VERSION ""

NS_ :

BS_:

BU_:

BO_ 989 CP_loggingSlow: 8 Vector__XXX
 SG_ CP_doorPushLockoutActive m4 : 63|1@1+ (1,0) [0|0] "" Vector__XXX
 SG_ CP_faultLineSetByCP m2 : 62|1@1+ (1,0) [0|0] "" Vector__XXX
 SG_ CP_pilotWakeCounter m6 : 61|3@1+ (1,0) [0|0] "" Vector__XXX
 SG_ CP_proximityWakeCounter m5 : 61|3@1+ (1,0) [0|0] "" Vector__XXX
 SG_ CP_wakeOnPushCounter m4 : 60|3@1+ (1,0) [0|0] "" Vector__XXX
 SG_ CP_backCover2State m1 : 59|3@1+ (1,0) [0|0] "" Vector__XXX
 SG_ CP_inletHeaterDuty m3 : 57|7@1+ (1,0) [0|0] "" Vector__XXX
 SG_ CP_backCoverState m1 : 56|3@1+ (1,0) [0|0] "" Vector__XXX
 SG_ CP_doorCloseLimiterMaxRequestType m5 : 56|5@1+ (1,0) [0|0] "" Vector__XXX
 SG_ CP_uhfDoorRequestCounts m7 : 56|5@1+ (1,0) [0|0] "" Vector__XXX
 SG_ CP_inletHeaterState m3 : 55|2@1+ (1,0) [0|0] "" Vector__XXX
 SG_ CP_acNumRetries m6 : 53|8@1+ (1,0) [0|0] "" Vector__XXX
 SG_ CP_doorCloseLimiterMaxCount m5 : 52|4@1+ (1,0) [0|0] "" Vector__XXX
 SG_ CP_faultLineV m2 : 52|10@1+ (0.004550576735092864,0) [0|0] "" Vector__XXX
 SG_ CP_inlet2HarnessIdValue m3 : 52|3@1+ (1,0) [0|0] "" Vector__XXX
 SG_ CP_inlet2HarnessIdState m3 : 50|2@1+ (1,0) [0|0] "" Vector__XXX
 SG_ CP_inlet2HarnessV m0 : 50|14@1+ (0.001,0) [0|0] "" Vector__XXX
 SG_ CP_doorOpenLimiterMaxRequestType m5 : 48|4@1+ (1,0) [0|0] "" Vector__XXX
 SG_ CP_sensorExtV m1 : 48|8@1+ (0.01968504,0) [0|0] "" Vector__XXX
 SG_ CP_inlet1HarnessIdValue m3 : 47|3@1+ (1,0) [0|0] "" Vector__XXX
 SG_ CP_inlet1HarnessIdState m3 : 45|2@1+ (1,0) [0|0] "" Vector__XXX
 SG_ CP_doorOpenLimiterMaxCount m5 : 44|4@1+ (1,0) [0|0] "" Vector__XXX
 SG_ CP_nvm_pilotDiodeFaultCount m5 : 41|3@1+ (1,0) [0|0] "" Vector__XXX
 SG_ CP_nvm_badPilotDiodeDetected m5 : 40|1@1+ (1,0) [0|0] "" Vector__XXX
 SG_ CP_pilotHighValue_intervalMin10s m2 : 40|12@1- (0.01,0) [0|0] "" Vector__XXX
 SG_ CP_plcV m1 : 40|8@1+ (0.01294118,0) [0|0] "" Vector__XXX
 SG_ CP_nvm_doorPresentValid m5 : 39|1@1+ (1,0) [0|0] "" Vector__XXX
 SG_ CP_acNextRetryTimeoutS m6 : 38|15@1+ (1,0) [0|0] "" Vector__XXX
 SG_ CP_nvm_doorPresent m5 : 38|1@1+ (1,0) [0|0] "" Vector__XXX
 SG_ CP_nvm_doorOpen m5 : 37|1@1+ (1,0) [0|0] "" Vector__XXX
 SG_ CP_doorId_intervalMax10s m4 : 36|8@1+ (0.0196078431372549,0) [0|0] "" Vector__XXX
 SG_ CP_inlet1HarnessV m0 : 36|14@1+ (0.001,0) [0|0] "" Vector__XXX
 SG_ CP_latchI m3 : 33|12@1+ (0.0025,0) [0|0] "" Vector__XXX
 SG_ CP_ivledV m1 : 32|8@1+ (0.01968504,0) [0|0] "" Vector__XXX
 SG_ CP_doorId_intervalMin10s m4 : 28|8@1+ (0.0196078431372549,0) [0|0] "" Vector__XXX
 SG_ CP_inductiveSensorBaseline m7 : 28|28@1+ (0.08083879947662354,0) [0|0] "" Vector__XXX
 SG_ CP_ivledState m1 : 28|2@1+ (1,0) [0|0] "" Vector__XXX
 SG_ CP_pilotHighValue_intervalMax10s m2 : 28|12@1- (0.01,0) [0|0] "" Vector__XXX
 SG_ CP_UHF_selfTestRssi m3 : 25|8@1+ (1,0) [0|0] "" Vector__XXX
 SG_ CP_acRetryTimeoutS m6 : 23|15@1+ (1,0) [0|0] "" Vector__XXX
 SG_ CP_nvm_doorCloseCycles m5 : 21|16@1+ (1,0) [0|0] "" Vector__XXX
 SG_ CP_proximityV_intervalMin10s m0 : 20|16@1+ (0.0001,0) [0|0] "" Vector__XXX
 SG_ CP_refVoltage m4 : 20|8@1+ (0.0070588235,0) [0|0] "" Vector__XXX
 SG_ CP_doorButtonPressDurationMs m7 : 18|10@1+ (1,0) [0|0] "" Vector__XXX
 SG_ CP_UHF_rxNumBytes m3 : 17|8@1+ (1,0) [0|0] "" Vector__XXX
 SG_ CP_UHF_rxOverflow m3 : 16|1@1+ (1,0) [0|0] "" Vector__XXX
 SG_ CP_backCover2Counts m1 : 16|12@1+ (0.025,0) [0|0] "" Vector__XXX
 SG_ CP_pilotLowValue_intervalMin10s m2 : 16|12@1- (0.01,0) [0|0] "" Vector__XXX
 SG_ CP_tlsMemoryUsage_intervalMin10s m6 : 16|7@1+ (0.7874015748031497,0) [0|0] "" Vector__XXX
 SG_ CP_boardTemperature m4 : 12|8@1+ (1.29411764706,-50) [0|0] "" Vector__XXX
 SG_ CP_cpuUtilization_intervalMin10s m7 : 11|7@1+ (0.7874015748031497,0) [0|0] "" Vector__XXX
 SG_ CP_UHF_rssi m3 : 8|8@1+ (1,0) [0|0] "" Vector__XXX
 SG_ CP_tlsMemoryUsage_intervalMax10s m6 : 8|7@1+ (0.7874015748031497,0) [0|0] "" Vector__XXX
 SG_ CP_nvm_doorOpenCycles m5 : 5|16@1+ (1,0) [0|0] "" Vector__XXX
 SG_ CP_5vSwV m4 : 4|8@1+ (0.027450980392156862,0) [0|0] "" Vector__XXX
 SG_ CP_UHF_chipState m3 : 4|3@1+ (1,0) [0|0] "" Vector__XXX
 SG_ CP_backCoverCounts m1 : 4|12@1+ (0.025,0) [0|0] "" Vector__XXX
 SG_ CP_cpuUtilization_intervalMax10s m7 : 4|7@1+ (0.7874015748031497,0) [0|0] "" Vector__XXX
 SG_ CP_nvm_dataValid m5 : 4|1@1+ (1,0) [0|0] "" Vector__XXX
 SG_ CP_pilotLowValue_intervalMax10s m2 : 4|12@1- (0.01,0) [0|0] "" Vector__XXX
 SG_ CP_proximityV_intervalMax10s m0 : 4|16@1+ (0.0001,0) [0|0] "" Vector__XXX
 SG_ CP_loggingSlowSelect M : 0|4@1+ (1,0) [0|0] "" Vector__XXX

BO_ 991 UI_status2: 8 Vector__XXX
 SG_ UI_connectivityStandbyActive : 63|1@1+ (1,0) [0|0] "" Vector__XXX
 SG_ UI_sapClients : 62|1@1+ (1,0) [0|0] "" Vector__XXX
 SG_ UI_sapActive : 61|1@1+ (1,0) [0|0] "" Vector__XXX
 SG_ UI_wakeOnIPActive : 60|1@1+ (1,0) [0|0] "" Vector__XXX
 SG_ UI_sentryModeCameraDetection : 59|1@1+ (1,0) [0|0] "" Vector__XXX
 SG_ UI_fullScreenMode : 58|1@1+ (1,0) [0|0] "" Vector__XXX
 SG_ UI_summonDeviceIndex : 56|2@1+ (1,0) [0|0] "" Vector__XXX
 SG_ UI_selfParkState : 48|8@1+ (1,0) [0|0] "" Vector__XXX
 SG_ UI_sohHealthStatus : 46|2@1+ (1,0) [0|0] "" Vector__XXX
 SG_ UI_wifiBtModuleType : 43|3@1+ (1,0) [0|0] "" Vector__XXX
 SG_ UI_autoshiftDRState : 40|3@1+ (1,0) [0|0] "" Vector__XXX
 SG_ UI_phoneLeftInCabin : 39|1@1+ (1,0) [0|0] "" Vector__XXX
 SG_ UI_mobileAppConnected : 38|1@1+ (1,0) [0|0] "" Vector__XXX
 SG_ UI_autopilotSentryRequest : 37|1@1+ (1,0) [0|0] "" Vector__XXX
 SG_ UI_sentryModeState : 34|3@1+ (1,0) [0|0] "" Vector__XXX
 SG_ UI_linkState : 32|2@1+ (1,0) [0|0] "" Vector__XXX
 SG_ UI_activeTouchPoints : 24|8@1+ (1,0) [0|0] "" Vector__XXX
 SG_ UI_userActivity : 23|1@1+ (1,0) [0|0] "" Vector__XXX
 SG_ UI_displayInDarkMode : 22|1@1+ (1,0) [0|0] "" Vector__XXX
 SG_ UI_locatedAtFavorite : 21|1@1+ (1,0) [0|0] "" Vector__XXX
 SG_ UI_locatedAtWork : 20|1@1+ (1,0) [0|0] "" Vector__XXX
 SG_ UI_locatedAtHome : 19|1@1+ (1,0) [0|0] "" Vector__XXX
 SG_ UI_validDeviceForEUSummon : 18|1@1+ (1,0) [0|0] "" Vector__XXX
 SG_ UI_touchDetected : 17|1@1+ (1,0) [0|0] "" Vector__XXX
 SG_ UI_userRequestSnapshot : 16|1@1+ (1,0) [0|0] "" Vector__XXX
 SG_ UI_mobileAppStepCount : 0|16@1+ (1,0) [0|0] "" Vector__XXX

BO_ 994 VCLEFT_lightStatus: 8 Vector__XXX
 SG_ VCLEFT_tailLightOutageStatus : 51|1@1+ (1,0) [0|0] "" Vector__XXX
 SG_ VCLEFT_reverseTrailerLightStatus : 49|2@1+ (1,0) [0|0] "" Vector__XXX
 SG_ VCLEFT_rideHeightSensorFault : 48|1@1+ (1,0) [0|0] "" Vector__XXX
 SG_ VCLEFT_trailerDetected : 46|2@1+ (1,0) [0|0] "" Vector__XXX
 SG_ VCLEFT_rearRideHeight : 36|8@1- (1,0) [0|0] "" Vector__XXX
 SG_ VCLEFT_frontRideHeight : 28|8@1- (1,0) [0|0] "" Vector__XXX
 SG_ VCLEFT_fogTrailerLightStatus : 26|2@1+ (1,0) [0|0] "" Vector__XXX
 SG_ VCLEFT_tailTrailerLightStatus : 24|2@1+ (1,0) [0|0] "" Vector__XXX
 SG_ VCLEFT_brakeTrailerLightStatus : 22|2@1+ (1,0) [0|0] "" Vector__XXX
 SG_ VCLEFT_rightTrnTrailerLightStatus : 20|2@1+ (1,0) [0|0] "" Vector__XXX
 SG_ VCLEFT_leftTurnTrailerLightStatus : 18|2@1+ (1,0) [0|0] "" Vector__XXX
 SG_ VCLEFT_RRMapLightSwitchPressed : 17|1@1+ (1,0) [0|0] "" Vector__XXX
 SG_ VCLEFT_RLMapLightSwitchPressed : 16|1@1+ (1,0) [0|0] "" Vector__XXX
 SG_ VCLEFT_FRMapLightSwitchPressed : 15|1@1+ (1,0) [0|0] "" Vector__XXX
 SG_ VCLEFT_FLMapLightSwitchPressed : 14|1@1+ (1,0) [0|0] "" Vector__XXX
 SG_ VCLEFT_RRMapLightStatus : 12|2@1+ (1,0) [0|0] "" Vector__XXX
 SG_ VCLEFT_RLMapLightStatus : 10|2@1+ (1,0) [0|0] "" Vector__XXX
 SG_ VCLEFT_FRMapLightStatus : 8|2@1+ (1,0) [0|0] "" Vector__XXX
 SG_ VCLEFT_FLMapLightStatus : 6|2@1+ (1,0) [0|0] "" Vector__XXX
 SG_ VCLEFT_turnSignalStatus : 4|2@1+ (1,0) [0|0] "" Vector__XXX
 SG_ VCLEFT_tailLightStatus : 2|2@1+ (1,0) [0|0] "" Vector__XXX
 SG_ VCLEFT_brakeLightStatus : 0|2@1+ (1,0) [0|0] "" Vector__XXX

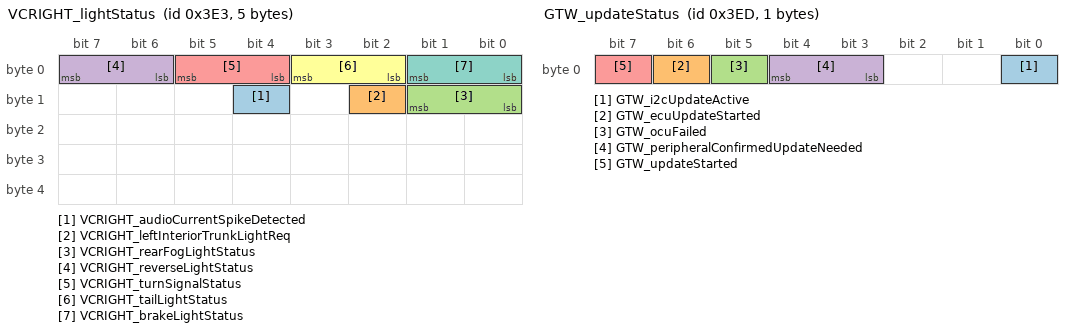
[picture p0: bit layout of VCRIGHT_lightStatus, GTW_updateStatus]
BO_ 995 VCRIGHT_lightStatus: 5 Vector__XXX
 SG_ VCRIGHT_audioCurrentSpikeDetected : 12|1@1+ (1,0) [0|0] "" Vector__XXX
 SG_ VCRIGHT_leftInteriorTrunkLightReq : 10|1@1+ (1,0) [0|0] "" Vector__XXX
 SG_ VCRIGHT_rearFogLightStatus : 8|2@1+ (1,0) [0|0] "" Vector__XXX
 SG_ VCRIGHT_reverseLightStatus : 6|2@1+ (1,0) [0|0] "" Vector__XXX
 SG_ VCRIGHT_turnSignalStatus : 4|2@1+ (1,0) [0|0] "" Vector__XXX
 SG_ VCRIGHT_tailLightStatus : 2|2@1+ (1,0) [0|0] "" Vector__XXX
 SG_ VCRIGHT_brakeLightStatus : 0|2@1+ (1,0) [0|0] "" Vector__XXX

BO_ 1001 DAS_bodyControls: 8 Vector__XXX
 SG_ DAS_bodyControlsChecksum : 56|8@1+ (1,0) [0|0] "" Vector__XXX
 SG_ DAS_bodyControlsCounter : 52|4@1+ (1,0) [0|0] "" Vector__XXX
 SG_ DAS_restrictDoorReleaseRight : 51|1@1+ (1,0) [0|0] "" Vector__XXX
 SG_ DAS_restrictDoorReleaseLeft : 50|1@1+ (1,0) [0|0] "" Vector__XXX
 SG_ DAS_adaptiveHighBeamIsFaulted : 49|1@1+ (1,0) [0|0] "" Vector__XXX
 SG_ DAS_rPillarCamHeaterDutyCycle : 45|4@1+ (0.06666666666666667,0) [0|0] "" Vector__XXX
 SG_ DAS_enableIcrDataCollection : 44|1@1+ (1,0) [0|0] "" Vector__XXX
 SG_ DAS_drivePowerStateRequest : 43|1@1+ (1,0) [0|0] "" Vector__XXX
 SG_ DAS_driverDomeLightRequest : 39|1@1+ (1,0) [0|0] "" Vector__XXX
 SG_ DAS_forwardRadarPowerRequest : 38|1@1+ (1,0) [0|0] "" Vector__XXX
 SG_ DAS_turnIndicatorRequestReason : 33|5@1+ (1,0) [0|0] "" Vector__XXX
 SG_ DAS_autoWiperState : 30|3@1+ (1,0) [0|0] "" Vector__XXX
 SG_ DAS_overrideWiperSetting : 29|1@1+ (1,0) [0|0] "" Vector__XXX
 SG_ DAS_ulcConfirmationRequestActive : 28|1@1+ (1,0) [0|0] "" Vector__XXX
 SG_ DAS_wiperWashRequest : 27|1@1+ (1,0) [0|0] "" Vector__XXX
 SG_ DAS_mirrorFoldRequest : 25|2@1+ (1,0) [0|0] "" Vector__XXX
 SG_ DAS_ahlbOverride : 24|1@1+ (1,0) [0|0] "" Vector__XXX
 SG_ DAS_radarHeaterRequest : 23|1@1+ (1,0) [0|0] "" Vector__XXX
 SG_ DAS_dynamicBrakeLightRequest : 22|1@1+ (1,0) [0|0] "" Vector__XXX
 SG_ DAS_forwardCamHeaterDutyCycle : 18|4@1+ (0.06666666666666667,0) [0|0] "" Vector__XXX
 SG_ DAS_highLowBeamOffReason : 15|3@1+ (1,0) [0|0] "" Vector__XXX
 SG_ DAS_heaterRequest : 13|2@1+ (1,0) [0|0] "" Vector__XXX
 SG_ DAS_highLowBeamDecision : 11|2@1+ (1,0) [0|0] "" Vector__XXX
 SG_ DAS_turnIndicatorRequest : 8|3@1+ (1,0) [0|0] "" Vector__XXX
 SG_ DAS_wiperSpeed : 4|4@1+ (1,0) [0|0] "" Vector__XXX
 SG_ DAS_hazardLightRequest : 2|2@1+ (1,0) [0|0] "" Vector__XXX
 SG_ DAS_headlightRequest : 0|2@1+ (1,0) [0|0] "" Vector__XXX

BO_ 1005 GTW_updateStatus: 1 Vector__XXX
 SG_ GTW_i2cUpdateActive : 0|1@0+ (1,0) [0|0] "" Vector__XXX
 SG_ GTW_ecuUpdateStarted : 6|1@1+ (1,0) [0|0] "" Vector__XXX
 SG_ GTW_ocuFailed : 5|1@1+ (1,0) [0|0] "" Vector__XXX
 SG_ GTW_peripheralConfirmedUpdateNeeded : 4|2@0+ (1,0) [0|0] "" Vector__XXX
 SG_ GTW_updateStarted : 7|1@0+ (1,0) [0|0] "" Vector__XXX

BO_ 1010 BMS_kwhCountersMultiplexed: 8 Vector__XXX
 SG_ BMS_kwhChargeTotalModule1 m4 : 36|28@1+ (0.001,0) [0|0] "" Vector__XXX
 SG_ BMS_kwhChargeTotalModule2 m6 : 36|28@1+ (0.001,0) [0|0] "" Vector__XXX
 SG_ BMS_kwhChargeTotalModule3 m8 : 36|28@1+ (0.001,0) [0|0] "" Vector__XXX
 SG_ BMS_kwhChargeTotalModule4 m10 : 36|28@1+ (0.001,0) [0|0] "" Vector__XXX
 SG_ BMS_kwhDcChargeTotalModule1 m5 : 36|28@1+ (0.001,0) [0|0] "" Vector__XXX
 SG_ BMS_kwhDcChargeTotalModule2 m7 : 36|28@1+ (0.001,0) [0|0] "" Vector__XXX
 SG_ BMS_kwhDcChargeTotalModule3 m9 : 36|28@1+ (0.001,0) [0|0] "" Vector__XXX
 SG_ BMS_kwhDcChargeTotalModule4 m11 : 36|28@1+ (0.001,0) [0|0] "" Vector__XXX
 SG_ BMS_acChargerKwhTotal m0 : 8|32@1+ (0.001,0) [0|0] "" Vector__XXX
 SG_ BMS_dcChargerKwhTotal m1 : 8|32@1+ (0.001,0) [0|0] "" Vector__XXX
 SG_ BMS_kwhAcChargeTotalModule1 m5 : 8|28@1+ (0.001,0) [0|0] "" Vector__XXX
 SG_ BMS_kwhAcChargeTotalModule2 m7 : 8|28@1+ (0.001,0) [0|0] "" Vector__XXX
 SG_ BMS_kwhAcChargeTotalModule3 m9 : 8|28@1+ (0.001,0) [0|0] "" Vector__XXX
 SG_ BMS_kwhAcChargeTotalModule4 m11 : 8|28@1+ (0.001,0) [0|0] "" Vector__XXX
 SG_ BMS_kwhDischargeTotalModule1 m4 : 8|28@1+ (0.001,0) [0|0] "" Vector__XXX
 SG_ BMS_kwhDischargeTotalModule2 m6 : 8|28@1+ (0.001,0) [0|0] "" Vector__XXX
 SG_ BMS_kwhDischargeTotalModule3 m8 : 8|28@1+ (0.001,0) [0|0] "" Vector__XXX
 SG_ BMS_kwhDischargeTotalModule4 m10 : 8|28@1+ (0.001,0) [0|0] "" Vector__XXX
 SG_ BMS_kwhDriveDischargeTotal m3 : 8|32@1+ (0.001,0) [0|0] "" Vector__XXX
 SG_ BMS_kwhRegenChargeTotal m2 : 8|32@1+ (0.001,0) [0|0] "" Vector__XXX
 SG_ BMS_kwhCounter_Id M : 0|4@1+ (1,0) [0|0] "" Vector__XXX

BO_ 1013 VCFRONT_lighting: 8 Vector__XXX
 SG_ VCFRONT_indicatorRightInternal : 52|2@1+ (1,0) [0|0] "" Vector__XXX
 SG_ VCFRONT_indicatorLeftInternal : 50|2@1+ (1,0) [0|0] "" Vector__XXX
 SG_ VC_fastFlashHazardsActive : 49|1@1+ (1,0) [0|0] "" Vector__XXX
 SG_ VCFRONT_lightingCustomState : 44|5@1+ (1,0) [0|0] "" Vector__XXX
 SG_ VCFRONT_highBeamLatchingState : 42|2@1+ (1,0) [0|0] "" Vector__XXX
 SG_ VCFRONT_turnIndicatorStalk : 40|2@1+ (1,0) [0|0] "" Vector__XXX
 SG_ VCFRONT_headlightsReadyOrTimedOut : 39|1@1+ (1,0) [0|0] "" Vector__XXX
 SG_ VCFRONT_frontFogFunctionState : 38|1@1+ (1,0) [0|0] "" Vector__XXX
 SG_ VCFRONT_latchedHighBeamsFunctionState : 37|1@1+ (1,0) [0|0] "" Vector__XXX
 SG_ VCFRONT_intHighBeamsFunctionState : 36|1@1+ (1,0) [0|0] "" Vector__XXX
 SG_ VCFRONT_lightingCoreState : 32|4@1+ (1,0) [0|0] "" Vector__XXX
 SG_ VCFRONT_dynamicBrakeLightState : 30|2@1+ (1,0) [0|0] "" Vector__XXX
 SG_ VCFRONT_highBeamControlState : 28|2@1+ (1,0) [0|0] "" Vector__XXX
 SG_ VCFRONT_hazardSwitchBacklight : 27|1@1+ (1,0) [0|0] "" Vector__XXX
 SG_ VCFRONT_courtesyLightingRequest : 24|1@1+ (1,0) [0|0] "" Vector__XXX
 SG_ VCFRONT_switchLightingBrightness : 16|8@1+ (0.5,0) [0|0] "" Vector__XXX
 SG_ VCFRONT_ambientLightingBrightnes : 8|8@1+ (0.5,0) [0|0] "" Vector__XXX
 SG_ VCFRONT_hazardLightRequest : 4|4@1+ (1,0) [0|0] "" Vector__XXX
 SG_ VCFRONT_indicatorRightRequest : 2|2@1+ (1,0) [0|0] "" Vector__XXX
 SG_ VCFRONT_indicatorLeftRequest : 0|2@1+ (1,0) [0|0] "" Vector__XXX

BO_ 1014 VCFRONT_lightStatus: 8 Vector__XXX
 SG_ VC_hcmrMigrationWindowOpen m0 : 63|1@1+ (1,0) [0|0] "" Vector__XXX
 SG_ VC_hcmrMigrationStallDetectionEnabled m0 : 62|1@1+ (1,0) [0|0] "" Vector__XXX
 SG_ VC_hcmrMigrationMigrationNotStarted m0 : 61|1@1+ (1,0) [0|0] "" Vector__XXX
 SG_ VC_hcmrMigrationOnLVSupport m0 : 60|1@1+ (1,0) [0|0] "" Vector__XXX
 SG_ VC_hcmrMigrationVehicleUpdateActive m0 : 59|1@1+ (1,0) [0|0] "" Vector__XXX
 SG_ VC_hcmrMigrationOTAStateNotActive m0 : 58|1@1+ (1,0) [0|0] "" Vector__XXX
 SG_ VC_hcmrMigrationOTAStateWasActive m0 : 57|1@1+ (1,0) [0|0] "" Vector__XXX
 SG_ VC_hcmrMigrationValidWeather m0 : 56|1@1+ (1,0) [0|0] "" Vector__XXX
 SG_ VCFRONT_headlampRoadClass m1 : 55|2@1+ (1,0) [0|0] "" Vector__XXX
 SG_ VC_hcmlMigrationWindowOpen m0 : 55|1@1+ (1,0) [0|0] "" Vector__XXX
 SG_ VC_hcmlMigrationStallDetectionEnabled m0 : 54|1@1+ (1,0) [0|0] "" Vector__XXX
 SG_ VC_hcmlMigrationMigrationNotStarted m0 : 53|1@1+ (1,0) [0|0] "" Vector__XXX
 SG_ VC_hcmlMigrationOnLVSupport m0 : 52|1@1+ (1,0) [0|0] "" Vector__XXX
 SG_ VC_hcmlMigrationVehicleUpdateActive m0 : 51|1@1+ (1,0) [0|0] "" Vector__XXX
 SG_ VC_hcmlMigrationOTAStateNotActive m0 : 50|1@1+ (1,0) [0|0] "" Vector__XXX
 SG_ VC_hcmlMigrationOTAStateWasActive m0 : 49|1@1+ (1,0) [0|0] "" Vector__XXX
 SG_ VC_hcmlMigrationValidWeather m0 : 48|1@1+ (1,0) [0|0] "" Vector__XXX
 SG_ VCFRONT_headlampBendAngle m1 : 47|8@1- (0.1,0) [0|0] "" Vector__XXX
 SG_ VCFRONT_advancedDrivingBeamStatus m1 : 45|2@1+ (1,0) [0|0] "" Vector__XXX
 SG_ VCFRONT_isBendLightingAvailable m1 : 44|1@1+ (1,0) [0|0] "" Vector__XXX
 SG_ VCFRONT_isAdaptiveHighBeamFaulted m1 : 43|1@1+ (1,0) [0|0] "" Vector__XXX
 SG_ VCFRONT_isAdaptiveHighBeamAvailable m1 : 42|1@1+ (1,0) [0|0] "" Vector__XXX
 SG_ VCFRONT_lightStatusMuxIndex M : 39|3@1+ (1,0) [0|0] "" Vector__XXX
 SG_ VC_leftHeadlampHealth : 36|3@1+ (1,0) [0|0] "" Vector__XXX
 SG_ VC_rightHeadlampHealth : 33|3@1+ (1,0) [0|0] "" Vector__XXX
 SG_ VCFRONT_lowBeamsOnForDRL : 32|1@1+ (1,0) [0|0] "" Vector__XXX
 SG_ VCFRONT_lowBeamRightReadyForAiming : 31|1@1+ (1,0) [0|0] "" Vector__XXX
 SG_ VCFRONT_lowBeamLeftReadyForAiming : 30|1@1+ (1,0) [0|0] "" Vector__XXX
 SG_ VCFRONT_parkRightStatus : 28|2@1+ (1,0) [0|0] "" Vector__XXX
 SG_ VCFRONT_parkLeftStatus : 26|2@1+ (1,0) [0|0] "" Vector__XXX
 SG_ VCFRONT_turnSignalRightStatus : 24|2@1+ (1,0) [0|0] "" Vector__XXX
 SG_ VCFRONT_turnSignalLeftStatus : 22|2@1+ (1,0) [0|0] "" Vector__XXX
 SG_ VCFRONT_sideRepeaterRightStatus : 20|2@1+ (1,0) [0|0] "" Vector__XXX
 SG_ VCFRONT_sideRepeaterLeftStatus : 18|2@1+ (1,0) [0|0] "" Vector__XXX
 SG_ VCFRONT_sideMarkersStatus : 16|2@1+ (1,0) [0|0] "" Vector__XXX
 SG_ VCFRONT_fogRightStatus : 14|2@1+ (1,0) [0|0] "" Vector__XXX
 SG_ VCFRONT_fogLeftStatus : 12|2@1+ (1,0) [0|0] "" Vector__XXX
 SG_ VCFRONT_DRLRightStatus : 10|2@1+ (1,0) [0|0] "" Vector__XXX
 SG_ VCFRONT_DRLLeftStatus : 8|2@1+ (1,0) [0|0] "" Vector__XXX
 SG_ VCFRONT_highBeamRightStatus : 6|2@1+ (1,0) [0|0] "" Vector__XXX
 SG_ VCFRONT_highBeamLeftStatus : 4|2@1+ (1,0) [0|0] "" Vector__XXX
 SG_ VCFRONT_lowBeamRightStatus : 2|2@1+ (1,0) [0|0] "" Vector__XXX
 SG_ VCFRONT_lowBeamLeftStatus : 0|2@1+ (1,0) [0|0] "" Vector__XXX

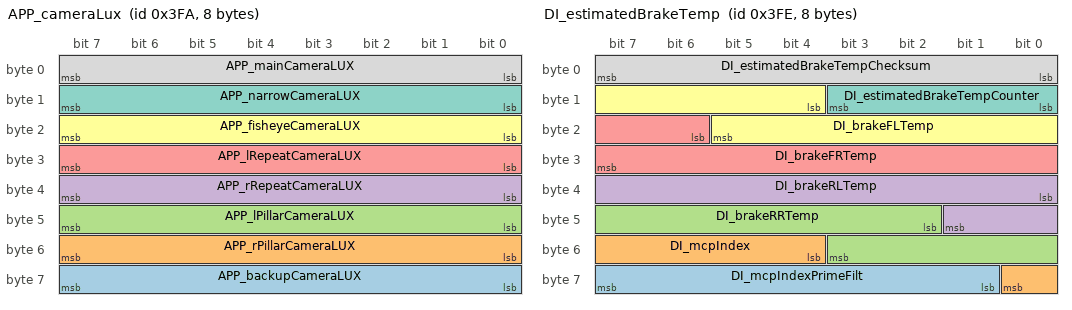
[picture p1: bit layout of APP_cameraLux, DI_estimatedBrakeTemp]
BO_ 1018 APP_cameraLux: 8 CH
 SG_ APP_backupCameraLUX : 56|8@1+ (50,0) [0|0] "lux"  X
 SG_ APP_rPillarCameraLUX : 48|8@1+ (50,0) [0|0] "lux"  X
 SG_ APP_lPillarCameraLUX : 40|8@1+ (50,0) [0|0] "lux"  X
 SG_ APP_rRepeatCameraLUX : 32|8@1+ (50,0) [0|0] "lux"  X
 SG_ APP_lRepeatCameraLUX : 24|8@1+ (50,0) [0|0] "lux"  X
 SG_ APP_fisheyeCameraLUX : 16|8@1+ (50,0) [0|0] "lux"  X
 SG_ APP_narrowCameraLUX : 8|8@1+ (50,0) [0|0] "lux"  X
 SG_ APP_mainCameraLUX : 0|8@1+ (50,0) [0|0] "lux"  X

BO_ 1022 DI_estimatedBrakeTemp: 8 Vector__XXX
 SG_ DI_mcpIndexPrimeFilt : 57|7@1- (0.015,0.9) [0|0] "" Vector__XXX
 SG_ DI_mcpIndex : 52|5@1- (0.05,0.75) [0|0] "" Vector__XXX
 SG_ DI_brakeRRTemp : 42|10@1+ (1,-40) [0|0] "" Vector__XXX
 SG_ DI_brakeRLTemp : 32|10@1+ (1,-40) [0|0] "" Vector__XXX
 SG_ DI_brakeFRTemp : 22|10@1+ (1,-40) [0|0] "" Vector__XXX
 SG_ DI_brakeFLTemp : 12|10@1+ (1,-40) [0|0] "" Vector__XXX
 SG_ DI_estimatedBrakeTempCounter : 8|4@1+ (1,0) [0|0] "" Vector__XXX
 SG_ DI_estimatedBrakeTempChecksum : 0|8@1+ (1,0) [0|0] "" Vector__XXX

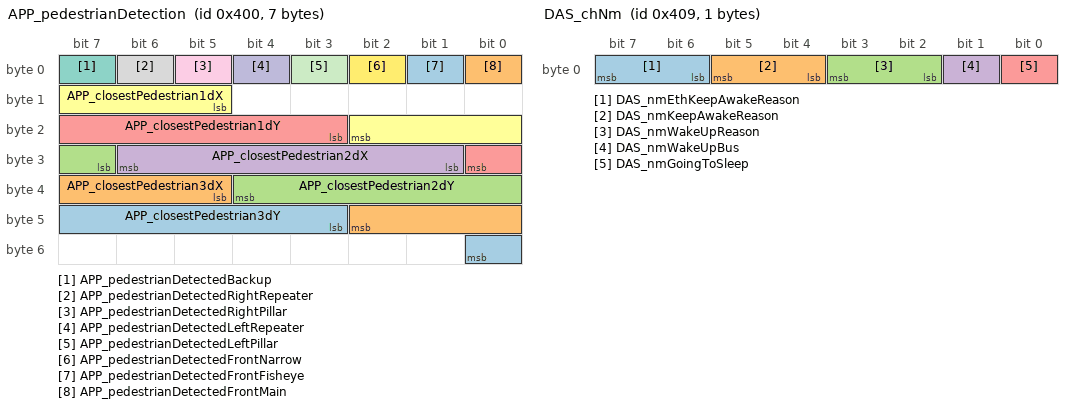
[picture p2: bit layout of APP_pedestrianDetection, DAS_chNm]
BO_ 1024 APP_pedestrianDetection: 7 Vector__XXX
 SG_ APP_closestPedestrian3dY : 43|6@1- (0.4,0) [0|0] "" Vector__XXX
 SG_ APP_closestPedestrian3dX : 37|6@1- (0.4,0) [0|0] "" Vector__XXX
 SG_ APP_closestPedestrian2dY : 31|6@1- (0.4,0) [0|0] "" Vector__XXX
 SG_ APP_closestPedestrian2dX : 25|6@1- (0.4,0) [0|0] "" Vector__XXX
 SG_ APP_closestPedestrian1dY : 19|6@1- (0.4,0) [0|0] "" Vector__XXX
 SG_ APP_closestPedestrian1dX : 13|6@1- (0.4,0) [0|0] "" Vector__XXX
 SG_ APP_pedestrianDetectedBackup : 7|1@1+ (1,0) [0|0] "" Vector__XXX
 SG_ APP_pedestrianDetectedRightRepeater : 6|1@1+ (1,0) [0|0] "" Vector__XXX
 SG_ APP_pedestrianDetectedRightPillar : 5|1@1+ (1,0) [0|0] "" Vector__XXX
 SG_ APP_pedestrianDetectedLeftRepeater : 4|1@1+ (1,0) [0|0] "" Vector__XXX
 SG_ APP_pedestrianDetectedLeftPillar : 3|1@1+ (1,0) [0|0] "" Vector__XXX
 SG_ APP_pedestrianDetectedFrontNarrow : 2|1@1+ (1,0) [0|0] "" Vector__XXX
 SG_ APP_pedestrianDetectedFrontFisheye : 1|1@1+ (1,0) [0|0] "" Vector__XXX
 SG_ APP_pedestrianDetectedFrontMain : 0|1@1+ (1,0) [0|0] "" Vector__XXX

BO_ 1029 GTW_vin: 8 Vector__XXX
 SG_ GTW_vinHigh m16 : 47|24@0+ (1,0) [0|0] "" Vector__XXX
 SG_ GTW_vinLow m18 : 15|56@0+ (1,0) [0|0] "" Vector__XXX
 SG_ GTW_vinMid m17 : 15|56@0+ (1,0) [0|0] "" Vector__XXX
 SG_ GTW_vinIndex M : 7|8@0+ (1,0) [0|0] "" Vector__XXX

BO_ 1031 DAS_bodyControls2: 8 Vector__XXX
 SG_ DAS_windowLockoutMode : 56|3@1+ (1,0) [0|0] "" Vector__XXX
 SG_ DAS_lightingAnimationRequest : 45|3@1+ (1,0) [0|0] "" Vector__XXX
 SG_ DAS_rearTrunkLockRequest : 43|2@1+ (1,0) [0|0] "" Vector__XXX
 SG_ DAS_doorLockRequestRR : 41|2@1+ (1,0) [0|0] "" Vector__XXX
 SG_ DAS_doorLockRequestRL : 39|2@1+ (1,0) [0|0] "" Vector__XXX
 SG_ DAS_doorLockRequestFR : 37|2@1+ (1,0) [0|0] "" Vector__XXX
 SG_ DAS_doorLockRequestFL : 35|2@1+ (1,0) [0|0] "" Vector__XXX
 SG_ DAS_frunkRequest : 33|2@1+ (1,0) [0|0] "" Vector__XXX
 SG_ DAS_windowRequestActiveRR : 32|1@1+ (1,0) [0|0] "" Vector__XXX
 SG_ DAS_windowRequestActiveRL : 31|1@1+ (1,0) [0|0] "" Vector__XXX
 SG_ DAS_windowRequestActiveFR : 30|1@1+ (1,0) [0|0] "" Vector__XXX
 SG_ DAS_windowRequestActiveFL : 29|1@1+ (1,0) [0|0] "" Vector__XXX
 SG_ DAS_windowRequest : 26|3@1+ (1,0) [0|0] "" Vector__XXX
 SG_ DAS_trunkRequest : 24|2@1+ (1,0) [0|0] "" Vector__XXX
 SG_ DAS_hornRequest : 22|2@1+ (1,0) [0|0] "" Vector__XXX
 SG_ DAS_parkingLightDimRequest : 21|1@1+ (1,0) [0|0] "" Vector__XXX
 SG_ DAS_airTankDischargeCmd : 20|1@1+ (1,0) [0|0] "" Vector__XXX
 SG_ DAS_airCleanPillarBackupCmd : 19|1@1+ (1,0) [0|0] "" Vector__XXX
 SG_ DAS_airCleanRepeaterCmd : 18|1@1+ (1,0) [0|0] "" Vector__XXX
 SG_ DAS_fluidCleanPillarBackupCmd : 17|1@1+ (1,0) [0|0] "" Vector__XXX
 SG_ DAS_fluidCleanRightRepeaterCmd : 16|1@1+ (1,0) [0|0] "" Vector__XXX
 SG_ DAS_fluidCleanLeftRepeaterCmd : 15|1@1+ (1,0) [0|0] "" Vector__XXX
 SG_ DAS_fluidCleanFasciaCmd : 14|1@1+ (1,0) [0|0] "" Vector__XXX
 SG_ DAS_narrowWipeRequest : 13|1@1+ (1,0) [0|0] "" Vector__XXX
 SG_ DAS_narrowWiperWashRequest : 12|1@1+ (1,0) [0|0] "" Vector__XXX
 SG_ DAS_bodyControls2Counter : 8|4@1+ (1,0) [0|0] "" Vector__XXX
 SG_ DAS_bodyControls2Checksum : 0|8@1+ (1,0) [0|0] "" Vector__XXX

BO_ 1033 DAS_chNm: 1 Vector__XXX
 SG_ DAS_nmEthKeepAwakeReason : 6|2@1+ (1,0) [0|0] "" Vector__XXX
 SG_ DAS_nmKeepAwakeReason : 4|2@1+ (1,0) [0|0] "" Vector__XXX
 SG_ DAS_nmWakeUpReason : 2|2@1+ (1,0) [0|0] "" Vector__XXX
 SG_ DAS_nmWakeUpBus : 1|1@1+ (1,0) [0|0] "" Vector__XXX
 SG_ DAS_nmGoingToSleep : 0|1@1+ (1,0) [0|0] "" Vector__XXX

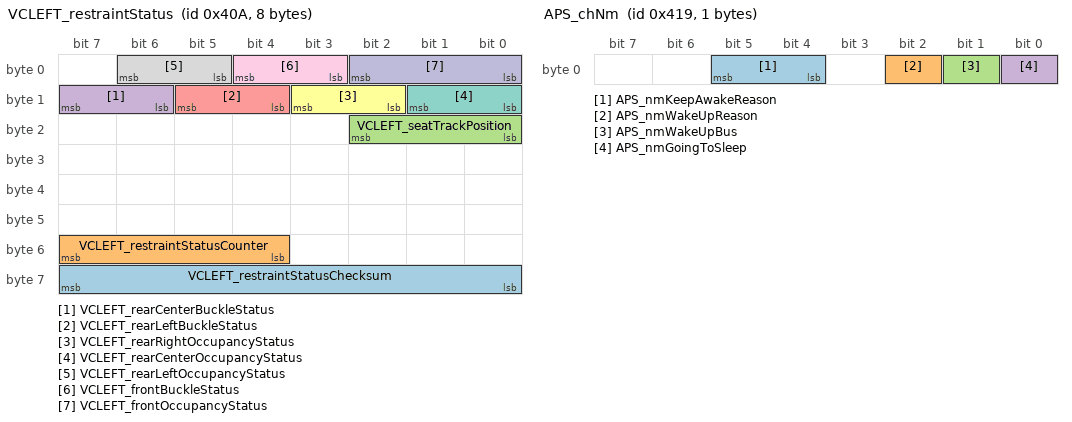
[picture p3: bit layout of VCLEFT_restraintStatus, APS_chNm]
BO_ 1034 VCLEFT_restraintStatus: 8 Vector__XXX
 SG_ VCLEFT_restraintStatusChecksum : 56|8@1+ (1,0) [0|0] "" Vector__XXX
 SG_ VCLEFT_restraintStatusCounter : 52|4@1+ (1,0) [0|0] "" Vector__XXX
 SG_ VCLEFT_seatTrackPosition : 16|3@1+ (1,0) [0|0] "" Vector__XXX
 SG_ VCLEFT_rearCenterBuckleStatus : 14|2@1+ (1,0) [0|0] "" Vector__XXX
 SG_ VCLEFT_rearLeftBuckleStatus : 12|2@1+ (1,0) [0|0] "" Vector__XXX
 SG_ VCLEFT_rearRightOccupancyStatus : 10|2@1+ (1,0) [0|0] "" Vector__XXX
 SG_ VCLEFT_rearCenterOccupancyStatus : 8|2@1+ (1,0) [0|0] "" Vector__XXX
 SG_ VCLEFT_rearLeftOccupancyStatus : 5|2@1+ (1,0) [0|0] "" Vector__XXX
 SG_ VCLEFT_frontBuckleStatus : 3|2@1+ (1,0) [0|0] "" Vector__XXX
 SG_ VCLEFT_frontOccupancyStatus : 0|3@1+ (1,0) [0|0] "" Vector__XXX

BO_ 1044 GTW_chargingID: 8 Vector__XXX
 SG_ GTW_chargingIDHigh m16 : 47|24@0+ (1,0) [0|0] "" Vector__XXX
 SG_ GTW_chargingIDLow m18 : 15|56@0+ (1,0) [0|0] "" Vector__XXX
 SG_ GTW_chargingIDMid m17 : 15|56@0+ (1,0) [0|0] "" Vector__XXX
 SG_ GTW_chargingIDIndex M : 7|8@0+ (1,0) [0|0] "" Vector__XXX

BO_ 1049 APS_chNm: 1 Vector__XXX
 SG_ APS_nmKeepAwakeReason : 4|2@1+ (1,0) [0|0] "" Vector__XXX
 SG_ APS_nmWakeUpReason : 2|1@1+ (1,0) [0|0] "" Vector__XXX
 SG_ APS_nmWakeUpBus : 1|1@1+ (1,0) [0|0] "" Vector__XXX
 SG_ APS_nmGoingToSleep : 0|1@1+ (1,0) [0|0] "" Vector__XXX

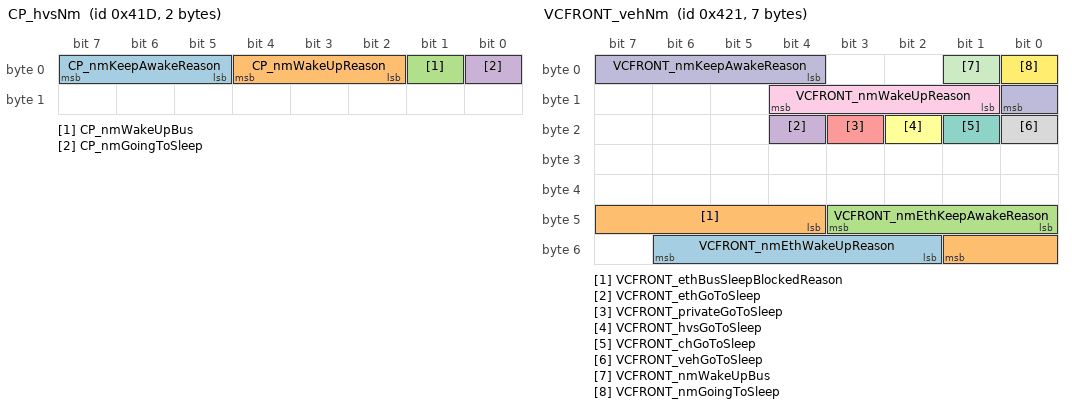
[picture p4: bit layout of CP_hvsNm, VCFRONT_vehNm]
BO_ 1053 CP_hvsNm: 2 Vector__XXX
 SG_ CP_nmKeepAwakeReason : 5|3@1+ (1,0) [0|0] "" Vector__XXX
 SG_ CP_nmWakeUpReason : 2|3@1+ (1,0) [0|0] "" Vector__XXX
 SG_ CP_nmWakeUpBus : 1|1@1+ (1,0) [0|0] "" Vector__XXX
 SG_ CP_nmGoingToSleep : 0|1@1+ (1,0) [0|0] "" Vector__XXX

BO_ 1056 APS_state: 8 Vector__XXX
 SG_ APS_stateCounter : 55|4@1+ (1,0) [0|0] "" Vector__XXX
 SG_ APS_B_faultInduced : 54|1@1+ (1,0) [0|0] "" Vector__XXX
 SG_ APS_A_faultInduced : 53|1@1+ (1,0) [0|0] "" Vector__XXX
 SG_ APS_eplannerState : 50|3@1+ (1,0) [0|0] "" Vector__XXX
 SG_ APS_B_autosteerMonitorState : 47|3@1+ (1,0) [0|0] "" Vector__XXX
 SG_ APS_A_autosteerMonitorState : 44|3@1+ (1,0) [0|0] "" Vector__XXX
 SG_ APS_B_faultState : 39|5@1+ (1,0) [0|0] "" Vector__XXX
 SG_ APS_B_resetState : 36|3@1+ (1,0) [0|0] "" Vector__XXX
 SG_ APS_B_sleepState : 32|4@1+ (1,0) [0|0] "" Vector__XXX
 SG_ APS_B_powerState : 27|5@1+ (1,0) [0|0] "" Vector__XXX
 SG_ APS_B_arbState : 24|3@1+ (1,0) [0|0] "" Vector__XXX
 SG_ APS_secondaryTurbo : 22|2@1+ (1,0) [0|0] "" Vector__XXX
 SG_ APS_A_faultState : 17|5@1+ (1,0) [0|0] "" Vector__XXX
 SG_ APS_A_resetState : 14|3@1+ (1,0) [0|0] "" Vector__XXX
 SG_ APS_A_sleepState : 10|4@1+ (1,0) [0|0] "" Vector__XXX
 SG_ APS_A_powerState : 5|5@1+ (1,0) [0|0] "" Vector__XXX
 SG_ APS_A_arbState : 2|3@1+ (1,0) [0|0] "" Vector__XXX
 SG_ APS_primaryTurbo : 0|2@1+ (1,0) [0|0] "" Vector__XXX

BO_ 1057 VCFRONT_vehNm: 7 Vector__XXX
 SG_ VCFRONT_nmEthWakeUpReason : 50|5@1+ (1,0) [0|0] "" Vector__XXX
 SG_ VCFRONT_ethBusSleepBlockedReason : 44|6@1+ (1,0) [0|0] "" Vector__XXX
 SG_ VCFRONT_nmEthKeepAwakeReason : 40|4@1+ (1,0) [0|0] "" Vector__XXX
 SG_ VCFRONT_ethGoToSleep : 20|1@1+ (1,0) [0|0] "" Vector__XXX
 SG_ VCFRONT_privateGoToSleep : 19|1@1+ (1,0) [0|0] "" Vector__XXX
 SG_ VCFRONT_hvsGoToSleep : 18|1@1+ (1,0) [0|0] "" Vector__XXX
 SG_ VCFRONT_chGoToSleep : 17|1@1+ (1,0) [0|0] "" Vector__XXX
 SG_ VCFRONT_vehGoToSleep : 16|1@1+ (1,0) [0|0] "" Vector__XXX
 SG_ VCFRONT_nmWakeUpReason : 9|4@1+ (1,0) [0|0] "" Vector__XXX
 SG_ VCFRONT_nmKeepAwakeReason : 4|5@1+ (1,0) [0|0] "" Vector__XXX
 SG_ VCFRONT_nmWakeUpBus : 1|1@1+ (1,0) [0|0] "" Vector__XXX
 SG_ VCFRONT_nmGoingToSleep : 0|1@1+ (1,0) [0|0] "" Vector__XXX

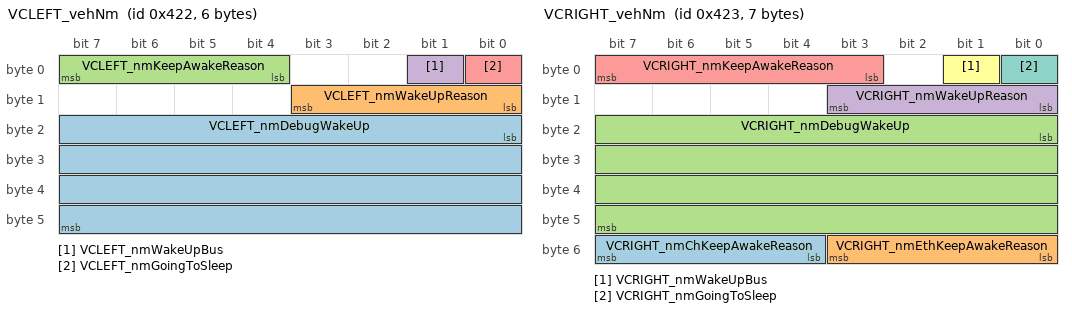
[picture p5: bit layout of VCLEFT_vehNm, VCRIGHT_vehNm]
BO_ 1058 VCLEFT_vehNm: 6 Vector__XXX
 SG_ VCLEFT_nmDebugWakeUp : 16|32@1+ (1,0) [0|0] "" Vector__XXX
 SG_ VCLEFT_nmWakeUpReason : 8|4@1+ (1,0) [0|0] "" Vector__XXX
 SG_ VCLEFT_nmKeepAwakeReason : 4|4@1+ (1,0) [0|0] "" Vector__XXX
 SG_ VCLEFT_nmWakeUpBus : 1|1@1+ (1,0) [0|0] "" Vector__XXX
 SG_ VCLEFT_nmGoingToSleep : 0|1@1+ (1,0) [0|0] "" Vector__XXX

BO_ 1059 VCRIGHT_vehNm: 7 Vector__XXX
 SG_ VCRIGHT_nmChKeepAwakeReason : 52|4@1+ (1,0) [0|0] "" Vector__XXX
 SG_ VCRIGHT_nmEthKeepAwakeReason : 48|4@1+ (1,0) [0|0] "" Vector__XXX
 SG_ VCRIGHT_nmDebugWakeUp : 16|32@1+ (1,0) [0|0] "" Vector__XXX
 SG_ VCRIGHT_nmWakeUpReason : 8|4@1+ (1,0) [0|0] "" Vector__XXX
 SG_ VCRIGHT_nmKeepAwakeReason : 3|5@1+ (1,0) [0|0] "" Vector__XXX
 SG_ VCRIGHT_nmWakeUpBus : 1|1@1+ (1,0) [0|0] "" Vector__XXX
 SG_ VCRIGHT_nmGoingToSleep : 0|1@1+ (1,0) [0|0] "" Vector__XXX

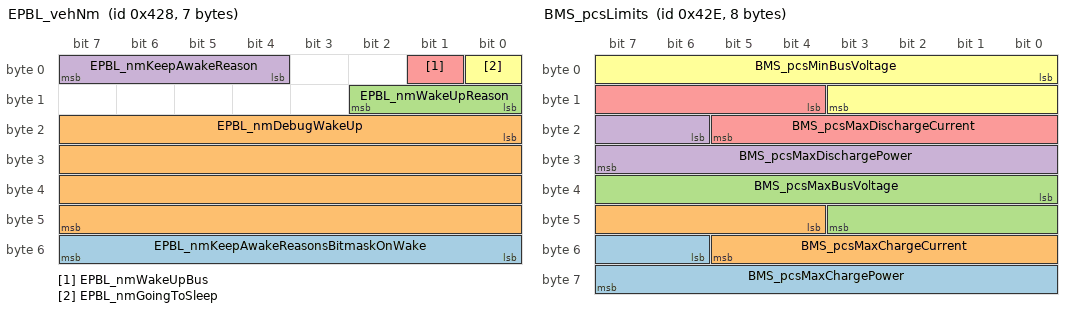
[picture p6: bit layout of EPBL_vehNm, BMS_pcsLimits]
BO_ 1064 EPBL_vehNm: 7 Vector__XXX
 SG_ EPBL_nmKeepAwakeReasonsBitmaskOnWake : 48|8@1+ (1,0) [0|0] "" Vector__XXX
 SG_ EPBL_nmDebugWakeUp : 16|32@1+ (1,0) [0|0] "" Vector__XXX
 SG_ EPBL_nmWakeUpReason : 8|3@1+ (1,0) [0|0] "" Vector__XXX
 SG_ EPBL_nmKeepAwakeReason : 4|4@1+ (1,0) [0|0] "" Vector__XXX
 SG_ EPBL_nmWakeUpBus : 1|1@1+ (1,0) [0|0] "" Vector__XXX
 SG_ EPBL_nmGoingToSleep : 0|1@1+ (1,0) [0|0] "" Vector__XXX

BO_ 1066 VCSEC_TPMSConnectionData: 8 Vector__XXX
 SG_ VCSEC_TPMSSensorPresence3 : 62|2@1+ (1,0) [0|0] "" Vector__XXX
 SG_ VCSEC_TPMSSensorPresence2 : 60|2@1+ (1,0) [0|0] "" Vector__XXX
 SG_ VCSEC_TPMSSensorPresence1 : 58|2@1+ (1,0) [0|0] "" Vector__XXX
 SG_ VCSEC_TPMSSensorPresence0 : 56|2@1+ (1,0) [0|0] "" Vector__XXX
 SG_ VCSEC_TPMSConnectionTypeDesired3 : 54|2@1+ (1,0) [0|0] "" Vector__XXX
 SG_ VCSEC_TPMSConnectionTypeCurrent3 : 52|2@1+ (1,0) [0|0] "" Vector__XXX
 SG_ VCSEC_TPMSRSSI3 : 45|7@1+ (1,-127) [0|0] "" Vector__XXX
 SG_ VCSEC_TPMSSensorState3 : 42|3@1+ (1,0) [0|0] "" Vector__XXX
 SG_ VCSEC_TPMSConnectionTypeDesired2 : 40|2@1+ (1,0) [0|0] "" Vector__XXX
 SG_ VCSEC_TPMSConnectionTypeCurrent2 : 38|2@1+ (1,0) [0|0] "" Vector__XXX
 SG_ VCSEC_TPMSRSSI2 : 31|7@1+ (1,-127) [0|0] "" Vector__XXX
 SG_ VCSEC_TPMSSensorState2 : 28|3@1+ (1,0) [0|0] "" Vector__XXX
 SG_ VCSEC_TPMSConnectionTypeDesired1 : 26|2@1+ (1,0) [0|0] "" Vector__XXX
 SG_ VCSEC_TPMSConnectionTypeCurrent1 : 24|2@1+ (1,0) [0|0] "" Vector__XXX
 SG_ VCSEC_TPMSRSSI1 : 17|7@1+ (1,-127) [0|0] "" Vector__XXX
 SG_ VCSEC_TPMSSensorState1 : 14|3@1+ (1,0) [0|0] "" Vector__XXX
 SG_ VCSEC_TPMSConnectionTypeDesired0 : 12|2@1+ (1,0) [0|0] "" Vector__XXX
 SG_ VCSEC_TPMSConnectionTypeCurrent0 : 10|2@1+ (1,0) [0|0] "" Vector__XXX
 SG_ VCSEC_TPMSRSSI0 : 3|7@1+ (1,-127) [0|0] "" Vector__XXX
 SG_ VCSEC_TPMSSensorState0 : 0|3@1+ (1,0) [0|0] "" Vector__XXX

BO_ 1070 BMS_pcsLimits: 8 Vector__XXX
 SG_ BMS_pcsMaxChargePower : 54|10@1+ (0.025,0) [0|0] "" Vector__XXX
 SG_ BMS_pcsMaxChargeCurrent : 44|10@1+ (0.1,0) [0|0] "" Vector__XXX
 SG_ BMS_pcsMaxBusVoltage : 32|12@1+ (0.25,0) [0|0] "" Vector__XXX
 SG_ BMS_pcsMaxDischargePower : 22|10@1+ (0.025,0) [0|0] "" Vector__XXX
 SG_ BMS_pcsMaxDischargeCurrent : 12|10@1+ (0.1,0) [0|0] "" Vector__XXX
 SG_ BMS_pcsMinBusVoltage : 0|12@1+ (0.25,0) [0|0] "" Vector__XXX

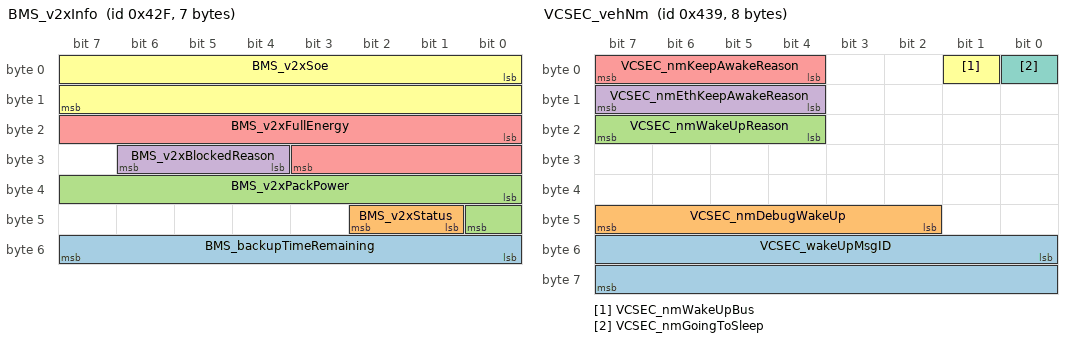
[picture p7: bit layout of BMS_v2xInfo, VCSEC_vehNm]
BO_ 1071 BMS_v2xInfo: 7 Vector__XXX
 SG_ BMS_backupTimeRemaining : 48|8@1+ (1,0) [0|0] "" Vector__XXX
 SG_ BMS_v2xStatus : 41|2@1+ (1,0) [0|0] "" Vector__XXX
 SG_ BMS_v2xPackPower : 32|9@1+ (0.1,-25) [0|0] "" Vector__XXX
 SG_ BMS_v2xBlockedReason : 28|3@1+ (1,0) [0|0] "" Vector__XXX
 SG_ BMS_v2xFullEnergy : 16|12@1+ (0.05,0) [0|0] "" Vector__XXX
 SG_ BMS_v2xSoe : 0|16@1+ (0.002,0) [0|0] "" Vector__XXX

BO_ 1081 VCSEC_vehNm: 8 Vector__XXX
 SG_ VCSEC_wakeUpMsgID : 48|16@1+ (1,0) [0|0] "" Vector__XXX
 SG_ VCSEC_nmDebugWakeUp : 42|6@1+ (1,0) [0|0] "" Vector__XXX
 SG_ VCSEC_nmWakeUpReason : 20|4@1+ (1,0) [0|0] "" Vector__XXX
 SG_ VCSEC_nmEthKeepAwakeReason : 12|4@1+ (1,0) [0|0] "" Vector__XXX
 SG_ VCSEC_nmKeepAwakeReason : 4|4@1+ (1,0) [0|0] "" Vector__XXX
 SG_ VCSEC_nmWakeUpBus : 1|1@1+ (1,0) [0|0] "" Vector__XXX
 SG_ VCSEC_nmGoingToSleep : 0|1@1+ (1,0) [0|0] "" Vector__XXX

BO_ 1082 VCSEC_TPMSLocate: 6 Vector__XXX
 SG_ VCSEC_TPMSLongBiasCount0 m0 : 32|9@1+ (1,0) [0|0] "" Vector__XXX
 SG_ VCSEC_TPMSLongBiasCount1 m2 : 32|9@1+ (1,0) [0|0] "" Vector__XXX
 SG_ VCSEC_TPMSLongBiasCount2 m4 : 32|9@1+ (1,0) [0|0] "" Vector__XXX
 SG_ VCSEC_TPMSLongBiasCount3 m6 : 32|9@1+ (1,0) [0|0] "" Vector__XXX
 SG_ VCSEC_TPMSRRConfidence0 m1 : 32|7@1+ (1,0) [0|0] "" Vector__XXX
 SG_ VCSEC_TPMSRRConfidence1 m3 : 32|7@1+ (1,0) [0|0] "" Vector__XXX
 SG_ VCSEC_TPMSRRConfidence2 m5 : 32|7@1+ (1,0) [0|0] "" Vector__XXX
 SG_ VCSEC_TPMSRRConfidence3 m7 : 32|7@1+ (1,0) [0|0] "" Vector__XXX
 SG_ VCSEC_TPMSRLConfidence0 m1 : 24|7@1+ (1,0) [0|0] "" Vector__XXX
 SG_ VCSEC_TPMSRLConfidence1 m3 : 24|7@1+ (1,0) [0|0] "" Vector__XXX
 SG_ VCSEC_TPMSRLConfidence2 m5 : 24|7@1+ (1,0) [0|0] "" Vector__XXX
 SG_ VCSEC_TPMSRLConfidence3 m7 : 24|7@1+ (1,0) [0|0] "" Vector__XXX
 SG_ VCSEC_TPMSLatBiasCount0 m0 : 23|9@1+ (1,0) [0|0] "" Vector__XXX
 SG_ VCSEC_TPMSLatBiasCount1 m2 : 23|9@1+ (1,0) [0|0] "" Vector__XXX
 SG_ VCSEC_TPMSLatBiasCount2 m4 : 23|9@1+ (1,0) [0|0] "" Vector__XXX
 SG_ VCSEC_TPMSLatBiasCount3 m6 : 23|9@1+ (1,0) [0|0] "" Vector__XXX
 SG_ VCSEC_TPMSFRConfidence0 m1 : 16|7@1+ (1,0) [0|0] "" Vector__XXX
 SG_ VCSEC_TPMSFRConfidence1 m3 : 16|7@1+ (1,0) [0|0] "" Vector__XXX
 SG_ VCSEC_TPMSFRConfidence2 m5 : 16|7@1+ (1,0) [0|0] "" Vector__XXX
 SG_ VCSEC_TPMSFRConfidence3 m7 : 16|7@1+ (1,0) [0|0] "" Vector__XXX
 SG_ VCSEC_TPMSLatBias0 m0 : 16|7@1- (1,0) [0|0] "" Vector__XXX
 SG_ VCSEC_TPMSLatBias1 m2 : 16|7@1- (1,0) [0|0] "" Vector__XXX
 SG_ VCSEC_TPMSLatBias2 m4 : 16|7@1- (1,0) [0|0] "" Vector__XXX
 SG_ VCSEC_TPMSLatBias3 m6 : 16|7@1- (1,0) [0|0] "" Vector__XXX
 SG_ VCSEC_TPMSLocateAlgoHash m8 : 16|32@1+ (1,0) [0|0] "" Vector__XXX
 SG_ VCSEC_TPMSFLConfidence0 m1 : 8|7@1+ (1,0) [0|0] "" Vector__XXX
 SG_ VCSEC_TPMSFLConfidence1 m3 : 8|7@1+ (1,0) [0|0] "" Vector__XXX
 SG_ VCSEC_TPMSFLConfidence2 m5 : 8|7@1+ (1,0) [0|0] "" Vector__XXX
 SG_ VCSEC_TPMSFLConfidence3 m7 : 8|7@1+ (1,0) [0|0] "" Vector__XXX
 SG_ VCSEC_TPMSLocateAlgoVersion m8 : 8|8@1+ (1,0) [0|0] "" Vector__XXX
 SG_ VCSEC_TPMSLongBias0 m0 : 8|7@1- (1,0) [0|0] "" Vector__XXX
 SG_ VCSEC_TPMSLongBias1 m2 : 8|7@1- (1,0) [0|0] "" Vector__XXX
 SG_ VCSEC_TPMSLongBias2 m4 : 8|7@1- (1,0) [0|0] "" Vector__XXX
 SG_ VCSEC_TPMSLongBias3 m6 : 8|7@1- (1,0) [0|0] "" Vector__XXX
 SG_ VCSEC_TPMSLocateIndex M : 0|4@1+ (1,0) [0|0] "" Vector__XXX

BO_ 1083 VCSEC_peripheralOTAStatus: 8 Vector__XXX
 SG_ VCSEC_TPMSUpdateRetryLimitReached0 m0 : 59|1@1+ (1,0) [0|0] "" Vector__XXX
 SG_ VCSEC_TPMSUpdateRetryLimitReached1 m1 : 59|1@1+ (1,0) [0|0] "" Vector__XXX
 SG_ VCSEC_TPMSUpdateRetryLimitReached2 m2 : 59|1@1+ (1,0) [0|0] "" Vector__XXX
 SG_ VCSEC_TPMSUpdateRetryLimitReached3 m3 : 59|1@1+ (1,0) [0|0] "" Vector__XXX
 SG_ VCSEC_TPMSUpdateHasStarted0 m0 : 58|1@1+ (1,0) [0|0] "" Vector__XXX
 SG_ VCSEC_TPMSUpdateHasStarted1 m1 : 58|1@1+ (1,0) [0|0] "" Vector__XXX
 SG_ VCSEC_TPMSUpdateHasStarted2 m2 : 58|1@1+ (1,0) [0|0] "" Vector__XXX
 SG_ VCSEC_TPMSUpdateHasStarted3 m3 : 58|1@1+ (1,0) [0|0] "" Vector__XXX
 SG_ VCSEC_TPMSUpdateHasUpdated0 m0 : 57|1@1+ (1,0) [0|0] "" Vector__XXX
 SG_ VCSEC_TPMSUpdateHasUpdated1 m1 : 57|1@1+ (1,0) [0|0] "" Vector__XXX
 SG_ VCSEC_TPMSUpdateHasUpdated2 m2 : 57|1@1+ (1,0) [0|0] "" Vector__XXX
 SG_ VCSEC_TPMSUpdateHasUpdated3 m3 : 57|1@1+ (1,0) [0|0] "" Vector__XXX
 SG_ VCSEC_keyWhitelistIndexBeingUpdated m4 : 57|5@1+ (1,0) [0|0] "" Vector__XXX
 SG_ VCSEC_KeyfobUpdateExpectReconnect m4 : 56|1@1+ (1,0) [0|0] "" Vector__XXX
 SG_ VCSEC_TPMSUpdateExpectReconnect0 m0 : 56|1@1+ (1,0) [0|0] "" Vector__XXX
 SG_ VCSEC_TPMSUpdateExpectReconnect1 m1 : 56|1@1+ (1,0) [0|0] "" Vector__XXX
 SG_ VCSEC_TPMSUpdateExpectReconnect2 m2 : 56|1@1+ (1,0) [0|0] "" Vector__XXX
 SG_ VCSEC_TPMSUpdateExpectReconnect3 m3 : 56|1@1+ (1,0) [0|0] "" Vector__XXX
 SG_ VCSEC_KeyfobUpdateWaitForFlashCount m4 : 52|4@1+ (1,0) [0|0] "" Vector__XXX
 SG_ VCSEC_TPMSUpdateWaitForFlashCount0 m0 : 52|4@1+ (1,0) [0|0] "" Vector__XXX
 SG_ VCSEC_TPMSUpdateWaitForFlashCount1 m1 : 52|4@1+ (1,0) [0|0] "" Vector__XXX
 SG_ VCSEC_TPMSUpdateWaitForFlashCount2 m2 : 52|4@1+ (1,0) [0|0] "" Vector__XXX
 SG_ VCSEC_TPMSUpdateWaitForFlashCount3 m3 : 52|4@1+ (1,0) [0|0] "" Vector__XXX
 SG_ VCSEC_KeyfobUpdateStalledBlockCount m4 : 48|4@1+ (1,0) [0|0] "" Vector__XXX
 SG_ VCSEC_TPMSUpdateStalledBlockCount0 m0 : 48|4@1+ (1,0) [0|0] "" Vector__XXX
 SG_ VCSEC_TPMSUpdateStalledBlockCount1 m1 : 48|4@1+ (1,0) [0|0] "" Vector__XXX
 SG_ VCSEC_TPMSUpdateStalledBlockCount2 m2 : 48|4@1+ (1,0) [0|0] "" Vector__XXX
 SG_ VCSEC_TPMSUpdateStalledBlockCount3 m3 : 48|4@1+ (1,0) [0|0] "" Vector__XXX
 SG_ VCSEC_KeyfobUpdateLocationSetCount m4 : 44|4@1+ (1,0) [0|0] "" Vector__XXX
 SG_ VCSEC_TPMSUpdateLocationSetCount0 m0 : 44|4@1+ (1,0) [0|0] "" Vector__XXX
 SG_ VCSEC_TPMSUpdateLocationSetCount1 m1 : 44|4@1+ (1,0) [0|0] "" Vector__XXX
 SG_ VCSEC_TPMSUpdateLocationSetCount2 m2 : 44|4@1+ (1,0) [0|0] "" Vector__XXX
 SG_ VCSEC_TPMSUpdateLocationSetCount3 m3 : 44|4@1+ (1,0) [0|0] "" Vector__XXX
 SG_ VCSEC_KeyfobUpdateCRCRequestTimeoutCount m4 : 40|4@1+ (1,0) [0|0] "" Vector__XXX
 SG_ VCSEC_TPMSUpdateCRCRequestTimeoutCount0 m0 : 40|4@1+ (1,0) [0|0] "" Vector__XXX
 SG_ VCSEC_TPMSUpdateCRCRequestTimeoutCount1 m1 : 40|4@1+ (1,0) [0|0] "" Vector__XXX
 SG_ VCSEC_TPMSUpdateCRCRequestTimeoutCount2 m2 : 40|4@1+ (1,0) [0|0] "" Vector__XXX
 SG_ VCSEC_TPMSUpdateCRCRequestTimeoutCount3 m3 : 40|4@1+ (1,0) [0|0] "" Vector__XXX
 SG_ VCSEC_KeyfobUpdateBlockErrorCount m4 : 36|4@1+ (1,0) [0|0] "" Vector__XXX
 SG_ VCSEC_TPMSUpdateBlockErrorCount0 m0 : 36|4@1+ (1,0) [0|0] "" Vector__XXX
 SG_ VCSEC_TPMSUpdateBlockErrorCount1 m1 : 36|4@1+ (1,0) [0|0] "" Vector__XXX
 SG_ VCSEC_TPMSUpdateBlockErrorCount2 m2 : 36|4@1+ (1,0) [0|0] "" Vector__XXX
 SG_ VCSEC_TPMSUpdateBlockErrorCount3 m3 : 36|4@1+ (1,0) [0|0] "" Vector__XXX
 SG_ VCSEC_KeyfobUpdateBlockTimeoutCount m4 : 32|4@1+ (1,0) [0|0] "" Vector__XXX
 SG_ VCSEC_TPMSUpdateBlockTimeoutCount0 m0 : 32|4@1+ (1,0) [0|0] "" Vector__XXX
 SG_ VCSEC_TPMSUpdateBlockTimeoutCount1 m1 : 32|4@1+ (1,0) [0|0] "" Vector__XXX
 SG_ VCSEC_TPMSUpdateBlockTimeoutCount2 m2 : 32|4@1+ (1,0) [0|0] "" Vector__XXX
 SG_ VCSEC_TPMSUpdateBlockTimeoutCount3 m3 : 32|4@1+ (1,0) [0|0] "" Vector__XXX
 SG_ VCSEC_KeyfobUpdateLastRespStatus m4 : 24|8@1+ (1,0) [0|0] "" Vector__XXX
 SG_ VCSEC_TPMSUpdateLastStatus0 m0 : 24|8@1+ (1,0) [0|0] "" Vector__XXX
 SG_ VCSEC_TPMSUpdateLastStatus1 m1 : 24|8@1+ (1,0) [0|0] "" Vector__XXX
 SG_ VCSEC_TPMSUpdateLastStatus2 m2 : 24|8@1+ (1,0) [0|0] "" Vector__XXX
 SG_ VCSEC_TPMSUpdateLastStatus3 m3 : 24|8@1+ (1,0) [0|0] "" Vector__XXX
 SG_ VCSEC_KeyfobUpdateLastTxStatus m4 : 16|8@1+ (1,0) [0|0] "" Vector__XXX
 SG_ VCSEC_TPMSUpdateState0 m0 : 16|8@1+ (1,0) [0|0] "" Vector__XXX
 SG_ VCSEC_TPMSUpdateState1 m1 : 16|8@1+ (1,0) [0|0] "" Vector__XXX
 SG_ VCSEC_TPMSUpdateState2 m2 : 16|8@1+ (1,0) [0|0] "" Vector__XXX
 SG_ VCSEC_TPMSUpdateState3 m3 : 16|8@1+ (1,0) [0|0] "" Vector__XXX
 SG_ VCSEC_KeyfobStagingProgress m4 : 8|7@1+ (1,0) [0|0] "" Vector__XXX
 SG_ VCSEC_TPMSStagingProgress0 m0 : 8|7@1+ (1,0) [0|0] "" Vector__XXX
 SG_ VCSEC_TPMSStagingProgress1 m1 : 8|7@1+ (1,0) [0|0] "" Vector__XXX
 SG_ VCSEC_TPMSStagingProgress2 m2 : 8|7@1+ (1,0) [0|0] "" Vector__XXX
 SG_ VCSEC_TPMSStagingProgress3 m3 : 8|7@1+ (1,0) [0|0] "" Vector__XXX
 SG_ VCSEC_peripheralOTAStatusIndex M : 0|3@1+ (1,0) [0|0] "" Vector__XXX

BO_ 1089 VC_pcsInterface: 8 Vector__XXX
 SG_ VC_pcsInterfaceChecksum : 56|8@1+ (1,0) [0|0] "" Vector__XXX
 SG_ VC_pcsInterfaceCounter : 50|4@1+ (1,0) [0|0] "" Vector__XXX
 SG_ VC_pcsInterfaceMuxIndex M : 48|1@1+ (1,0) [0|0] "" Vector__XXX
 SG_ VC_LVBatteryCannotSupportVehicle m0 : 47|1@1+ (1,0) [0|0] "" Vector__XXX
 SG_ VC_goodForPCSPowerCycle m0 : 46|1@1+ (1,0) [0|0] "" Vector__XXX
 SG_ VC_lvBatteryDischargeRequest m1 : 42|1@1+ (1,0) [0|0] "" Vector__XXX
 SG_ VC_lvHwProtSelfTestActive m1 : 41|1@1+ (1,0) [0|0] "" Vector__XXX
 SG_ VC_defaultPcsLVVoltageTarget m1 : 28|13@1+ (0.01,0) [0|0] "" Vector__XXX
 SG_ VC_pcsLVMaxVoltageLimit m0 : 27|13@1+ (0.01,0) [0|0] "" Vector__XXX
 SG_ VC_pcsLVMaxDchrgCurrentLimit m1 : 16|12@1+ (0.1,0) [0|0] "" Vector__XXX
 SG_ VC_pcsLVMinVoltageLimit m0 : 13|13@1+ (0.01,0) [0|0] "" Vector__XXX
 SG_ VC_pcsLVVoltageTarget m0 : 0|13@1+ (0.01,0) [0|0] "" Vector__XXX
 SG_ VC_pcsResistanceFiltered m1 : 0|16@1+ (0.01,0) [0|0] "" Vector__XXX

BO_ 1091 VC_pcsManagement: 6 Vector__XXX
 SG_ VC_dcdcLVInputPowerLimit m0 : 36|8@1+ (50,0) [0|0] "" Vector__XXX
 SG_ VC_dcdcLVVoltageTargetMin m0 : 26|10@1+ (0.1,0) [0|0] "" Vector__XXX
 SG_ VC_dcdcLVVoltageTargetMax m0 : 16|10@1+ (0.1,0) [0|0] "" Vector__XXX
 SG_ VC_pcsManagementMuxIndex M : 12|1@1+ (1,0) [0|0] "" Vector__XXX
 SG_ VC_pcsManagementCounter : 8|4@1+ (1,0) [0|0] "" Vector__XXX
 SG_ VC_pcsManagementChecksum : 0|8@1+ (1,0) [0|0] "" Vector__XXX

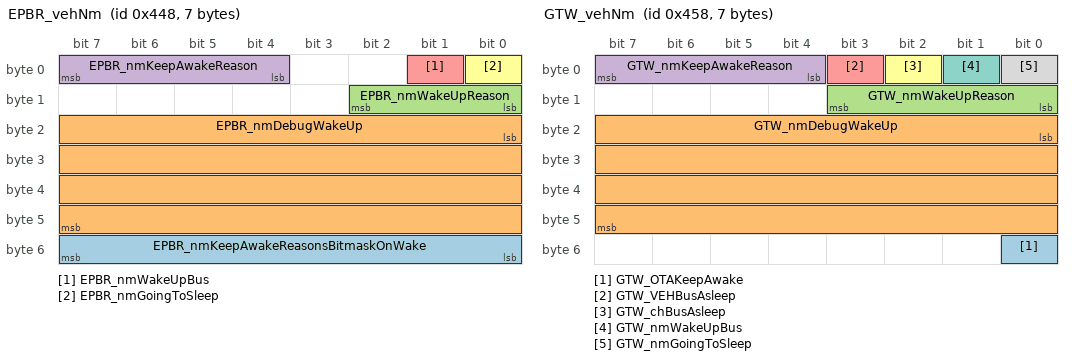
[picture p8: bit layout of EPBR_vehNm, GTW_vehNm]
BO_ 1096 EPBR_vehNm: 7 Vector__XXX
 SG_ EPBR_nmKeepAwakeReasonsBitmaskOnWake : 48|8@1+ (1,0) [0|0] "" Vector__XXX
 SG_ EPBR_nmDebugWakeUp : 16|32@1+ (1,0) [0|0] "" Vector__XXX
 SG_ EPBR_nmWakeUpReason : 8|3@1+ (1,0) [0|0] "" Vector__XXX
 SG_ EPBR_nmKeepAwakeReason : 4|4@1+ (1,0) [0|0] "" Vector__XXX
 SG_ EPBR_nmWakeUpBus : 1|1@1+ (1,0) [0|0] "" Vector__XXX
 SG_ EPBR_nmGoingToSleep : 0|1@1+ (1,0) [0|0] "" Vector__XXX

BO_ 1106 BMS_voltageRegGain: 3 Vector__XXX
 SG_ BMS_driveGainKi : 10|11@1+ (1,0) [0|0] "" Vector__XXX
 SG_ BMS_driveGainKp : 0|10@1+ (8,0) [0|0] "" Vector__XXX

BO_ 1107 VEH_billing: 4 Vector__XXX
 SG_ VEH_pricebookId : 0|32@1+ (1,0) [0|0] "" Vector__XXX

BO_ 1112 GTW_vehNm: 7 VEH
 SG_ GTW_OTAKeepAwake : 48|1@1+ (1,0) [0|0] ""  X
 SG_ GTW_nmDebugWakeUp : 16|32@1+ (1,0) [0|0] ""  X
 SG_ GTW_nmWakeUpReason : 8|4@1+ (1,0) [0|0] ""  X
 SG_ GTW_nmKeepAwakeReason : 4|4@1+ (1,0) [0|0] ""  X
 SG_ GTW_VEHBusAsleep : 3|1@1+ (1,0) [0|0] ""  X
 SG_ GTW_chBusAsleep : 2|1@1+ (1,0) [0|0] ""  X
 SG_ GTW_nmWakeUpBus : 1|1@1+ (1,0) [0|0] ""  X
 SG_ GTW_nmGoingToSleep : 0|1@1+ (1,0) [0|0] ""  X

BO_ 1114 VCRIGHT_AP_hvacState10Hz: 8 Vector__XXX
 SG_ VCRIGHT_AP_solarFluxOnLeftWindow m1 : 56|8@1+ (5,0) [0|0] "" Vector__XXX
 SG_ VCRIGHT_AP_tempDuctDefrost m0 : 56|8@1+ (0.5,-22) [0|0] "" Vector__XXX
 SG_ VCRIGHT_AP_hvacMassflowTarget m0 : 48|8@1+ (1,0) [0|0] "" Vector__XXX
 SG_ VCRIGHT_AP_solarFluxOnRightWindow m1 : 48|8@1+ (5,0) [0|0] "" Vector__XXX
 SG_ VCRIGHT_AP_hvacEstimateWindshieldRH m0 : 40|8@1+ (1,0) [0|0] "" Vector__XXX
 SG_ VCRIGHT_AP_turnCameraFanOffReason m1 : 38|3@1+ (1,0) [0|0] "" Vector__XXX
 SG_ VCRIGHT_AP_hvacAirDistributionMode m0 : 37|3@1+ (1,0) [0|0] "" Vector__XXX
 SG_ VCRIGHT_AP_turnForwardCameraHeaterOnReason m1 : 34|4@1+ (1,0) [0|0] "" Vector__XXX
 SG_ VCRIGHT_AP_hvacRecircDoorPercent m0 : 31|6@1+ (1.6,0) [0|0] "" Vector__XXX
 SG_ VCRIGHT_ah_defogSystemState m1 : 31|3@1+ (1,0) [0|0] "" Vector__XXX
 SG_ VCRIGHT_AP_cameraFanDutyRequest m1 : 24|7@1+ (1,0) [0|0] "" Vector__XXX
 SG_ VCRIGHT_AP_cabinTempSideGlassLeft m0 : 23|8@1+ (0.5,-40) [0|0] "" Vector__XXX
 SG_ VCRIGHT_ah_defoggingTimeNeeded m1 : 19|5@1+ (1,0) [0|0] "" Vector__XXX
 SG_ VCRIGHT_AP_cabinTempSideGlassRight m0 : 15|8@1+ (0.5,-40) [0|0] "" Vector__XXX
 SG_ VCRIGHT_ah_hvacFaultSurvivabilityTime m1 : 14|5@1+ (10,0) [0|0] "" Vector__XXX
 SG_ VCRIGHT_AP_cameraDefogType m1 : 11|3@1+ (1,0) [0|0] "" Vector__XXX
 SG_ VCRIGHT_AP_cabinTempWindshield m0 : 7|8@1+ (0.5,-40) [0|0] "" Vector__XXX
 SG_ VCRIGHT_AP_hvacModelInitStatus m0 : 4|3@1+ (1,0) [0|0] "" Vector__XXX
 SG_ VCRIGHT_AP_hvacFlashFoggingDetected m0 : 3|1@1+ (1,0) [0|0] "" Vector__XXX
 SG_ VCRIGHT_AP_autoDefogAvailable m0 : 2|1@1+ (1,0) [0|0] "" Vector__XXX
 SG_ VCRIGHT_AP_cameraTurnOnTime m1 : 2|9@1+ (5,0) [0|0] "" Vector__XXX
 SG_ VCRIGHT_AP_hvacState10HzIndex M : 0|2@1+ (1,0) [0|0] "" Vector__XXX

BO_ 1115 VCRIGHT_AP_hvacState0Point1Hz: 2 Vector__XXX
 SG_ VCRIGHT_AP_VOCPurgeRunCount m0 : 2|10@1+ (1,0) [0|0] "" Vector__XXX
 SG_ VCRIGHT_AP_hvacState0Point1HzIndex M : 0|1@1+ (1,0) [0|0] "" Vector__XXX

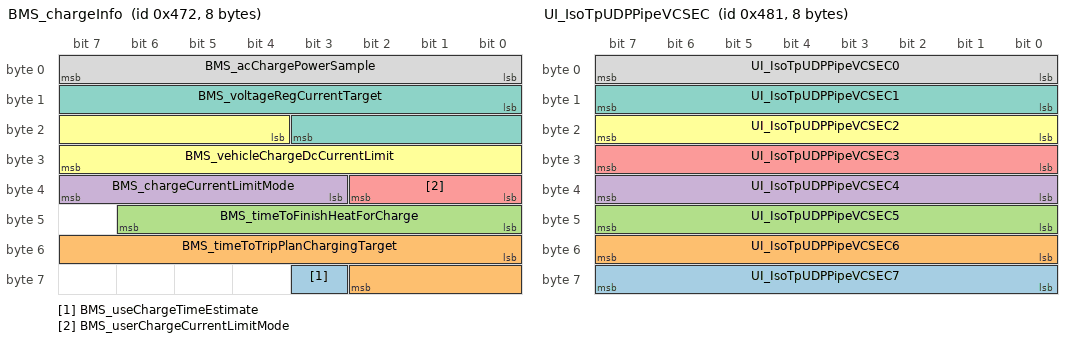
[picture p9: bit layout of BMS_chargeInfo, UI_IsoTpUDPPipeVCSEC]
BO_ 1138 BMS_chargeInfo: 8 Vector__XXX
 SG_ BMS_useChargeTimeEstimate : 59|1@1+ (1,0) [0|0] "" Vector__XXX
 SG_ BMS_timeToTripPlanChargingTarget : 48|11@1+ (1,0) [0|0] "" Vector__XXX
 SG_ BMS_timeToFinishHeatForCharge : 40|7@1+ (5,0) [0|0] "" Vector__XXX
 SG_ BMS_chargeCurrentLimitMode : 35|5@1+ (1,0) [0|0] "" Vector__XXX
 SG_ BMS_userChargeCurrentLimitMode : 32|3@1+ (1,0) [0|0] "" Vector__XXX
 SG_ BMS_vehicleChargeDcCurrentLimit : 20|12@1+ (0.5,0) [0|0] "" Vector__XXX
 SG_ BMS_voltageRegCurrentTarget : 8|12@1+ (0.5,0) [0|0] "" Vector__XXX
 SG_ BMS_acChargePowerSample : 0|8@1+ (0.1,0) [0|0] "" Vector__XXX

BO_ 1139 UI_ethNm: 8 Vector__XXX
 SG_ UI_wakeupTime : 32|32@1+ (1,0) [0|0] "" Vector__XXX
 SG_ UI_nmKeepAwakeReason : 16|6@1+ (1,0) [0|0] "" Vector__XXX
 SG_ UI_nmGoingToSleep : 0|1@1+ (1,0) [0|0] "" Vector__XXX

BO_ 1153 UI_IsoTpUDPPipeVCSEC: 8 Vector__XXX
 SG_ UI_IsoTpUDPPipeVCSEC7 : 63|8@0+ (1,0) [0|0] "" Vector__XXX
 SG_ UI_IsoTpUDPPipeVCSEC6 : 55|8@0+ (1,0) [0|0] "" Vector__XXX
 SG_ UI_IsoTpUDPPipeVCSEC5 : 47|8@0+ (1,0) [0|0] "" Vector__XXX
 SG_ UI_IsoTpUDPPipeVCSEC4 : 39|8@0+ (1,0) [0|0] "" Vector__XXX
 SG_ UI_IsoTpUDPPipeVCSEC3 : 31|8@0+ (1,0) [0|0] "" Vector__XXX
 SG_ UI_IsoTpUDPPipeVCSEC2 : 23|8@0+ (1,0) [0|0] "" Vector__XXX
 SG_ UI_IsoTpUDPPipeVCSEC1 : 15|8@0+ (1,0) [0|0] "" Vector__XXX
 SG_ UI_IsoTpUDPPipeVCSEC0 : 7|8@0+ (1,0) [0|0] "" Vector__XXX

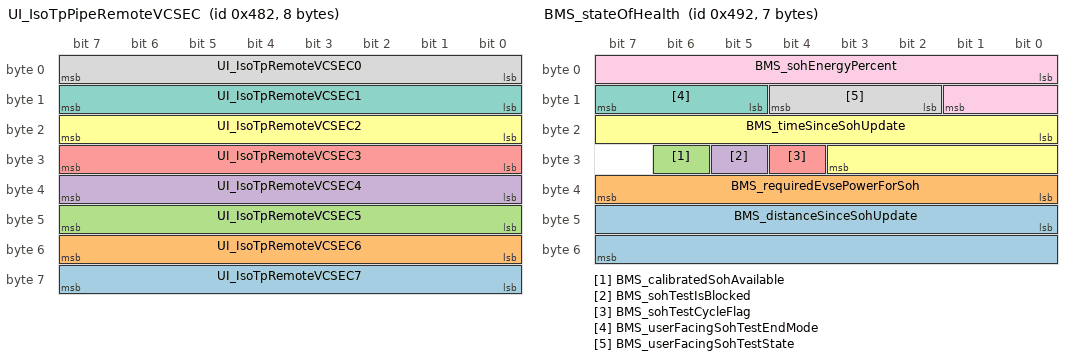
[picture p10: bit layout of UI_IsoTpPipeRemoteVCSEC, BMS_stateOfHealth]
BO_ 1154 UI_IsoTpPipeRemoteVCSEC: 8 Vector__XXX
 SG_ UI_IsoTpRemoteVCSEC7 : 63|8@0+ (1,0) [0|0] "" Vector__XXX
 SG_ UI_IsoTpRemoteVCSEC6 : 55|8@0+ (1,0) [0|0] "" Vector__XXX
 SG_ UI_IsoTpRemoteVCSEC5 : 47|8@0+ (1,0) [0|0] "" Vector__XXX
 SG_ UI_IsoTpRemoteVCSEC4 : 39|8@0+ (1,0) [0|0] "" Vector__XXX
 SG_ UI_IsoTpRemoteVCSEC3 : 31|8@0+ (1,0) [0|0] "" Vector__XXX
 SG_ UI_IsoTpRemoteVCSEC2 : 23|8@0+ (1,0) [0|0] "" Vector__XXX
 SG_ UI_IsoTpRemoteVCSEC1 : 15|8@0+ (1,0) [0|0] "" Vector__XXX
 SG_ UI_IsoTpRemoteVCSEC0 : 7|8@0+ (1,0) [0|0] "" Vector__XXX

BO_ 1170 BMS_stateOfHealth: 7 Vector__XXX
 SG_ BMS_distanceSinceSohUpdate : 40|16@1+ (1,0) [0|0] "" Vector__XXX
 SG_ BMS_requiredEvsePowerForSoh : 32|8@1+ (0.125,0) [0|0] "" Vector__XXX
 SG_ BMS_calibratedSohAvailable : 30|1@1+ (1,0) [0|0] "" Vector__XXX
 SG_ BMS_sohTestIsBlocked : 29|1@1+ (1,0) [0|0] "" Vector__XXX
 SG_ BMS_sohTestCycleFlag : 28|1@1+ (1,0) [0|0] "" Vector__XXX
 SG_ BMS_timeSinceSohUpdate : 16|12@1+ (1,0) [0|0] "" Vector__XXX
 SG_ BMS_userFacingSohTestEndMode : 13|3@1+ (1,0) [0|0] "" Vector__XXX
 SG_ BMS_userFacingSohTestState : 10|3@1+ (1,0) [0|0] "" Vector__XXX
 SG_ BMS_sohEnergyPercent : 0|10@1+ (0.1,0) [0|0] "" Vector__XXX

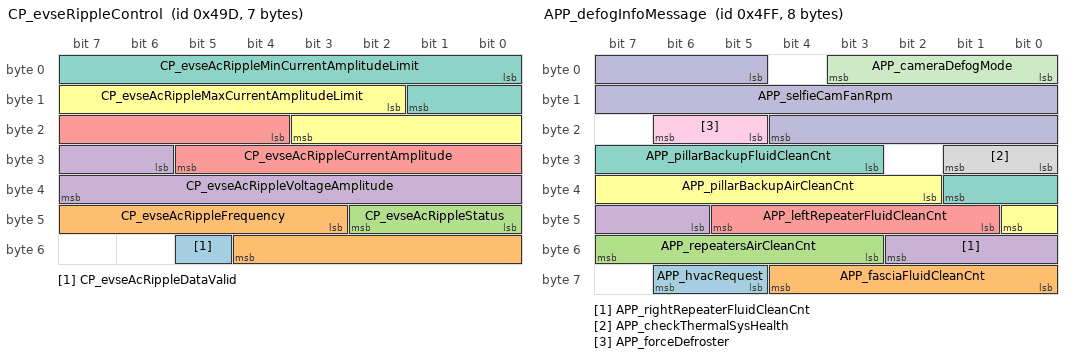
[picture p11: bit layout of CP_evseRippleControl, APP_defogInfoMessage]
BO_ 1181 CP_evseRippleControl: 7 Vector__XXX
 SG_ CP_evseAcRippleDataValid : 53|1@1+ (1,0) [0|0] "" Vector__XXX
 SG_ CP_evseAcRippleFrequency : 43|10@1+ (1,0) [0|0] "" Vector__XXX
 SG_ CP_evseAcRippleStatus : 40|3@1+ (1,0) [0|0] "" Vector__XXX
 SG_ CP_evseAcRippleVoltageAmplitude : 30|10@1+ (1,0) [0|0] "" Vector__XXX
 SG_ CP_evseAcRippleCurrentAmplitude : 20|10@1+ (1,0) [0|0] "" Vector__XXX
 SG_ CP_evseAcRippleMaxCurrentAmplitudeLimit : 10|10@1+ (1,0) [0|0] "" Vector__XXX
 SG_ CP_evseAcRippleMinCurrentAmplitudeLimit : 0|10@1+ (1,0) [0|0] "" Vector__XXX

BO_ 1250 VCLEFT_seatStatus: 8 Vector__XXX
 SG_ VCLEFT_lumbarDevMaxPumpPressB m4 : 60|1@1+ (1,0) [0|0] "" Vector__XXX
 SG_ VCLEFT_lumbarDevMaxPumpPressA m4 : 59|1@1+ (1,0) [0|0] "" Vector__XXX
 SG_ VCLEFT_lumbarGeneralErr m4 : 58|1@1+ (1,0) [0|0] "" Vector__XXX
 SG_ VCLEFT_lumbarMinPErr m4 : 57|1@1+ (1,0) [0|0] "" Vector__XXX
 SG_ VCLEFT_lumbarMaxOperatingPErr m4 : 56|1@1+ (1,0) [0|0] "" Vector__XXX
 SG_ VCLEFT_frontSeatBackPercentage m1 : 55|7@1+ (1,0) [0|0] "" Vector__XXX
 SG_ VCLEFT_frontSeatLiftPercentage m2 : 55|7@1+ (1,0) [0|0] "" Vector__XXX
 SG_ VCLEFT_frontSeatTiltPercentage m3 : 55|7@1+ (1,0) [0|0] "" Vector__XXX
 SG_ VCLEFT_frontSeatTrackPercentage m0 : 55|7@1+ (1,0) [0|0] "" Vector__XXX
 SG_ VCLEFT_lumbarOvercurrentErr m4 : 55|1@1+ (1,0) [0|0] "" Vector__XXX
 SG_ VCLEFT_lumbarMaxPErr m4 : 54|1@1+ (1,0) [0|0] "" Vector__XXX
 SG_ VCLEFT_frontSeatBackBridgeSt m1 : 53|2@1+ (1,0) [0|0] "" Vector__XXX
 SG_ VCLEFT_frontSeatLiftBridgeSt m2 : 53|2@1+ (1,0) [0|0] "" Vector__XXX
 SG_ VCLEFT_frontSeatTiltBridgeSt m3 : 53|2@1+ (1,0) [0|0] "" Vector__XXX
 SG_ VCLEFT_frontSeatTrackBridgeSt m0 : 53|2@1+ (1,0) [0|0] "" Vector__XXX
 SG_ VCLEFT_lumbarActiveTooLongErr m4 : 53|1@1+ (1,0) [0|0] "" Vector__XXX
 SG_ VCLEFT_frontSeatBackLog m1 : 52|1@1+ (1,0) [0|0] "" Vector__XXX
 SG_ VCLEFT_frontSeatLiftLog m2 : 52|1@1+ (1,0) [0|0] "" Vector__XXX
 SG_ VCLEFT_frontSeatTiltLog m3 : 52|1@1+ (1,0) [0|0] "" Vector__XXX
 SG_ VCLEFT_frontSeatTrackLog m0 : 52|1@1+ (1,0) [0|0] "" Vector__XXX
 SG_ VCLEFT_frontSeatBackCalibrated m1 : 51|1@1+ (1,0) [0|0] "" Vector__XXX
 SG_ VCLEFT_frontSeatLiftCalibrated m2 : 51|1@1+ (1,0) [0|0] "" Vector__XXX
 SG_ VCLEFT_frontSeatTiltCalibrated m3 : 51|1@1+ (1,0) [0|0] "" Vector__XXX
 SG_ VCLEFT_frontSeatTrackCalibrated m0 : 51|1@1+ (1,0) [0|0] "" Vector__XXX
 SG_ VCLEFT_frontSeatBackState m1 : 48|3@1+ (1,0) [0|0] "" Vector__XXX
 SG_ VCLEFT_frontSeatLiftState m2 : 48|3@1+ (1,0) [0|0] "" Vector__XXX
 SG_ VCLEFT_frontSeatTiltState m3 : 48|3@1+ (1,0) [0|0] "" Vector__XXX
 SG_ VCLEFT_frontSeatTrackState m0 : 48|3@1+ (1,0) [0|0] "" Vector__XXX
 SG_ VCLEFT_lumbarBPressureHpaFilt m4 : 43|10@1+ (1,0) [0|0] "" Vector__XXX
 SG_ VCLEFT_frontSeatTiltPosOffset m6 : 40|12@1- (0.1,0) [0|0] "" Vector__XXX
 SG_ VCLEFT_frontSeatTiltPosReal m5 : 40|12@1- (0.1,0) [0|0] "" Vector__XXX
 SG_ VCLEFT_frontSeatBackDuty m1 : 36|12@1- (0.1,0) [0|0] "" Vector__XXX
 SG_ VCLEFT_frontSeatLiftDuty m2 : 36|12@1- (0.1,0) [0|0] "" Vector__XXX
 SG_ VCLEFT_frontSeatTiltDuty m3 : 36|12@1- (0.1,0) [0|0] "" Vector__XXX
 SG_ VCLEFT_frontSeatTrackDuty m0 : 36|12@1- (0.1,0) [0|0] "" Vector__XXX
 SG_ VCLEFT_lumbarBPressureHpa m4 : 31|12@1+ (1,0) [0|0] "" Vector__XXX
 SG_ VCLEFT_frontSeatLiftPosOffset m6 : 28|12@1- (1,0) [0|0] "" Vector__XXX
 SG_ VCLEFT_frontSeatLiftPosReal m5 : 28|12@1- (1,0) [0|0] "" Vector__XXX
 SG_ VCLEFT_frontSeatBackCurrent m1 : 24|12@1- (0.01,0) [0|0] "" Vector__XXX
 SG_ VCLEFT_frontSeatLiftCurrent m2 : 24|12@1- (0.01,0) [0|0] "" Vector__XXX
 SG_ VCLEFT_frontSeatTiltCurrent m3 : 24|12@1- (0.01,0) [0|0] "" Vector__XXX
 SG_ VCLEFT_frontSeatTrackCurrent m0 : 24|12@1- (0.01,0) [0|0] "" Vector__XXX
 SG_ VCLEFT_lumbarAPressureHpaFilt m4 : 21|10@1+ (1,0) [0|0] "" Vector__XXX
 SG_ VCLEFT_frontSeatBackPosOffset m6 : 16|12@1- (0.1,0) [0|0] "" Vector__XXX
 SG_ VCLEFT_frontSeatBackPosReal m5 : 16|12@1- (0.1,0) [0|0] "" Vector__XXX
 SG_ VCLEFT_lumbarBPressurePercentage m7 : 10|7@1+ (1,0) [0|0] "" Vector__XXX
 SG_ VCLEFT_lumbarAPressureHpa m4 : 9|12@1+ (1,0) [0|0] "" Vector__XXX
 SG_ VCLEFT_frontSeatBackPos m1 : 8|16@1- (1,0) [0|0] "" Vector__XXX
 SG_ VCLEFT_frontSeatLiftPos m2 : 8|16@1- (1,0) [0|0] "" Vector__XXX
 SG_ VCLEFT_frontSeatTiltPos m3 : 8|16@1- (1,0) [0|0] "" Vector__XXX
 SG_ VCLEFT_frontSeatTrackPos m0 : 8|16@1- (1,0) [0|0] "" Vector__XXX
 SG_ VCLEFT_lumbarBState m4 : 6|3@1+ (1,0) [0|0] "" Vector__XXX
 SG_ VC_AH_1RowLeftSeatMovementHealth m0 : 5|3@1+ (1,0) [0|0] "" Vector__XXX
 SG_ VCLEFT_frontSeatTrackPosOffset m6 : 3|12@1- (1,0) [0|0] "" Vector__XXX
 SG_ VCLEFT_frontSeatTrackPosReal m5 : 3|12@1- (1,0) [0|0] "" Vector__XXX
 SG_ VCLEFT_lumbarAPressurePercentage m7 : 3|7@1+ (1,0) [0|0] "" Vector__XXX
 SG_ VCLEFT_lumbarAState m4 : 3|3@1+ (1,0) [0|0] "" Vector__XXX
 SG_ VCLEFT_seatStatusIndex M : 0|3@1+ (1,0) [0|0] "" Vector__XXX

BO_ 1251 VCRIGHT_seatStatus: 8 Vector__XXX
 SG_ VCRIGHT_lumbarDevMaxPumpPressB m4 : 60|1@1+ (1,0) [0|0] "" Vector__XXX
 SG_ VCRIGHT_lumbarDevMaxPumpPressA m4 : 59|1@1+ (1,0) [0|0] "" Vector__XXX
 SG_ VCRIGHT_lumbarGeneralErr m4 : 58|1@1+ (1,0) [0|0] "" Vector__XXX
 SG_ VCRIGHT_lumbarMinPErr m4 : 57|1@1+ (1,0) [0|0] "" Vector__XXX
 SG_ VCRIGHT_lumbarMaxOperatingPErr m4 : 56|1@1+ (1,0) [0|0] "" Vector__XXX
 SG_ VCRIGHT_frontSeatBackPercentage m1 : 55|7@1+ (1,0) [0|0] "" Vector__XXX
 SG_ VCRIGHT_frontSeatLiftPercentage m2 : 55|7@1+ (1,0) [0|0] "" Vector__XXX
 SG_ VCRIGHT_frontSeatTiltPercentage m3 : 55|7@1+ (1,0) [0|0] "" Vector__XXX
 SG_ VCRIGHT_frontSeatTrackPercentage m0 : 55|7@1+ (1,0) [0|0] "" Vector__XXX
 SG_ VCRIGHT_lumbarOvercurrentErr m4 : 55|1@1+ (1,0) [0|0] "" Vector__XXX
 SG_ VCRIGHT_lumbarMaxPErr m4 : 54|1@1+ (1,0) [0|0] "" Vector__XXX
 SG_ VCRIGHT_frontSeatBackBridgeSt m1 : 53|2@1+ (1,0) [0|0] "" Vector__XXX
 SG_ VCRIGHT_frontSeatLiftBridgeSt m2 : 53|2@1+ (1,0) [0|0] "" Vector__XXX
 SG_ VCRIGHT_frontSeatTiltBridgeSt m3 : 53|2@1+ (1,0) [0|0] "" Vector__XXX
 SG_ VCRIGHT_frontSeatTrackBridgeSt m0 : 53|2@1+ (1,0) [0|0] "" Vector__XXX
 SG_ VCRIGHT_lumbarActiveTooLongErr m4 : 53|1@1+ (1,0) [0|0] "" Vector__XXX
 SG_ VCRIGHT_frontSeatBackLog m1 : 52|1@1+ (1,0) [0|0] "" Vector__XXX
 SG_ VCRIGHT_frontSeatLiftLog m2 : 52|1@1+ (1,0) [0|0] "" Vector__XXX
 SG_ VCRIGHT_frontSeatTiltLog m3 : 52|1@1+ (1,0) [0|0] "" Vector__XXX
 SG_ VCRIGHT_frontSeatTrackLog m0 : 52|1@1+ (1,0) [0|0] "" Vector__XXX
 SG_ VCRIGHT_frontSeatBackCalibrated m1 : 51|1@1+ (1,0) [0|0] "" Vector__XXX
 SG_ VCRIGHT_frontSeatLiftCalibrated m2 : 51|1@1+ (1,0) [0|0] "" Vector__XXX
 SG_ VCRIGHT_frontSeatTiltCalibrated m3 : 51|1@1+ (1,0) [0|0] "" Vector__XXX
 SG_ VCRIGHT_frontSeatTrackCalibrated m0 : 51|1@1+ (1,0) [0|0] "" Vector__XXX
 SG_ VCRIGHT_frontSeatBackState m1 : 48|3@1+ (1,0) [0|0] "" Vector__XXX
 SG_ VCRIGHT_frontSeatLiftState m2 : 48|3@1+ (1,0) [0|0] "" Vector__XXX
 SG_ VCRIGHT_frontSeatTiltState m3 : 48|3@1+ (1,0) [0|0] "" Vector__XXX
 SG_ VCRIGHT_frontSeatTrackState m0 : 48|3@1+ (1,0) [0|0] "" Vector__XXX
 SG_ VCRIGHT_lumbarBPressureHpaFilt m4 : 43|10@1+ (1,0) [0|0] "" Vector__XXX
 SG_ VCRIGHT_frontSeatTiltPosOffset m6 : 40|12@1- (0.1,0) [0|0] "" Vector__XXX
 SG_ VCRIGHT_frontSeatTiltPosReal m5 : 40|12@1- (0.1,0) [0|0] "" Vector__XXX
 SG_ VCRIGHT_frontSeatBackDuty m1 : 36|12@1- (0.1,0) [0|0] "" Vector__XXX
 SG_ VCRIGHT_frontSeatLiftDuty m2 : 36|12@1- (0.1,0) [0|0] "" Vector__XXX
 SG_ VCRIGHT_frontSeatTiltDuty m3 : 36|12@1- (0.1,0) [0|0] "" Vector__XXX
 SG_ VCRIGHT_frontSeatTrackDuty m0 : 36|12@1- (0.1,0) [0|0] "" Vector__XXX
 SG_ VCRIGHT_lumbarBPressureHpa m4 : 31|12@1+ (1,0) [0|0] "" Vector__XXX
 SG_ VCRIGHT_frontSeatLiftPosOffset m6 : 28|12@1- (1,0) [0|0] "" Vector__XXX
 SG_ VCRIGHT_frontSeatLiftPosReal m5 : 28|12@1- (1,0) [0|0] "" Vector__XXX
 SG_ VCRIGHT_frontSeatBackCurrent m1 : 24|12@1- (0.01,0) [0|0] "" Vector__XXX
 SG_ VCRIGHT_frontSeatLiftCurrent m2 : 24|12@1- (0.01,0) [0|0] "" Vector__XXX
 SG_ VCRIGHT_frontSeatTiltCurrent m3 : 24|12@1- (0.01,0) [0|0] "" Vector__XXX
 SG_ VCRIGHT_frontSeatTrackCurrent m0 : 24|12@1- (0.01,0) [0|0] "" Vector__XXX
 SG_ VCRIGHT_lumbarAPressureHpaFilt m4 : 21|10@1+ (1,0) [0|0] "" Vector__XXX
 SG_ VCRIGHT_frontSeatBackPosOffset m6 : 16|12@1- (0.1,0) [0|0] "" Vector__XXX
 SG_ VCRIGHT_frontSeatBackPosReal m5 : 16|12@1- (0.1,0) [0|0] "" Vector__XXX
 SG_ VCRIGHT_lumbarBPressurePercentage m7 : 10|7@1+ (1,0) [0|0] "" Vector__XXX
 SG_ VCRIGHT_lumbarAPressureHpa m4 : 9|12@1+ (1,0) [0|0] "" Vector__XXX
 SG_ VCRIGHT_frontSeatBackPos m1 : 8|16@1- (1,0) [0|0] "" Vector__XXX
 SG_ VCRIGHT_frontSeatLiftPos m2 : 8|16@1- (1,0) [0|0] "" Vector__XXX
 SG_ VCRIGHT_frontSeatTiltPos m3 : 8|16@1- (1,0) [0|0] "" Vector__XXX
 SG_ VCRIGHT_frontSeatTrackPos m0 : 8|16@1- (1,0) [0|0] "" Vector__XXX
 SG_ VCRIGHT_lumbarBState m4 : 6|3@1+ (1,0) [0|0] "" Vector__XXX
 SG_ VC_AH_1RowRightSeatMovementHealth m0 : 5|3@1+ (1,0) [0|0] "" Vector__XXX
 SG_ VCRIGHT_frontSeatTrackPosOffset m6 : 3|12@1- (1,0) [0|0] "" Vector__XXX
 SG_ VCRIGHT_frontSeatTrackPosReal m5 : 3|12@1- (1,0) [0|0] "" Vector__XXX
 SG_ VCRIGHT_lumbarAPressurePercentage m7 : 3|7@1+ (1,0) [0|0] "" Vector__XXX
 SG_ VCRIGHT_lumbarAState m4 : 3|3@1+ (1,0) [0|0] "" Vector__XXX
 SG_ VCRIGHT_seatStatusIndex M : 0|3@1+ (1,0) [0|0] "" Vector__XXX

BO_ 1267 UI_frontSeatRequests: 4 Vector__XXX
 SG_ UI_seatAdjustmentSource : 24|3@1+ (1,0) [0|0] "" Vector__XXX
 SG_ UI_frontRightSeatLumbarOut : 23|1@1+ (1,0) [0|0] "" Vector__XXX
 SG_ UI_frontRightSeatLumbarIn : 22|1@1+ (1,0) [0|0] "" Vector__XXX
 SG_ UI_frontLeftSeatLumbarOut : 21|1@1+ (1,0) [0|0] "" Vector__XXX
 SG_ UI_frontLeftSeatLumbarIn : 20|1@1+ (1,0) [0|0] "" Vector__XXX
 SG_ UI_frontRightSeatLumbarDown : 19|1@1+ (1,0) [0|0] "" Vector__XXX
 SG_ UI_frontRightSeatLumbarUp : 18|1@1+ (1,0) [0|0] "" Vector__XXX
 SG_ UI_frontLeftSeatLumbarDown : 17|1@1+ (1,0) [0|0] "" Vector__XXX
 SG_ UI_frontLeftSeatLumbarUp : 16|1@1+ (1,0) [0|0] "" Vector__XXX
 SG_ UI_frontLeftSeatLiftDown : 15|1@1+ (1,0) [0|0] "" Vector__XXX
 SG_ UI_frontLeftSeatLiftUp : 14|1@1+ (1,0) [0|0] "" Vector__XXX
 SG_ UI_frontRightSeatLiftDown : 13|1@1+ (1,0) [0|0] "" Vector__XXX
 SG_ UI_frontRightSeatLiftUp : 12|1@1+ (1,0) [0|0] "" Vector__XXX
 SG_ UI_frontLeftSeatTiltDown : 11|1@1+ (1,0) [0|0] "" Vector__XXX
 SG_ UI_frontLeftSeatTiltUp : 10|1@1+ (1,0) [0|0] "" Vector__XXX
 SG_ UI_frontRightSeatTiltDown : 9|1@1+ (1,0) [0|0] "" Vector__XXX
 SG_ UI_frontRightSeatTiltUp : 8|1@1+ (1,0) [0|0] "" Vector__XXX
 SG_ UI_frontLeftSeatBackrestForward : 7|1@1+ (1,0) [0|0] "" Vector__XXX
 SG_ UI_frontLeftSeatBackrestBack : 6|1@1+ (1,0) [0|0] "" Vector__XXX
 SG_ UI_frontRightSeatBackrestForward : 5|1@1+ (1,0) [0|0] "" Vector__XXX
 SG_ UI_frontRightSeatBackrestBack : 4|1@1+ (1,0) [0|0] "" Vector__XXX
 SG_ UI_frontLeftSeatTrackBack : 3|1@1+ (1,0) [0|0] "" Vector__XXX
 SG_ UI_frontLeftSeatTrackForward : 2|1@1+ (1,0) [0|0] "" Vector__XXX
 SG_ UI_frontRightSeatTrackBack : 1|1@1+ (1,0) [0|0] "" Vector__XXX
 SG_ UI_frontRightSeatTrackForward : 0|1@1+ (1,0) [0|0] "" Vector__XXX

BO_ 1279 APP_defogInfoMessage: 8 Vector__XXX
 SG_ APP_hvacRequest : 61|2@1+ (1,0) [0|0] "" Vector__XXX
 SG_ APP_fasciaFluidCleanCnt : 56|5@1+ (1,0) [0|0] "" Vector__XXX
 SG_ APP_repeatersAirCleanCnt : 51|5@1+ (1,0) [0|0] "" Vector__XXX
 SG_ APP_rightRepeaterFluidCleanCnt : 46|5@1+ (1,0) [0|0] "" Vector__XXX
 SG_ APP_leftRepeaterFluidCleanCnt : 41|5@1+ (1,0) [0|0] "" Vector__XXX
 SG_ APP_pillarBackupAirCleanCnt : 34|7@1+ (1,0) [0|0] "" Vector__XXX
 SG_ APP_pillarBackupFluidCleanCnt : 27|7@1+ (1,0) [0|0] "" Vector__XXX
 SG_ APP_checkThermalSysHealth : 24|2@1+ (1,0) [0|0] "" Vector__XXX
 SG_ APP_forceDefroster : 21|2@1+ (1,0) [0|0] "" Vector__XXX
 SG_ APP_selfieCamFanRpm : 5|16@1+ (1,0) [0|0] "" Vector__XXX
 SG_ APP_cameraDefogMode : 0|4@1+ (1,0) [0|0] "" Vector__XXX

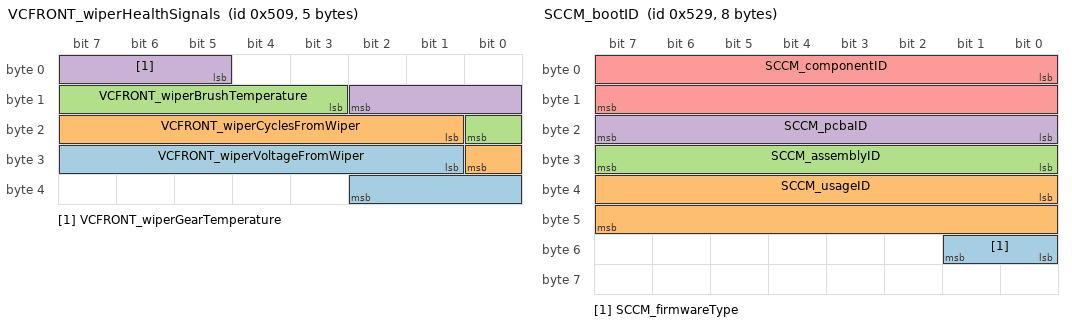
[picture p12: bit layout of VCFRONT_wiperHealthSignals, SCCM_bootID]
BO_ 1289 VCFRONT_wiperHealthSignals: 5 Vector__XXX
 SG_ VCFRONT_wiperVoltageFromWiper : 25|10@1+ (0.01,8) [0|0] "" Vector__XXX
 SG_ VCFRONT_wiperCyclesFromWiper : 17|8@1+ (6000,0) [0|0] "" Vector__XXX
 SG_ VCFRONT_wiperBrushTemperature : 11|6@1+ (1.6,100) [0|0] "" Vector__XXX
 SG_ VCFRONT_wiperGearTemperature : 5|6@1+ (1,40) [0|0] "" Vector__XXX

BO_ 1303 FC_identifier: 8 Vector__XXX
 SG_ FC_sessionId : 32|32@1+ (1,0) [0|0] "" Vector__XXX
 SG_ FC_id : 0|32@1+ (1,0) [0|0] "" Vector__XXX

BO_ 1304 VCRIGHT_alertCleared: 2 Vector__XXX
 SG_ VCRIGHT_alertClearedID : 0|10@1+ (1,0) [0|0] "" Vector__XXX

BO_ 1310 FC_info: 8 Vector__XXX
 SG_ FC_partNumChar07 m25 : 56|8@1+ (1,0) [0|0] "" Vector__XXX
 SG_ FC_partNumChar14 m26 : 56|8@1+ (1,0) [0|0] "" Vector__XXX
 SG_ FC_infoComponentID m10 : 48|16@1+ (1,0) [0|0] "" Vector__XXX
 SG_ FC_infoSubUsageID m11 : 48|16@1+ (1,0) [0|0] "" Vector__XXX
 SG_ FC_partNumChar06 m25 : 48|8@1+ (1,0) [0|0] "" Vector__XXX
 SG_ FC_partNumChar13 m26 : 48|8@1+ (1,0) [0|0] "" Vector__XXX
 SG_ FC_partNumChar20 m27 : 48|8@1+ (1,0) [0|0] "" Vector__XXX
 SG_ FC_infoHardwareRevision m19 : 40|8@1+ (1,0) [0|0] "" Vector__XXX
 SG_ FC_partNumChar05 m25 : 40|8@1+ (1,0) [0|0] "" Vector__XXX
 SG_ FC_partNumChar12 m26 : 40|8@1+ (1,0) [0|0] "" Vector__XXX
 SG_ FC_partNumChar19 m27 : 40|8@1+ (1,0) [0|0] "" Vector__XXX
 SG_ FC_infoApplicationCRC m13 : 32|32@1+ (1,0) [0|0] "" Vector__XXX
 SG_ FC_infoBootCRC m15 : 32|32@1+ (1,0) [0|0] "" Vector__XXX
 SG_ FC_infoHardwareID m10 : 32|16@1+ (1,0) [0|0] "" Vector__XXX
 SG_ FC_infoMaturity m19 : 32|8@1+ (1,0) [0|0] "" Vector__XXX
 SG_ FC_infoUsageID m11 : 32|16@1+ (1,0) [0|0] "" Vector__XXX
 SG_ FC_infoVariantCRC m22 : 32|32@1+ (1,0) [0|0] "" Vector__XXX
 SG_ FC_partNumChar04 m25 : 32|8@1+ (1,0) [0|0] "" Vector__XXX
 SG_ FC_partNumChar11 m26 : 32|8@1+ (1,0) [0|0] "" Vector__XXX
 SG_ FC_partNumChar18 m27 : 32|8@1+ (1,0) [0|0] "" Vector__XXX
 SG_ FC_infoAssemblyID m11 : 24|8@1+ (1,0) [0|0] "" Vector__XXX
 SG_ FC_infoBranchOrigin m19 : 24|8@1+ (1,0) [0|0] "" Vector__XXX
 SG_ FC_infoCPLDVersionMinor m16 : 24|8@1+ (1,0) [0|0] "" Vector__XXX
 SG_ FC_partNumChar03 m25 : 24|8@1+ (1,0) [0|0] "" Vector__XXX
 SG_ FC_partNumChar10 m26 : 24|8@1+ (1,0) [0|0] "" Vector__XXX
 SG_ FC_partNumChar17 m27 : 24|8@1+ (1,0) [0|0] "" Vector__XXX
 SG_ FC_infoBuildConfigID m10 : 16|16@1+ (1,0) [0|0] "" Vector__XXX
 SG_ FC_infoCPLDVersionMajor m16 : 16|8@1+ (1,0) [0|0] "" Vector__XXX
 SG_ FC_infoMajorVersion m19 : 16|8@1+ (1,0) [0|0] "" Vector__XXX
 SG_ FC_infoPcbaID m11 : 16|8@1+ (1,0) [0|0] "" Vector__XXX
 SG_ FC_partNumChar02 m25 : 16|8@1+ (1,0) [0|0] "" Vector__XXX
 SG_ FC_partNumChar09 m26 : 16|8@1+ (1,0) [0|0] "" Vector__XXX
 SG_ FC_partNumChar16 m27 : 16|8@1+ (1,0) [0|0] "" Vector__XXX
 SG_ FC_infoAppGitHashBytes m17 : 8|56@1+ (1,0) [0|0] "" Vector__XXX
 SG_ FC_infoBootGitHashBytes m18 : 8|56@1+ (1,0) [0|0] "" Vector__XXX
 SG_ FC_infoBootSvnRev m14 : 8|24@1+ (1,0) [0|0] "" Vector__XXX
 SG_ FC_infoBootUdsProtoVersion m20 : 8|8@1+ (1,0) [0|0] "" Vector__XXX
 SG_ FC_infoBuildType m10 : 8|8@1+ (1,0) [0|0] "" Vector__XXX
 SG_ FC_infoPlatformType m19 : 8|8@1+ (1,0) [0|0] "" Vector__XXX
 SG_ FC_partNumChar01 m25 : 8|8@1+ (1,0) [0|0] "" Vector__XXX
 SG_ FC_partNumChar08 m26 : 8|8@1+ (1,0) [0|0] "" Vector__XXX
 SG_ FC_partNumChar15 m27 : 8|8@1+ (1,0) [0|0] "" Vector__XXX
 SG_ FC_infoIndex M : 0|8@1+ (1,0) [0|0] "" Vector__XXX

BO_ 1314 VCLEFT_alertCleared: 2 Vector__XXX
 SG_ VCLEFT_alertClearedID : 0|10@1+ (1,0) [0|0] "" Vector__XXX

BO_ 1320 GTW_time: 4 Vector__XXX
 SG_ GTW_timeSecs : 7|32@0+ (1,0) [0|0] "" Vector__XXX

BO_ 1321 SCCM_bootID: 8 Vector__XXX
 SG_ SCCM_firmwareType : 48|2@1+ (1,0) [0|0] "" Vector__XXX
 SG_ SCCM_usageID : 32|16@1+ (1,0) [0|0] "" Vector__XXX
 SG_ SCCM_assemblyID : 24|8@1+ (1,0) [0|0] "" Vector__XXX
 SG_ SCCM_pcbaID : 16|8@1+ (1,0) [0|0] "" Vector__XXX
 SG_ SCCM_componentID : 0|16@1+ (1,0) [0|0] "" Vector__XXX

BO_ 1327 GTW_epochTimeGtw: 8 Vector__XXX
 SG_ GTW_epoch_ns : 7|64@0+ (1,0) [0|0] "" Vector__XXX

BO_ 1342 CP_info: 8 Vector__XXX
 SG_ CP_componentId m10 : 48|16@1+ (1,0) [0|0] "" Vector__XXX
 SG_ CP_subUsageId m11 : 48|16@1+ (1,0) [0|0] "" Vector__XXX
 SG_ CP_appCrc m13 : 32|32@1+ (1,0) [0|0] "" Vector__XXX
 SG_ CP_bootCrc m20 : 32|32@1+ (1,0) [0|0] "" Vector__XXX
 SG_ CP_hardwareId m10 : 32|16@1+ (1,0) [0|0] "" Vector__XXX
 SG_ CP_usageId m11 : 32|16@1+ (1,0) [0|0] "" Vector__XXX
 SG_ CP_assemblyId m11 : 24|8@1+ (1,0) [0|0] "" Vector__XXX
 SG_ CP_buildConfigId m10 : 16|16@1+ (1,0) [0|0] "" Vector__XXX
 SG_ CP_pcbaId m11 : 16|8@1+ (1,0) [0|0] "" Vector__XXX
 SG_ CP_appGitHash m17 : 8|56@1+ (1,0) [0|0] "" Vector__XXX
 SG_ CP_bootGitHash m18 : 8|56@1+ (1,0) [0|0] "" Vector__XXX
 SG_ CP_bootUdsProtoVersion m20 : 8|8@1+ (1,0) [0|0] "" Vector__XXX
 SG_ CP_buildType m10 : 8|3@1+ (1,0) [0|0] "" Vector__XXX
 SG_ CP_platformType m13 : 8|8@1+ (1,0) [0|0] "" Vector__XXX
 SG_ CP_infoIndex M : 0|8@1+ (1,0) [0|0] "" Vector__XXX

BO_ 1345 FC_maxLimits: 8 Vector__XXX
 SG_ FC_maxCurrentLimit : 16|13@1+ (0.0732421875,0) [0|0] "" Vector__XXX
 SG_ FC_maxPowerLimit : 0|13@1+ (0.062255859376,0) [0|0] "" Vector__XXX

BO_ 1349 VCFRONT_systemStatus: 8 Vector__XXX
 SG_ VCFRONT_systemStatusChecksum : 56|8@1+ (1,0) [0|0] "" Vector__XXX
 SG_ VCFRONT_systemStatusCounter : 52|4@1+ (1,0) [0|0] "" Vector__XXX
 SG_ VCFRONT_loadShedAutoPilot m2 : 51|1@1+ (1,0) [0|0] "" Vector__XXX
 SG_ VCFRONT_loadShedUI m2 : 50|1@1+ (1,0) [0|0] "" Vector__XXX
 SG_ VCFRONT_LVUnhealthyVehicleLoadShedActive m1 : 46|1@1+ (1,0) [0|0] "" Vector__XXX
 SG_ VCFRONT_HVFaultLoadShedStateDBG m1 : 44|2@1+ (1,0) [0|0] "" Vector__XXX
 SG_ VCFRONT_loadShedPCSLeakyBktCtDBG m2 : 44|6@1+ (100,0) [0|0] "" Vector__XXX
 SG_ VCFRONT_DIVehLoadShedActive m1 : 43|1@1+ (1,0) [0|0] "" Vector__XXX
 SG_ VCFRONT_anyVehicleLoadShedActive m1 : 42|1@1+ (1,0) [0|0] "" Vector__XXX
 SG_ VCFRONT_factoryVehicleLoadShedActive m1 : 41|1@1+ (1,0) [0|0] "" Vector__XXX
 SG_ VCFRONT_HVFaultVehicleLoadShedActive m1 : 40|1@1+ (1,0) [0|0] "" Vector__XXX
 SG_ VCFRONT_vcrightVoltage m0 : 40|12@1+ (0.005443676098,0) [0|0] "" Vector__XXX
 SG_ VCFRONT_postCrashVehicleLoadShedActive m1 : 39|1@1+ (1,0) [0|0] "" Vector__XXX
 SG_ VCFRONT_HVFaultVehicleLoadShedRequest m1 : 38|1@1+ (1,0) [0|0] "" Vector__XXX
 SG_ VCFRONT_loadShedBackStopBktCntDBG m2 : 38|5@1+ (0.05,0) [0|0] "" Vector__XXX
 SG_ VCFRONT_loadShedTAS m2 : 37|1@1+ (1,0) [0|0] "" Vector__XXX
 SG_ VCFRONT_loadShedPCSMIATriggerDBG m2 : 36|1@1+ (1,0) [0|0] "" Vector__XXX
 SG_ VCFRONT_vehicleLoadShedStage m1 : 36|2@1+ (1,0) [0|0] "" Vector__XXX
 SG_ VCFRONT_loadShedGTWDownstrmRails m2 : 35|1@1+ (1,0) [0|0] "" Vector__XXX
 SG_ VCFRONT_loadShedPcs m2 : 33|1@1+ (1,0) [0|0] "" Vector__XXX
 SG_ VCFRONT_DCDCSaturationLoadShedStage m1 : 28|5@1+ (1,0) [0|0] "" Vector__XXX
 SG_ VCFRONT_vcleftVoltage m0 : 28|12@1+ (0.005443676098,0) [0|0] "" Vector__XXX
 SG_ VCFRONT_loadShedAhLeakyBktCntDBG m2 : 23|9@1+ (0.001,0) [0|0] "" Vector__XXX
 SG_ VCFRONT_VCLeftEFuseLoadShedStage m1 : 20|5@1+ (1,0) [0|0] "" Vector__XXX
 SG_ VCFRONT_IBSCurrentRMS_loadShed m2 : 16|7@1+ (0.05,0) [0|0] "" Vector__XXX
 SG_ VCFRONT_vcrightCurrent m0 : 16|12@1+ (0.05,0) [0|0] "" Vector__XXX
 SG_ VCFRONT_loadShedStsMCUGraphics m2 : 15|1@1+ (1,0) [0|0] "" Vector__XXX
 SG_ VCFRONT_loadShedStsAPGlassHeater m2 : 14|1@1+ (1,0) [0|0] "" Vector__XXX
 SG_ VCFRONT_loadShedStsBatteryPump m2 : 13|1@1+ (1,0) [0|0] "" Vector__XXX
 SG_ VCFRONT_VCRightEFuseLoadShedStage m1 : 12|5@1+ (1,0) [0|0] "" Vector__XXX
 SG_ VCFRONT_loadShedPCSSatTriggerDBG m2 : 12|1@1+ (1,0) [0|0] "" Vector__XXX
 SG_ VCFRONT_loadShedHVDownTriggerDBG m2 : 11|1@1+ (1,0) [0|0] "" Vector__XXX
 SG_ VCFRONT_loadShedMCUAudio m2 : 10|1@1+ (1,0) [0|0] "" Vector__XXX
 SG_ VCFRONT_loadShedStsPTPump m2 : 6|1@1+ (1,0) [0|0] "" Vector__XXX
 SG_ VCFRONT_vcleftCurrent m0 : 4|12@1+ (0.05,0) [0|0] "" Vector__XXX
 SG_ VCFRONT_loadShedReason m1 : 3|9@1+ (1,0) [0|0] "" Vector__XXX
 SG_ VCFRONT_loadShedStsCondenserFan m2 : 3|1@1+ (1,0) [0|0] "" Vector__XXX
 SG_ VCFRONT_systemStatusMuxIndex M : 0|2@1+ (1,0) [0|0] "" Vector__XXX

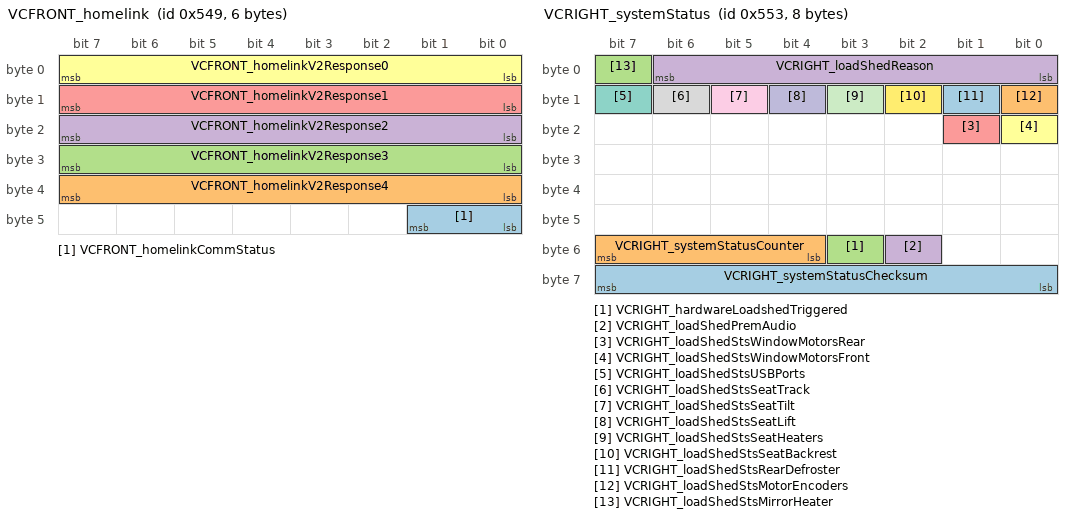
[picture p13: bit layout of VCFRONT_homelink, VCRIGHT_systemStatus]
BO_ 1353 VCFRONT_homelink: 6 Vector__XXX
 SG_ VCFRONT_homelinkCommStatus : 40|2@1+ (1,0) [0|0] "" Vector__XXX
 SG_ VCFRONT_homelinkV2Response4 : 32|8@1+ (1,0) [0|0] "" Vector__XXX
 SG_ VCFRONT_homelinkV2Response3 : 24|8@1+ (1,0) [0|0] "" Vector__XXX
 SG_ VCFRONT_homelinkV2Response2 : 16|8@1+ (1,0) [0|0] "" Vector__XXX
 SG_ VCFRONT_homelinkV2Response1 : 8|8@1+ (1,0) [0|0] "" Vector__XXX
 SG_ VCFRONT_homelinkV2Response0 : 0|8@1+ (1,0) [0|0] "" Vector__XXX

BO_ 1359 SCCM_alertMatrix: 8 Vector__XXX
 SG_ SCCM_a029_parkButtonMalfunction m0 : 32|1@1+ (1,0) [0|0] "" Vector__XXX
 SG_ SCCM_a028_parkButtonShortToGround m0 : 31|1@1+ (1,0) [0|0] "" Vector__XXX
 SG_ SCCM_a027_parkButtonOpenCircuit m0 : 30|1@1+ (1,0) [0|0] "" Vector__XXX
 SG_ SCCM_a026_parkButtonInvalidSignal m0 : 29|1@1+ (1,0) [0|0] "" Vector__XXX
 SG_ SCCM_a025_runTimeError m0 : 28|1@1+ (1,0) [0|0] "" Vector__XXX
 SG_ SCCM_a024_gearStalkGenErr m0 : 27|1@1+ (1,0) [0|0] "" Vector__XXX
 SG_ SCCM_a023_gearStalkShortCircuit m0 : 26|1@1+ (1,0) [0|0] "" Vector__XXX
 SG_ SCCM_a022_gearStalkOpenCircuit m0 : 25|1@1+ (1,0) [0|0] "" Vector__XXX
 SG_ SCCM_a021_gearStalkSignalInvalid m0 : 24|1@1+ (1,0) [0|0] "" Vector__XXX
 SG_ SCCM_a020_angleInternalError m0 : 23|1@1+ (1,0) [0|0] "" Vector__XXX
 SG_ SCCM_a019_angleOutOfRange m0 : 22|1@1+ (1,0) [0|0] "" Vector__XXX
 SG_ SCCM_a018_angleSpeedOutOfRange m0 : 21|1@1+ (1,0) [0|0] "" Vector__XXX
 SG_ SCCM_a017_memoryError m0 : 20|1@1+ (1,0) [0|0] "" Vector__XXX
 SG_ SCCM_a016_hardwareError m0 : 19|1@1+ (1,0) [0|0] "" Vector__XXX
 SG_ SCCM_a015_softwareError m0 : 18|1@1+ (1,0) [0|0] "" Vector__XXX
 SG_ SCCM_a014_voltageLow m0 : 17|1@1+ (1,0) [0|0] "" Vector__XXX
 SG_ SCCM_a013_voltageHigh m0 : 16|1@1+ (1,0) [0|0] "" Vector__XXX
 SG_ SCCM_a012_turnGenErr m0 : 15|1@1+ (1,0) [0|0] "" Vector__XXX
 SG_ SCCM_a011_turnIndHWErr m0 : 14|1@1+ (1,0) [0|0] "" Vector__XXX
 SG_ SCCM_a010_turnIndShortToGnd m0 : 13|1@1+ (1,0) [0|0] "" Vector__XXX
 SG_ SCCM_a009_turnIndOpen m0 : 12|1@1+ (1,0) [0|0] "" Vector__XXX
 SG_ SCCM_a008_turnIndInvalidTrans m0 : 11|1@1+ (1,0) [0|0] "" Vector__XXX
 SG_ SCCM_a007_turnIndComInfo m0 : 10|1@1+ (1,0) [0|0] "" Vector__XXX
 SG_ SCCM_a006_tipWipeShortToGND m0 : 9|1@1+ (1,0) [0|0] "" Vector__XXX
 SG_ SCCM_a005_tipWipeOpen m0 : 8|1@1+ (1,0) [0|0] "" Vector__XXX
 SG_ SCCM_a004_highBeamShortToGND m0 : 7|1@1+ (1,0) [0|0] "" Vector__XXX
 SG_ SCCM_a003_highBeamOpen m0 : 6|1@1+ (1,0) [0|0] "" Vector__XXX
 SG_ SCCM_a002_CANTOut m0 : 5|1@1+ (1,0) [0|0] "" Vector__XXX
 SG_ SCCM_a001_CANBusOff m0 : 4|1@1+ (1,0) [0|0] "" Vector__XXX
 SG_ SCCM_matrixIndex M : 0|4@1+ (1,0) [0|0] "" Vector__XXX

BO_ 1362 VCLEFT_systemStatus: 8 Vector__XXX
 SG_ VCLEFT_systemStatusChecksum : 56|8@1+ (1,0) [0|0] "" Vector__XXX
 SG_ VCLEFT_systemStatusCounter : 52|4@1+ (1,0) [0|0] "" Vector__XXX
 SG_ VCLEFT_alcoholInterlockState : 22|2@1+ (1,0) [0|0] "" Vector__XXX
 SG_ VCLEFT_loadShedStsWindowMotorsRear : 21|1@1+ (1,0) [0|0] "" Vector__XXX
 SG_ VCLEFT_loadShedStsWindowMotorsFront : 20|1@1+ (1,0) [0|0] "" Vector__XXX
 SG_ VCLEFT_loadShedStsUSBPorts : 19|1@1+ (1,0) [0|0] "" Vector__XXX
 SG_ VCLEFT_loadShedStsSTWUpDown : 18|1@1+ (1,0) [0|0] "" Vector__XXX
 SG_ VCLEFT_loadShedStsSTWInOut : 17|1@1+ (1,0) [0|0] "" Vector__XXX
 SG_ VCLEFT_loadShedStsSeatTrack : 16|1@1+ (1,0) [0|0] "" Vector__XXX
 SG_ VCLEFT_loadShedStsSeatTilt : 15|1@1+ (1,0) [0|0] "" Vector__XXX
 SG_ VCLEFT_loadShedStsSeatLift : 14|1@1+ (1,0) [0|0] "" Vector__XXX
 SG_ VCLEFT_loadShedStsSeatHeaters : 13|1@1+ (1,0) [0|0] "" Vector__XXX
 SG_ VCLEFT_loadShedStsSeatBackrest : 12|1@1+ (1,0) [0|0] "" Vector__XXX
 SG_ VCLEFT_loadShedStsMotorEncoders : 11|1@1+ (1,0) [0|0] "" Vector__XXX
 SG_ VCLEFT_loadShedStsMirrorHeater : 10|1@1+ (1,0) [0|0] "" Vector__XXX
 SG_ VCLEFT_loadShedStsLiftgate : 9|1@1+ (1,0) [0|0] "" Vector__XXX
 SG_ VCLEFT_loadShedStsHVACBlower : 8|1@1+ (1,0) [0|0] "" Vector__XXX
 SG_ VCLEFT_loadShedSts12VAUXLoads : 7|1@1+ (1,0) [0|0] "" Vector__XXX
 SG_ VCLEFT_loadShedReason : 0|7@1+ (1,0) [0|0] "" Vector__XXX

BO_ 1363 VCRIGHT_systemStatus: 8 Vector__XXX
 SG_ VCRIGHT_systemStatusChecksum : 56|8@1+ (1,0) [0|0] "" Vector__XXX
 SG_ VCRIGHT_systemStatusCounter : 52|4@1+ (1,0) [0|0] "" Vector__XXX
 SG_ VCRIGHT_hardwareLoadshedTriggered : 51|1@1+ (1,0) [0|0] "" Vector__XXX
 SG_ VCRIGHT_loadShedPremAudio : 50|1@1+ (1,0) [0|0] "" Vector__XXX
 SG_ VCRIGHT_loadShedStsWindowMotorsRear : 17|1@1+ (1,0) [0|0] "" Vector__XXX
 SG_ VCRIGHT_loadShedStsWindowMotorsFront : 16|1@1+ (1,0) [0|0] "" Vector__XXX
 SG_ VCRIGHT_loadShedStsUSBPorts : 15|1@1+ (1,0) [0|0] "" Vector__XXX
 SG_ VCRIGHT_loadShedStsSeatTrack : 14|1@1+ (1,0) [0|0] "" Vector__XXX
 SG_ VCRIGHT_loadShedStsSeatTilt : 13|1@1+ (1,0) [0|0] "" Vector__XXX
 SG_ VCRIGHT_loadShedStsSeatLift : 12|1@1+ (1,0) [0|0] "" Vector__XXX
 SG_ VCRIGHT_loadShedStsSeatHeaters : 11|1@1+ (1,0) [0|0] "" Vector__XXX
 SG_ VCRIGHT_loadShedStsSeatBackrest : 10|1@1+ (1,0) [0|0] "" Vector__XXX
 SG_ VCRIGHT_loadShedStsRearDefroster : 9|1@1+ (1,0) [0|0] "" Vector__XXX
 SG_ VCRIGHT_loadShedStsMotorEncoders : 8|1@1+ (1,0) [0|0] "" Vector__XXX
 SG_ VCRIGHT_loadShedStsMirrorHeater : 7|1@1+ (1,0) [0|0] "" Vector__XXX
 SG_ VCRIGHT_loadShedReason : 0|7@1+ (1,0) [0|0] "" Vector__XXX

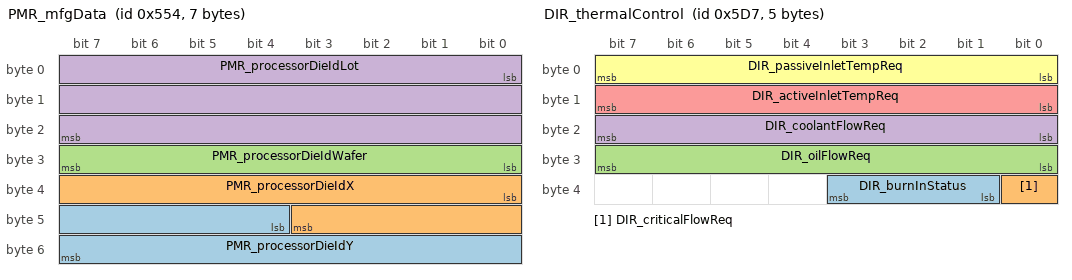
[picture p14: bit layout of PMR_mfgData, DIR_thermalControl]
BO_ 1364 PMR_mfgData: 7 Vector__XXX
 SG_ PMR_processorDieIdY : 44|12@1+ (1,0) [0|0] "" Vector__XXX
 SG_ PMR_processorDieIdX : 32|12@1+ (1,0) [0|0] "" Vector__XXX
 SG_ PMR_processorDieIdWafer : 24|8@1+ (1,0) [0|0] "" Vector__XXX
 SG_ PMR_processorDieIdLot : 0|24@1+ (1,0) [0|0] "" Vector__XXX

BO_ 1495 DIR_thermalControl: 5 Vector__XXX
 SG_ DIR_burnInStatus : 33|3@1+ (1,0) [0|0] "" Vector__XXX
 SG_ DIR_criticalFlowReq : 32|1@1+ (1,0) [0|0] "" Vector__XXX
 SG_ DIR_oilFlowReq : 24|8@1+ (0.1,0) [0|0] "" Vector__XXX
 SG_ DIR_coolantFlowReq : 16|8@1+ (0.2,0) [0|0] "" Vector__XXX
 SG_ DIR_activeInletTempReq : 8|8@1+ (1,-40) [0|0] "" Vector__XXX
 SG_ DIR_passiveInletTempReq : 0|8@1+ (1,-40) [0|0] "" Vector__XXX

BO_ 1523 UI_odo: 3 Vector__XXX
 SG_ UI_odometer : 0|24@1+ (0.1,0) [0|0] "" Vector__XXX

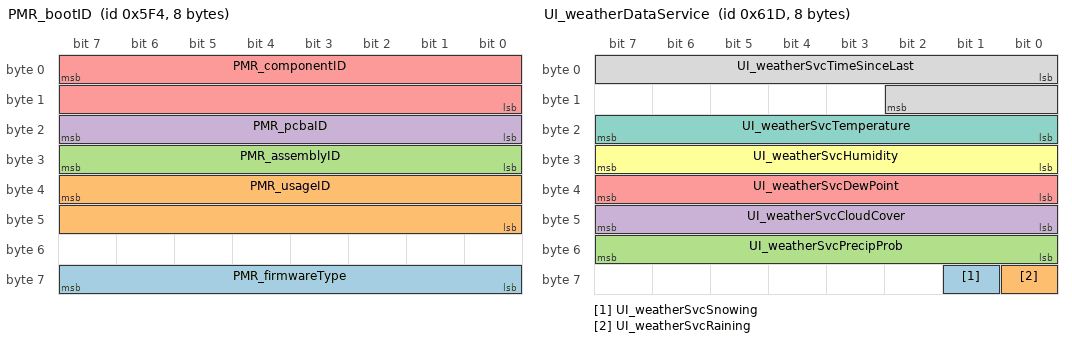
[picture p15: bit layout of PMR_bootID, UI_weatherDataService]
BO_ 1524 PMR_bootID: 8 Vector__XXX
 SG_ PMR_firmwareType : 63|8@0+ (1,0) [0|0] "" Vector__XXX
 SG_ PMR_usageID : 39|16@0+ (1,0) [0|0] "" Vector__XXX
 SG_ PMR_assemblyID : 31|8@0+ (1,0) [0|0] "" Vector__XXX
 SG_ PMR_pcbaID : 23|8@0+ (1,0) [0|0] "" Vector__XXX
 SG_ PMR_componentID : 7|16@0+ (1,0) [0|0] "" Vector__XXX

BO_ 1536 UDS_vcfrontRequest: 8 Vector__XXX
 SG_ UDS_vcfrontRequestData : 7|64@0+ (1,0) [0|0] "" Vector__XXX

BO_ 1537 VCFRONT_udsResponse: 8 Vector__XXX
 SG_ VCFRONT_udsResponseData : 7|64@0+ (1,0) [0|0] "" Vector__XXX

BO_ 1541 UDS_difRequest: 8 Vector__XXX
 SG_ UDS_difRequestData : 7|64@0+ (1,0) [0|0] "" Vector__XXX

BO_ 1542 UDS_dirRequest: 8 Vector__XXX
 SG_ UDS_dirRequestData : 7|64@0+ (1,0) [0|0] "" Vector__XXX

BO_ 1544 UDS_vcrightRequest: 8 Vector__XXX
 SG_ UDS_vcrightRequestData_L : 39|32@0+ (1,0) [0|0] "" Vector__XXX
 SG_ UDS_vcrightRequestData_H : 7|32@0+ (1,0) [0|0] "" Vector__XXX

BO_ 1545 VCRIGHT_udsResponse: 8 Vector__XXX
 SG_ VCRIGHT_udsResponseData_L : 39|32@0+ (1,0) [0|0] "" Vector__XXX
 SG_ VCRIGHT_udsResponseData_H : 7|32@0+ (1,0) [0|0] "" Vector__XXX

BO_ 1546 UDS_vcsecRequest: 8 Vector__XXX
 SG_ UDS_vcsecRequestData : 7|64@0+ (1,0) [0|0] "" Vector__XXX

BO_ 1547 VCSEC_udsResponse: 8 Vector__XXX
 SG_ VCSEC_udsResponseData : 7|64@0+ (1,0) [0|0] "" Vector__XXX

BO_ 1550 UDS_cpRequest: 8 Vector__XXX
 SG_ UDS_cpRequestData : 7|64@0+ (1,0) [0|0] "" Vector__XXX

BO_ 1558 DIR_udsResponse: 8 Vector__XXX
 SG_ DIR_udsResponseData : 7|64@0+ (1,0) [0|0] "" Vector__XXX

BO_ 1565 UI_weatherDataService: 8 Vector__XXX
 SG_ UI_weatherSvcSnowing : 57|1@1+ (1,0) [0|0] "" Vector__XXX
 SG_ UI_weatherSvcRaining : 56|1@1+ (1,0) [0|0] "" Vector__XXX
 SG_ UI_weatherSvcPrecipProb : 48|8@1+ (0.5,0) [0|0] "" Vector__XXX
 SG_ UI_weatherSvcCloudCover : 40|8@1+ (0.5,0) [0|0] "" Vector__XXX
 SG_ UI_weatherSvcDewPoint : 32|8@1+ (0.5,0) [0|0] "" Vector__XXX
 SG_ UI_weatherSvcHumidity : 24|8@1+ (0.5,0) [0|0] "" Vector__XXX
 SG_ UI_weatherSvcTemperature : 16|8@1- (0.5,0) [0|0] "" Vector__XXX
 SG_ UI_weatherSvcTimeSinceLast : 0|11@1+ (1,0) [0|0] "" Vector__XXX

BO_ 1566 CP_udsResponse: 8 Vector__XXX
 SG_ CP_udsResponseData : 7|64@0+ (1,0) [0|0] "" Vector__XXX

BO_ 1570 UDS_vcleftRequest: 8 Vector__XXX
 SG_ UDS_vcleftRequestData_L : 39|32@0+ (1,0) [0|0] "" Vector__XXX
 SG_ UDS_vcleftRequestData_H : 7|32@0+ (1,0) [0|0] "" Vector__XXX

BO_ 1571 VCLEFT_udsResponse: 8 Vector__XXX
 SG_ VCLEFT_udsResponseData_L : 39|32@0+ (1,0) [0|0] "" Vector__XXX
 SG_ VCLEFT_udsResponseData_H : 7|32@0+ (1,0) [0|0] "" Vector__XXX

BO_ 1572 UDS_epblRequest: 8 Vector__XXX
 SG_ UDS_epblRequestData_L : 39|32@0+ (1,0) [0|0] "" Vector__XXX
 SG_ UDS_epblRequestData_H : 7|32@0+ (1,0) [0|0] "" Vector__XXX

BO_ 1573 EPBL_udsResponse: 8 Vector__XXX
 SG_ EPBL_udsResponseData_L : 39|32@0+ (1,0) [0|0] "" Vector__XXX
 SG_ EPBL_udsResponseData_H : 7|32@0+ (1,0) [0|0] "" Vector__XXX

BO_ 1574 UDS_epbrRequest: 8 Vector__XXX
 SG_ UDS_epbrRequestData_L : 39|32@0+ (1,0) [0|0] "" Vector__XXX
 SG_ UDS_epbrRequestData_H : 7|32@0+ (1,0) [0|0] "" Vector__XXX

BO_ 1575 EPBR_udsResponse: 8 Vector__XXX
 SG_ EPBR_udsResponseData_L : 39|32@0+ (1,0) [0|0] "" Vector__XXX
 SG_ EPBR_udsResponseData_H : 7|32@0+ (1,0) [0|0] "" Vector__XXX

BO_ 1576 UDS_pcsRequest: 8 Vector__XXX
 SG_ UDS_pcsRequestData : 7|64@0+ (1,0) [0|0] "" Vector__XXX

BO_ 1577 PCS_udsResponse: 8 Vector__XXX
 SG_ PCS_udsResponseData : 7|64@0+ (1,0) [0|0] "" Vector__XXX

BO_ 1588 CMPD_bootID: 8 Vector__XXX
 SG_ CMPD_bootFirmwareType : 63|8@0+ (1,0) [0|0] "" Vector__XXX
 SG_ CMPD_bootUsageId : 39|16@0+ (1,0) [0|0] "" Vector__XXX
 SG_ CMPD_bootAssemblyId : 31|8@0+ (1,0) [0|0] "" Vector__XXX
 SG_ CMPD_bootPcbaId : 23|8@0+ (1,0) [0|0] "" Vector__XXX
 SG_ CMPD_bootComponentId : 7|16@0+ (1,0) [0|0] "" Vector__XXX

BO_ 1617 RCM_udsResponse: 8 Vector__XXX
 SG_ RCM_udsResponseData : 7|64@0+ (1,0) [0|0] "" Vector__XXX

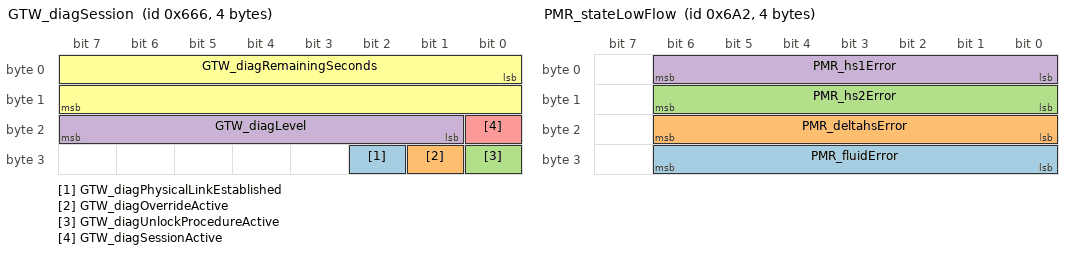
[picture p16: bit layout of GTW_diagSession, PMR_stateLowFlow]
BO_ 1638 GTW_diagSession: 4 Vector__XXX
 SG_ GTW_diagPhysicalLinkEstablished : 26|1@1+ (1,0) [0|0] "" Vector__XXX
 SG_ GTW_diagOverrideActive : 25|1@1+ (1,0) [0|0] "" Vector__XXX
 SG_ GTW_diagUnlockProcedureActive : 24|1@1+ (1,0) [0|0] "" Vector__XXX
 SG_ GTW_diagLevel : 17|7@1+ (1,0) [0|0] "" Vector__XXX
 SG_ GTW_diagSessionActive : 16|1@1+ (1,0) [0|0] "" Vector__XXX
 SG_ GTW_diagRemainingSeconds : 0|16@1+ (1,0) [0|0] "" Vector__XXX

BO_ 1651 VEH_isoTpToEvse: 8 Vector__XXX
 SG_ VEH_isoTpToEvseData : 0|64@1+ (1,0) [0|0] "" Vector__XXX

BO_ 1655 VC_LVBMS_statusHigh: 8 Vector__XXX
 SG_ VC_LVBMS_minBrickVoltageIndex m4 : 56|8@1+ (1,0) [0|0] "" Vector__XXX
 SG_ VC_LVBMS_MOSTemperature m0 : 50|12@1+ (0.5,-50) [0|0] "" Vector__XXX
 SG_ VC_LVBMS_maxAllowedDischargeCurrent m3 : 50|13@1+ (0.1,0) [0|0] "" Vector__XXX
 SG_ VC_LVBMS_estimatedPackOcv m2 : 48|16@1+ (0.001,0) [0|0] "" Vector__XXX
 SG_ VC_LVBMS_packTemperature m0 : 41|9@1+ (0.5,-50) [0|0] "" Vector__XXX
 SG_ VC_LVBMS_maxBrickVoltageIndex m1 : 40|8@1+ (1,0) [0|0] "" Vector__XXX
 SG_ VC_LVBMS_minBrickVoltage m4 : 40|13@1+ (0.001,0) [0|0] "" Vector__XXX
 SG_ VC_LVBMS_maxAllowedChargeCurrent m3 : 37|13@1+ (0.1,0) [0|0] "" Vector__XXX
 SG_ VC_LVPackCurrent m2 : 34|14@1- (0.1,0) [0|0] "" Vector__XXX
 SG_ VC_LVBMS_packVoltage m0 : 25|16@1+ (0.001,0) [0|0] "" Vector__XXX
 SG_ VC_LVBMS_avgBrickVoltage m4 : 24|13@1+ (0.001,0) [0|0] "" Vector__XXX
 SG_ VC_LVBMS_maxBrickVoltage m1 : 24|13@1+ (0.001,0) [0|0] "" Vector__XXX
 SG_ VC_LVPackChargeCurrentLimit m2 : 22|12@1+ (0.1,0) [0|0] "" Vector__XXX
 SG_ VC_LVBMS_cellAndArcProtEnabled m4 : 19|1@1+ (1,0) [0|0] "" Vector__XXX
 SG_ VC_LVBMS_currentTarget m3 : 19|18@1+ (0.001,-122) [0|0] "" Vector__XXX
 SG_ VC_LVBMS_chargeType m4 : 16|3@1+ (1,0) [0|0] "" Vector__XXX
 SG_ VC_LVBMS_LINWakeDisabled m4 : 14|1@1+ (1,0) [0|0] "" Vector__XXX
 SG_ VC_LVBMS_VehicleState m4 : 12|2@1+ (1,0) [0|0] "" Vector__XXX
 SG_ VC_LVBMS_MOSState m4 : 10|2@1+ (1,0) [0|0] "" Vector__XXX
 SG_ VC_LVBMS_ECPAState m4 : 8|2@1+ (1,0) [0|0] "" Vector__XXX
 SG_ VC_LVBMS_sumCellVoltage m1 : 8|16@1+ (0.001,0) [0|0] "" Vector__XXX
 SG_ VC_totalLVLoadCurrent m2 : 8|14@1- (0.1,0) [0|0] "" Vector__XXX
 SG_ VC_LVBMS_EnterHibernationCommand m4 : 7|1@1+ (1,0) [0|0] "" Vector__XXX
 SG_ VC_LVBMS_ResetLVBMSCommand m4 : 6|1@1+ (1,0) [0|0] "" Vector__XXX
 SG_ VC_LVBMS_ClearHistoricFaultCommand m4 : 5|1@1+ (1,0) [0|0] "" Vector__XXX
 SG_ VC_LVBMS_ClearErrorCntrCommand m4 : 4|1@1+ (1,0) [0|0] "" Vector__XXX
 SG_ VC_LVBMS_MOSCommand m4 : 3|1@1+ (1,0) [0|0] "" Vector__XXX
 SG_ VC_LVBMS_packCurrent m0 : 3|22@1+ (0.001,-2000) [0|0] "" Vector__XXX
 SG_ VC_LVBMS_voltageTarget m3 : 3|16@1+ (0.001,0) [0|0] "" Vector__XXX
 SG_ VC_lvbmsStatusHighIndex M : 0|3@1+ (1,0) [0|0] "" Vector__XXX

BO_ 1662 EVSE_isoTpToVeh: 8 Vector__XXX
 SG_ EVSE_isoTpToVehData : 0|64@1+ (1,0) [0|0] "" Vector__XXX

BO_ 1666 HVP_hvpFaults: 8 Vector__XXX
 SG_ HVP_hvpFaultsChecksum : 56|8@1+ (1,0) [0|0] "" Vector__XXX
 SG_ HVP_hvpFaultsCounter : 52|4@1+ (1,0) [0|0] "" Vector__XXX
 SG_ HVP_shuntOverTemperature : 51|1@1+ (1,0) [0|0] "" Vector__XXX
 SG_ HVP_bmbBmbDataIntegrityLossFault : 49|1@1+ (1,0) [0|0] "" Vector__XXX
 SG_ HVP_bmbCommunicationFault : 48|1@1+ (1,0) [0|0] "" Vector__XXX
 SG_ HVP_configMinorVersion : 40|8@1+ (1,0) [0|0] "" Vector__XXX
 SG_ HVP_configMajorVersion : 32|8@1+ (1,0) [0|0] "" Vector__XXX
 SG_ HVP_hvilStatus : 30|2@1+ (1,0) [0|0] "" Vector__XXX
 SG_ HVP_hvilFault : 26|1@1+ (1,0) [0|0] "" Vector__XXX
 SG_ HVP_unsupportedBmbAsicType : 25|1@1+ (1,0) [0|0] "" Vector__XXX
 SG_ HVP_missingPartNumber : 24|1@1+ (1,0) [0|0] "" Vector__XXX
 SG_ HVP_missingConfigBlock : 23|1@1+ (1,0) [0|0] "" Vector__XXX
 SG_ HVP_fastVshFailureFault : 22|1@1+ (1,0) [0|0] "" Vector__XXX
 SG_ HVP_gpoRequestActive : 21|1@1+ (1,0) [0|0] "" Vector__XXX
 SG_ HVP_battery12vDisconnected : 20|1@1+ (1,0) [0|0] "" Vector__XXX
 SG_ HVP_packNegativeCtrArcFault : 19|1@1+ (1,0) [0|0] "" Vector__XXX
 SG_ HVP_packPositiveCtrArcFault : 18|1@1+ (1,0) [0|0] "" Vector__XXX
 SG_ HVP_ensMiaFault : 17|1@1+ (1,0) [0|0] "" Vector__XXX
 SG_ HVP_crashEvent : 16|1@1+ (1,0) [0|0] "" Vector__XXX
 SG_ HVP_packVoltageMismatchFault : 15|1@1+ (1,0) [0|0] "" Vector__XXX
 SG_ HVP_supply12vFault : 14|1@1+ (1,0) [0|0] "" Vector__XXX
 SG_ HVP_fcContactorHwFault : 13|1@1+ (1,0) [0|0] "" Vector__XXX
 SG_ HVP_packContactorHwFault : 12|1@1+ (1,0) [0|0] "" Vector__XXX
 SG_ HVP_pyroMiaWarning : 11|1@1+ (1,0) [0|0] "" Vector__XXX
 SG_ HVP_pyroMiaFault : 10|1@1+ (1,0) [0|0] "" Vector__XXX
 SG_ HVP_shuntHwAndBmsMiaFault : 9|1@1+ (1,0) [0|0] "" Vector__XXX
 SG_ HVP_shuntHwMiaFault : 8|1@1+ (1,0) [0|0] "" Vector__XXX
 SG_ HVP_cpFault : 7|1@1+ (1,0) [0|0] "" Vector__XXX
 SG_ HVP_pcsMiaFault : 6|1@1+ (1,0) [0|0] "" Vector__XXX
 SG_ HVP_cpMiaFault : 5|1@1+ (1,0) [0|0] "" Vector__XXX
 SG_ HVP_bmsMiaFault : 4|1@1+ (1,0) [0|0] "" Vector__XXX
 SG_ HVP_primaryBmbMiaFault : 3|1@1+ (1,0) [0|0] "" Vector__XXX
 SG_ HVP_underVoltageFault : 2|1@1+ (1,0) [0|0] "" Vector__XXX
 SG_ HVP_overVoltageFault : 1|1@1+ (1,0) [0|0] "" Vector__XXX
 SG_ HVP_overTemperatureFault : 0|1@1+ (1,0) [0|0] "" Vector__XXX

BO_ 1698 PMR_stateLowFlow: 4 Vector__XXX
 SG_ PMR_fluidError : 24|7@1+ (0.01,0) [0|0] "" Vector__XXX
 SG_ PMR_deltahsError : 16|7@1+ (0.01,0) [0|0] "" Vector__XXX
 SG_ PMR_hs2Error : 8|7@1+ (0.01,0) [0|0] "" Vector__XXX
 SG_ PMR_hs1Error : 0|7@1+ (0.01,0) [0|0] "" Vector__XXX

BO_ 1723 UDS_sdcrRequest: 8 Vector__XXX
 SG_ UDS_sdcrRequestData : 7|64@0+ (1,0) [0|0] "" Vector__XXX

BO_ 1736 EPBL_statsOutput: 8 Vector__XXX
 SG_ EPBL_staticApplyCountsVeryCold m0 : 44|20@1+ (1,0) [0|0] "" Vector__XXX
 SG_ EPBL_staticApplyCountsCold m0 : 24|20@1+ (1,0) [0|0] "" Vector__XXX
 SG_ EPBL_dynamicApplyCounts m1 : 8|32@1+ (1,0) [0|0] "" Vector__XXX
 SG_ EPBL_staticApplyCounts m0 : 2|20@1+ (1,0) [0|0] "" Vector__XXX
 SG_ EPBL_statsOutputIndex M : 0|2@1+ (1,0) [0|0] "" Vector__XXX

BO_ 1748 PMR_info: 8 Vector__XXX
 SG_ PMR_componentId m10 : 48|16@1+ (1,0) [0|0] "" Vector__XXX
 SG_ PMR_subUsageId m11 : 48|16@1+ (1,0) [0|0] "" Vector__XXX
 SG_ PMR_applicationCrc m13 : 32|32@1+ (1,0) [0|0] "" Vector__XXX
 SG_ PMR_bootloaderCrc m20 : 32|32@1+ (1,0) [0|0] "" Vector__XXX
 SG_ PMR_diNodeApplicationCrc m21 : 32|32@1+ (1,0) [0|0] "" Vector__XXX
 SG_ PMR_hardwareId m10 : 32|8@1+ (1,0) [0|0] "" Vector__XXX
 SG_ PMR_usageId m11 : 32|16@1+ (1,0) [0|0] "" Vector__XXX
 SG_ PMR_assemblyId m11 : 24|8@1+ (1,0) [0|0] "" Vector__XXX
 SG_ PMR_buildConfigurationId m10 : 16|16@1+ (1,0) [0|0] "" Vector__XXX
 SG_ PMR_diNodeBuildConfigurationId m21 : 16|16@1+ (1,0) [0|0] "" Vector__XXX
 SG_ PMR_pcbaId m11 : 16|8@1+ (1,0) [0|0] "" Vector__XXX
 SG_ PMR_appGitHash m17 : 8|56@1+ (1,0) [0|0] "" Vector__XXX
 SG_ PMR_bootGitHash m18 : 8|56@1+ (1,0) [0|0] "" Vector__XXX
 SG_ PMR_buildType m10 : 8|8@1+ (1,0) [0|0] "" Vector__XXX
 SG_ PMR_diNodeBuildType m21 : 8|8@1+ (1,0) [0|0] "" Vector__XXX
 SG_ PMR_platformTyp m19 : 8|8@1+ (1,0) [0|0] "" Vector__XXX
 SG_ PMR_udsProtocolVersion m20 : 8|8@1+ (1,0) [0|0] "" Vector__XXX
 SG_ PMR_infoIndex M : 0|8@1+ (1,0) [0|0] "" Vector__XXX

BO_ 1768 EPBR_statsOutput: 8 Vector__XXX
 SG_ EPBR_staticApplyCountsVeryCold m0 : 44|20@1+ (1,0) [0|0] "" Vector__XXX
 SG_ EPBR_staticApplyCountsCold m0 : 24|20@1+ (1,0) [0|0] "" Vector__XXX
 SG_ EPBR_dynamicApplyCounts m1 : 8|32@1+ (1,0) [0|0] "" Vector__XXX
 SG_ EPBR_staticApplyCounts m0 : 2|20@1+ (1,0) [0|0] "" Vector__XXX
 SG_ EPBR_statsOutputIndex M : 0|2@1+ (1,0) [0|0] "" Vector__XXX

BO_ 1799 DBG_intrusionSensor: 8 Vector__XXX
 SG_ DBG_IS_Reserved_06 : 23|1@1+ (1,0) [0|0] "" Vector__XXX
 SG_ DBG_IS_Siren_Alarm_Cycles : 22|1@1+ (1,0) [0|0] "" Vector__XXX
 SG_ DBG_IS_Siren_Tone : 21|1@1+ (1,0) [0|0] "" Vector__XXX
 SG_ DBG_IS_Siren_Beep_Duration : 19|2@1+ (1,0) [0|0] "" Vector__XXX
 SG_ DBG_IS_Siren_Beep_Type : 17|2@1+ (1,0) [0|0] "" Vector__XXX
 SG_ DBG_IS_Siren_Alarm : 16|1@1+ (1,0) [0|0] "" Vector__XXX
 SG_ DBG_IS_Reserved_05 : 15|1@1+ (1,0) [0|0] "" Vector__XXX
 SG_ DBG_IS_Reserved_04 : 14|1@1+ (1,0) [0|0] "" Vector__XXX
 SG_ DBG_IS_Reserved_03 : 13|1@1+ (1,0) [0|0] "" Vector__XXX
 SG_ DBG_IS_Reserved_02 : 12|1@1+ (1,0) [0|0] "" Vector__XXX
 SG_ DBG_IS_Vehicles_Settings : 8|4@1+ (1,0) [0|0] "" Vector__XXX
 SG_ DBG_IS_Suspensions : 7|1@1+ (1,0) [0|0] "" Vector__XXX
 SG_ DBG_IS_Reserved_01 : 6|1@1+ (1,0) [0|0] "" Vector__XXX
 SG_ DBG_IS_Window : 5|1@1+ (1,0) [0|0] "" Vector__XXX
 SG_ DBG_IS_Heater : 4|1@1+ (1,0) [0|0] "" Vector__XXX
 SG_ DBG_IS_Air_Conditioned : 3|1@1+ (1,0) [0|0] "" Vector__XXX
 SG_ DBG_IS_USS_Operation : 0|3@1+ (1,0) [0|0] "" Vector__XXX

BO_ 1800 EPBL_CPULoad: 5 Vector__XXX
 SG_ EPBL_CPULoad1000msTask : 32|8@1+ (1,0) [0|0] "" Vector__XXX
 SG_ EPBL_CPULoad100msTask : 24|8@1+ (1,0) [0|0] "" Vector__XXX
 SG_ EPBL_CPULoad10msTask : 16|8@1+ (1,0) [0|0] "" Vector__XXX
 SG_ EPBL_CPULoad1msTask : 8|8@1+ (1,0) [0|0] "" Vector__XXX
 SG_ EPBL_CPULoadTotal : 0|8@1+ (1,0) [0|0] "" Vector__XXX

BO_ 1802 VCLEFT_logging0point1Hz: 5 Vector__XXX
 SG_ VCLEFT_leftBrakeLightCurrentSenseState m0 : 37|3@1+ (1,0) [0|0] "" Vector__XXX
 SG_ VCLEFT_leftBrakeLightCurrent m0 : 28|9@1+ (0.005,0) [0|0] "" Vector__XXX
 SG_ VCLEFT_leftRearTurnLightCurrentSenseState m0 : 24|3@1+ (1,0) [0|0] "" Vector__XXX
 SG_ VCLEFT_leftRearTurnLightCurrent m0 : 14|9@1+ (0.002,0) [0|0] "" Vector__XXX
 SG_ VCLEFT_leftTailLightCurrentSenseState m0 : 11|3@1+ (1,0) [0|0] "" Vector__XXX
 SG_ VCLEFT_leftTailLightCurrent m0 : 2|9@1+ (0.002,0) [0|0] "" Vector__XXX
 SG_ VCLEFT_logging0point1HzIndex M : 0|1@1+ (1,0) [0|0] "" Vector__XXX

BO_ 1803 VCRIGHT_logging0point1Hz: 8 Vector__XXX
 SG_ VCRIGHT_exteriorNightLightCurrentSenseState m0 : 61|3@1+ (1,0) [0|0] "" Vector__XXX
 SG_ VCRIGHT_leftTrunkLightCurrentSenseState m1 : 61|3@1+ (1,0) [0|0] "" Vector__XXX
 SG_ VCRIGHT_cabinTempBreathLevelF5minCooling m8 : 56|8@1+ (0.5,-40) [0|0] "" Vector__XXX
 SG_ VCRIGHT_hvacIntakeEndStop m3 : 56|8@1+ (0.02,0) [0|0] "" Vector__XXX
 SG_ VCRIGHT_hvacIntakeZeroStop m4 : 56|8@1+ (0.02,0) [0|0] "" Vector__XXX
 SG_ VCRIGHT_interiorCameraLedCurrent m6 : 56|8@1+ (8,0) [0|0] "" Vector__XXX
 SG_ VCRIGHT_airDistributionModeAdjustmentFactor m2 : 55|9@1+ (0.001,1) [0|0] "" Vector__XXX
 SG_ VCRIGHT_exteriorNightLightCurrent m0 : 52|9@1+ (0.002,0) [0|0] "" Vector__XXX
 SG_ VCRIGHT_leftTrunkLightCurrent m1 : 52|9@1+ (0.002,0) [0|0] "" Vector__XXX
 SG_ VCRIGHT_rearFogLightCurrentSenseState m1 : 49|3@1+ (1,0) [0|0] "" Vector__XXX
 SG_ VCRIGHT_rightTailLightCurrentSenseState m0 : 49|3@1+ (1,0) [0|0] "" Vector__XXX
 SG_ VCRIGHT_cabinTempBreathLevelF5minHeating m8 : 48|8@1+ (0.5,-40) [0|0] "" Vector__XXX
 SG_ VCRIGHT_hvacLowerModeEndStop m3 : 48|8@1+ (0.02,0) [0|0] "" Vector__XXX
 SG_ VCRIGHT_hvacLowerModeZeroStop m4 : 48|8@1+ (0.02,0) [0|0] "" Vector__XXX
 SG_ VCRIGHT_silentWakeRecordCount m6 : 48|5@1+ (1,0) [0|0] "" Vector__XXX
 SG_ VCRIGHT_cabinTempBreathLevelFOff m2 : 47|8@1+ (0.5,-40) [0|0] "" Vector__XXX
 SG_ VCRIGHT_cabinFilterHealthScore m2 : 40|7@1+ (1,0) [0|0] "" Vector__XXX
 SG_ VCRIGHT_cabinTempBreathLevelF10minCooling m8 : 40|8@1+ (0.5,-40) [0|0] "" Vector__XXX
 SG_ VCRIGHT_hvacUpperModeEndStop m3 : 40|8@1+ (0.02,0) [0|0] "" Vector__XXX
 SG_ VCRIGHT_hvacUpperModeZeroStop m4 : 40|8@1+ (0.02,0) [0|0] "" Vector__XXX
 SG_ VCRIGHT_rearFogLightCurrent m1 : 40|9@1+ (0.002,0) [0|0] "" Vector__XXX
 SG_ VCRIGHT_rightTailLightCurrent m0 : 40|9@1+ (0.002,0) [0|0] "" Vector__XXX
 SG_ VCRIGHT_thsSolarIrradianceLimp m6 : 40|8@1+ (5,0) [0|0] "" Vector__XXX
 SG_ VCRIGHT_rightBrakeLightCurrentSenseState m0 : 37|3@1+ (1,0) [0|0] "" Vector__XXX
 SG_ VCRIGHT_rightTrunkLightCurrentSenseState m1 : 37|3@1+ (1,0) [0|0] "" Vector__XXX
 SG_ VCRIGHT_cabinTempBreathLevelF10minHeating m8 : 32|8@1+ (0.5,-40) [0|0] "" Vector__XXX
 SG_ VCRIGHT_hepaFilterHealthScore m2 : 32|7@1+ (1,0) [0|0] "" Vector__XXX
 SG_ VCRIGHT_hvacRHVaneEndStop m3 : 32|8@1+ (0.02,0) [0|0] "" Vector__XXX
 SG_ VCRIGHT_hvacRHVaneZeroStop m4 : 32|8@1+ (0.02,0) [0|0] "" Vector__XXX
 SG_ VCRIGHT_thsCabinWaterMassLimp m6 : 32|8@1+ (0.5,0) [0|0] "" Vector__XXX
 SG_ VCRIGHT_rightBrakeLightCurrent m0 : 28|9@1+ (0.005,0) [0|0] "" Vector__XXX
 SG_ VCRIGHT_rightTrunkLightCurrent m1 : 28|9@1+ (0.002,0) [0|0] "" Vector__XXX
 SG_ VCRIGHT_rightPTCCompromisedRod m2 : 27|3@1+ (1,0) [0|0] "" Vector__XXX
 SG_ VCRIGHT_leftLiftgateTailLightCurrentSenseState m0 : 25|3@1+ (1,0) [0|0] "" Vector__XXX
 SG_ VCRIGHT_reverseLightCurrentSenseState m1 : 25|3@1+ (1,0) [0|0] "" Vector__XXX
 SG_ VCRIGHT_hvacLHVaneEndStop m3 : 24|8@1+ (0.02,0) [0|0] "" Vector__XXX
 SG_ VCRIGHT_hvacLHVaneZeroStop m4 : 24|8@1+ (0.02,0) [0|0] "" Vector__XXX
 SG_ VCRIGHT_leftPTCCompromisedRod m2 : 24|3@1+ (1,0) [0|0] "" Vector__XXX
 SG_ VCRIGHT_tempIncarCabinDeep m8 : 24|8@1+ (0.5,-40) [0|0] "" Vector__XXX
 SG_ VCRIGHT_thsTempLimp m6 : 24|8@1+ (0.5,-40) [0|0] "" Vector__XXX
 SG_ VCRIGHT_rightRearTurnLightCurrentSenseState m0 : 22|3@1+ (1,0) [0|0] "" Vector__XXX
 SG_ VCRIGHT_HEPAAirFilterLifeRemaining m2 : 17|7@1+ (1,0) [0|0] "" Vector__XXX
 SG_ VCRIGHT_cabinProbeTempLimp m6 : 16|8@1+ (0.5,-40) [0|0] "" Vector__XXX
 SG_ VCRIGHT_evapLoadInRecirc m8 : 16|8@1+ (35,0) [0|0] "" Vector__XXX
 SG_ VCRIGHT_hvacRHBleedEndStop m3 : 16|8@1+ (0.02,0) [0|0] "" Vector__XXX
 SG_ VCRIGHT_hvacRHBleedZeroStop m4 : 16|8@1+ (0.02,0) [0|0] "" Vector__XXX
 SG_ VCRIGHT_reverseLightCurrent m1 : 16|9@1+ (0.002,0) [0|0] "" Vector__XXX
 SG_ VCRIGHT_licensePlateLightCurrentSenseState m1 : 13|3@1+ (1,0) [0|0] "" Vector__XXX
 SG_ VCRIGHT_rightRearTurnLightCurrent m0 : 13|9@1+ (0.002,0) [0|0] "" Vector__XXX
 SG_ VCRIGHT_cabinAirFilterLifeRemaining m2 : 10|7@1+ (1,0) [0|0] "" Vector__XXX
 SG_ VCRIGHT_ambientTempLimp m6 : 8|8@1+ (0.5,-40) [0|0] "" Vector__XXX
 SG_ VCRIGHT_evapCondensateMass m7 : 8|8@1+ (2,0) [0|0] "" Vector__XXX
 SG_ VCRIGHT_evapLoadInFresh m8 : 8|8@1+ (35,0) [0|0] "" Vector__XXX
 SG_ VCRIGHT_hvacLHBleedEndStop m3 : 8|8@1+ (0.02,0) [0|0] "" Vector__XXX
 SG_ VCRIGHT_hvacLHBleedZeroStop m4 : 8|8@1+ (0.02,0) [0|0] "" Vector__XXX
 SG_ VCRIGHT_foggingMonitorRuntime m9 : 4|12@1+ (10,0) [0|0] "" Vector__XXX
 SG_ VCRIGHT_leftLiftgateTailLightCurrent m0 : 4|7@1+ (0.002,0) [0|0] "" Vector__XXX
 SG_ VCRIGHT_licensePlateLightCurrent m1 : 4|9@1+ (0.002,0) [0|0] "" Vector__XXX
 SG_ VCRIGHT_logging0point1HzIndex M : 0|4@1+ (1,0) [0|0] "" Vector__XXX

BO_ 1810 BMS_packTemperatureMeasurements: 8 Vector__XXX
 SG_ BMS_packTemperature12 m3 : 48|16@1- (0.01,0) [0|0] "" Vector__XXX
 SG_ BMS_packTemperature15 m4 : 48|16@1- (0.01,0) [0|0] "" Vector__XXX
 SG_ BMS_packTemperature18 m5 : 48|16@1- (0.01,0) [0|0] "" Vector__XXX
 SG_ BMS_packTemperature3 m0 : 48|16@1- (0.01,0) [0|0] "" Vector__XXX
 SG_ BMS_packTemperature6 m1 : 48|16@1- (0.01,0) [0|0] "" Vector__XXX
 SG_ BMS_packTemperature9 m2 : 48|16@1- (0.01,0) [0|0] "" Vector__XXX
 SG_ BMS_packTemperature11 m3 : 32|16@1- (0.01,0) [0|0] "" Vector__XXX
 SG_ BMS_packTemperature14 m4 : 32|16@1- (0.01,0) [0|0] "" Vector__XXX
 SG_ BMS_packTemperature17 m5 : 32|16@1- (0.01,0) [0|0] "" Vector__XXX
 SG_ BMS_packTemperature2 m0 : 32|16@1- (0.01,0) [0|0] "" Vector__XXX
 SG_ BMS_packTemperature5 m1 : 32|16@1- (0.01,0) [0|0] "" Vector__XXX
 SG_ BMS_packTemperature8 m2 : 32|16@1- (0.01,0) [0|0] "" Vector__XXX
 SG_ BMS_packTemperature1 m0 : 16|16@1- (0.01,0) [0|0] "" Vector__XXX
 SG_ BMS_packTemperature10 m3 : 16|16@1- (0.01,0) [0|0] "" Vector__XXX
 SG_ BMS_packTemperature13 m4 : 16|16@1- (0.01,0) [0|0] "" Vector__XXX
 SG_ BMS_packTemperature16 m5 : 16|16@1- (0.01,0) [0|0] "" Vector__XXX
 SG_ BMS_packTemperature4 m1 : 16|16@1- (0.01,0) [0|0] "" Vector__XXX
 SG_ BMS_packTemperature7 m2 : 16|16@1- (0.01,0) [0|0] "" Vector__XXX
 SG_ BMS_packTemperatureCounter : 14|2@1+ (1,0) [0|0] "" Vector__XXX
 SG_ BMS_packTemperatureStatus12 m3 : 12|2@1+ (1,0) [0|0] "" Vector__XXX
 SG_ BMS_packTemperatureStatus15 m4 : 12|2@1+ (1,0) [0|0] "" Vector__XXX
 SG_ BMS_packTemperatureStatus18 m5 : 12|2@1+ (1,0) [0|0] "" Vector__XXX
 SG_ BMS_packTemperatureStatus3 m0 : 12|2@1+ (1,0) [0|0] "" Vector__XXX
 SG_ BMS_packTemperatureStatus6 m1 : 12|2@1+ (1,0) [0|0] "" Vector__XXX
 SG_ BMS_packTemperatureStatus9 m2 : 12|2@1+ (1,0) [0|0] "" Vector__XXX
 SG_ BMS_packTemperatureStatus11 m3 : 10|2@1+ (1,0) [0|0] "" Vector__XXX
 SG_ BMS_packTemperatureStatus14 m4 : 10|2@1+ (1,0) [0|0] "" Vector__XXX
 SG_ BMS_packTemperatureStatus17 m5 : 10|2@1+ (1,0) [0|0] "" Vector__XXX
 SG_ BMS_packTemperatureStatus2 m0 : 10|2@1+ (1,0) [0|0] "" Vector__XXX
 SG_ BMS_packTemperatureStatus5 m1 : 10|2@1+ (1,0) [0|0] "" Vector__XXX
 SG_ BMS_packTemperatureStatus8 m2 : 10|2@1+ (1,0) [0|0] "" Vector__XXX
 SG_ BMS_packTemperatureStatus1 m0 : 8|2@1+ (1,0) [0|0] "" Vector__XXX
 SG_ BMS_packTemperatureStatus10 m3 : 8|2@1+ (1,0) [0|0] "" Vector__XXX
 SG_ BMS_packTemperatureStatus13 m4 : 8|2@1+ (1,0) [0|0] "" Vector__XXX
 SG_ BMS_packTemperatureStatus16 m5 : 8|2@1+ (1,0) [0|0] "" Vector__XXX
 SG_ BMS_packTemperatureStatus4 m1 : 8|2@1+ (1,0) [0|0] "" Vector__XXX
 SG_ BMS_packTemperatureStatus7 m2 : 8|2@1+ (1,0) [0|0] "" Vector__XXX
 SG_ BMS_packTemperatureMultiplexer M : 0|8@1+ (1,0) [0|0] "" Vector__XXX

BO_ 1815 RCM_imuOffsets: 7 Vector__XXX
 SG_ RCM_CGZdistance m2 : 40|16@1+ (1,-32768) [0|0] "" Vector__XXX
 SG_ RCM_rollRateOffset m0 : 40|16@1- (0.0001,0) [0|0] "" Vector__XXX
 SG_ RCM_verticalAccelOffset m1 : 40|16@1- (0.00125,0) [0|0] "" Vector__XXX
 SG_ RCM_CGYdistance m2 : 24|16@1+ (1,-32768) [0|0] "" Vector__XXX
 SG_ RCM_lateralAccelOffset m1 : 24|16@1- (0.00125,0) [0|0] "" Vector__XXX
 SG_ RCM_pitchRateOffset m0 : 24|16@1- (0.0001,0) [0|0] "" Vector__XXX
 SG_ RCM_CGXdistance m2 : 8|16@1+ (1,-32768) [0|0] "" Vector__XXX
 SG_ RCM_longitudinalAccelOffset m1 : 8|16@1- (0.00125,0) [0|0] "" Vector__XXX
 SG_ RCM_yawRateOffset m0 : 8|16@1- (0.0001,0) [0|0] "" Vector__XXX
 SG_ RCM_imuOffsetsIndex M : 0|2@1+ (1,0) [0|0] "" Vector__XXX

BO_ 1816 VC_LVBMS_statusLow: 8 Vector__XXX
 SG_ VC_LVBMS_MosfetStuckOpenError m0 : 51|1@1+ (1,0) [0|0] "" Vector__XXX
 SG_ VC_LVBMS_MosfetStuckCloseError m0 : 50|1@1+ (1,0) [0|0] "" Vector__XXX
 SG_ VC_LVBMS_SamplingError m0 : 49|1@1+ (1,0) [0|0] "" Vector__XXX
 SG_ VC_LVBMS_DeepDischargeFlag m0 : 48|1@1+ (1,0) [0|0] "" Vector__XXX
 SG_ VC_LVBMS_SOP m1 : 48|8@1+ (20,0) [0|0] "" Vector__XXX
 SG_ VC_LVBMS_NTCTempDiffWarnLevel1 m0 : 47|1@1+ (1,0) [0|0] "" Vector__XXX
 SG_ VC_LVBMS_MOSStateFault m0 : 46|1@1+ (1,0) [0|0] "" Vector__XXX
 SG_ VC_LVBMS_BalanceCircuitFault m0 : 45|1@1+ (1,0) [0|0] "" Vector__XXX
 SG_ VC_LVBMS_KBValueLostFault m0 : 44|1@1+ (1,0) [0|0] "" Vector__XXX
 SG_ VC_LVBMS_MOSFETOTLevel1 m0 : 43|1@1+ (1,0) [0|0] "" Vector__XXX
 SG_ VC_LVBMS_ChrgOCLevel2 m0 : 42|1@1+ (1,0) [0|0] "" Vector__XXX
 SG_ VC_LVBMS_ChrgOCLevel1 m0 : 41|1@1+ (1,0) [0|0] "" Vector__XXX
 SG_ VC_LVBMS_usableEnergyAvailable m4 : 41|12@1+ (1,0) [0|0] "" Vector__XXX
 SG_ VC_LVBMS_DischrgOCLevel2 m0 : 40|1@1+ (1,0) [0|0] "" Vector__XXX
 SG_ VC_LVBMS_MaxSleepCurrent m3 : 40|16@1+ (0.01,-200) [0|0] "" Vector__XXX
 SG_ VC_LVBMS_MinSleepCurrent m2 : 40|16@1+ (0.01,-200) [0|0] "" Vector__XXX
 SG_ VC_LVBMS_dynamicSOCCorrection m4 : 40|1@1+ (1,0) [0|0] "" Vector__XXX
 SG_ VC_LVBMS_DischrgOCLevel1 m0 : 39|1@1+ (1,0) [0|0] "" Vector__XXX
 SG_ VC_LVBMS_staticSOCCorrection m4 : 39|1@1+ (1,0) [0|0] "" Vector__XXX
 SG_ VC_LVBMS_PackOVLevel2 m0 : 38|1@1+ (1,0) [0|0] "" Vector__XXX
 SG_ VC_LVBMS_PackOVLevel1 m0 : 37|1@1+ (1,0) [0|0] "" Vector__XXX
 SG_ VC_LVBMS_ModuleOTLevel1 m0 : 36|1@1+ (1,0) [0|0] "" Vector__XXX
 SG_ VC_LVBMS_CellUVLevel2 m0 : 35|1@1+ (1,0) [0|0] "" Vector__XXX
 SG_ VC_LVBMS_CellUVLevel1 m0 : 34|1@1+ (1,0) [0|0] "" Vector__XXX
 SG_ VC_LVBMS_CellOVLevel3 m0 : 33|1@1+ (1,0) [0|0] "" Vector__XXX
 SG_ VC_LVBMS_CellOVLevel2 m0 : 32|1@1+ (1,0) [0|0] "" Vector__XXX
 SG_ VC_LVBMS_minCellSOC m4 : 32|7@1+ (1,0) [0|0] "" Vector__XXX
 SG_ VC_LVBMS_CellOVLevel1 m0 : 31|1@1+ (1,0) [0|0] "" Vector__XXX
 SG_ VC_LVBMS_SOH m0 : 24|7@1+ (1,0) [0|0] "" Vector__XXX
 SG_ VC_LVBMS_TimeSlept m1 : 24|24@1+ (1,0) [0|0] "" Vector__XXX
 SG_ VC_LVBMS_maxCellSOC m4 : 24|7@1+ (1,0) [0|0] "" Vector__XXX
 SG_ VC_LVBMS_SOE m0 : 16|7@1+ (1,0) [0|0] "" Vector__XXX
 SG_ VC_LVBMS_AhCharged m2 : 8|32@1+ (0.001,0) [0|0] "" Vector__XXX
 SG_ VC_LVBMS_AhDischarged m3 : 8|32@1+ (0.001,0) [0|0] "" Vector__XXX
 SG_ VC_LVBMS_AvgSleepCurrent m1 : 8|16@1+ (0.01,-200) [0|0] "" Vector__XXX
 SG_ VC_LVBMS_SOC m0 : 8|7@1+ (1,0) [0|0] "" Vector__XXX
 SG_ VC_LVBMS_sumCellVoltageFiltered m4 : 8|16@1+ (0.001,0) [0|0] "" Vector__XXX
 SG_ VC_lvbmsStatusLowIndex M : 0|3@1+ (1,0) [0|0] "" Vector__XXX

BO_ 1824 VCSEC_ecuConfig: 5 Vector__XXX
 SG_ VCSEC_requestForConfig : 33|1@1+ (1,0) [0|0] "" Vector__XXX
 SG_ VCSEC_autoWriteConfig : 32|1@1+ (1,0) [0|0] "" Vector__XXX
 SG_ VCSEC_ECUConfigCRC32 : 0|32@1+ (1,0) [0|0] "" Vector__XXX

BO_ 1828 VCFRONT_loadShedDebugStatus: 3 Vector__XXX
 SG_ VCFRONT_loadShedStsBatteryPump_duty m1 : 16|7@1+ (1,0) [0|0] "" Vector__XXX
 SG_ VCFRONT_loadShedStsCondenserFan_duty m2 : 16|7@1+ (1,0) [0|0] "" Vector__XXX
 SG_ VCFRONT_loadShedStsPTPump_duty m3 : 16|7@1+ (1,0) [0|0] "" Vector__XXX
 SG_ VCFRONT_loadShedReasonAPHeater m0 : 4|9@1+ (1,0) [0|0] "" Vector__XXX
 SG_ VCFRONT_loadShedReasonAutopilot m5 : 4|9@1+ (1,0) [0|0] "" Vector__XXX
 SG_ VCFRONT_loadShedReasonBatteryPump m1 : 4|9@1+ (1,0) [0|0] "" Vector__XXX
 SG_ VCFRONT_loadShedReasonCondenserFan m2 : 4|9@1+ (1,0) [0|0] "" Vector__XXX
 SG_ VCFRONT_loadShedReasonMCUAudio m8 : 4|9@1+ (1,0) [0|0] "" Vector__XXX
 SG_ VCFRONT_loadShedReasonMCUGraphic m7 : 4|9@1+ (1,0) [0|0] "" Vector__XXX
 SG_ VCFRONT_loadShedReasonPCS m9 : 4|9@1+ (1,0) [0|0] "" Vector__XXX
 SG_ VCFRONT_loadShedReasonPTPump m3 : 4|9@1+ (1,0) [0|0] "" Vector__XXX
 SG_ VCFRONT_loadShedReasonTAS m4 : 4|9@1+ (1,0) [0|0] "" Vector__XXX
 SG_ VCFRONT_loadShedReasonUI m6 : 4|9@1+ (1,0) [0|0] "" Vector__XXX
 SG_ VCFRONT_loadShedDebugStatusIndex M : 0|4@1+ (1,0) [0|0] "" Vector__XXX

BO_ 1830 VCLEFT_loadShedDebugStatus: 3 Vector__XXX
 SG_ VCLEFT_loadShedStsHVACBlower_duty m1 : 16|7@1+ (1,0) [0|0] "" Vector__XXX
 SG_ VCLEFT_loadShedReason12VAuxLoads m0 : 8|7@1+ (1,0) [0|0] "" Vector__XXX
 SG_ VCLEFT_loadShedReasonHVACBlower m1 : 8|7@1+ (1,0) [0|0] "" Vector__XXX
 SG_ VCLEFT_loadShedReasonLiftgate m2 : 8|7@1+ (1,0) [0|0] "" Vector__XXX
 SG_ VCLEFT_loadShedReasonMirrorHeater m3 : 8|7@1+ (1,0) [0|0] "" Vector__XXX
 SG_ VCLEFT_loadShedReasonMotorEncoders m4 : 8|7@1+ (1,0) [0|0] "" Vector__XXX
 SG_ VCLEFT_loadShedReasonSTWInOut m10 : 8|7@1+ (1,0) [0|0] "" Vector__XXX
 SG_ VCLEFT_loadShedReasonSTWUpDown m11 : 8|7@1+ (1,0) [0|0] "" Vector__XXX
 SG_ VCLEFT_loadShedReasonSeatBackrest m5 : 8|7@1+ (1,0) [0|0] "" Vector__XXX
 SG_ VCLEFT_loadShedReasonSeatHeaters m7 : 8|7@1+ (1,0) [0|0] "" Vector__XXX
 SG_ VCLEFT_loadShedReasonSeatLift m6 : 8|7@1+ (1,0) [0|0] "" Vector__XXX
 SG_ VCLEFT_loadShedReasonSeatTilt m8 : 8|7@1+ (1,0) [0|0] "" Vector__XXX
 SG_ VCLEFT_loadShedReasonSeatTrack m9 : 8|7@1+ (1,0) [0|0] "" Vector__XXX
 SG_ VCLEFT_loadShedReasonUSBPorts m12 : 8|7@1+ (1,0) [0|0] "" Vector__XXX
 SG_ VCLEFT_loadShedReasonWindowMotorsFront m13 : 8|7@1+ (1,0) [0|0] "" Vector__XXX
 SG_ VCLEFT_loadShedReasonWindowMotorsRear m14 : 8|7@1+ (1,0) [0|0] "" Vector__XXX
 SG_ VCLEFT_loadShedDebugStatusIndex M : 0|4@1+ (1,0) [0|0] "" Vector__XXX

BO_ 1831 VCRIGHT_loadShedDebugStatus: 2 Vector__XXX
 SG_ VCRIGHT_loadShedReasonMirrorHeater m0 : 8|7@1+ (1,0) [0|0] "" Vector__XXX
 SG_ VCRIGHT_loadShedReasonMotorEncoders m1 : 8|7@1+ (1,0) [0|0] "" Vector__XXX
 SG_ VCRIGHT_loadShedReasonPremAudio m2 : 8|7@1+ (1,0) [0|0] "" Vector__XXX
 SG_ VCRIGHT_loadShedReasonRearDefroster m3 : 8|7@1+ (1,0) [0|0] "" Vector__XXX
 SG_ VCRIGHT_loadShedReasonSeatBackrest m4 : 8|7@1+ (1,0) [0|0] "" Vector__XXX
 SG_ VCRIGHT_loadShedReasonSeatHeaters m5 : 8|7@1+ (1,0) [0|0] "" Vector__XXX
 SG_ VCRIGHT_loadShedReasonSeatLift m6 : 8|7@1+ (1,0) [0|0] "" Vector__XXX
 SG_ VCRIGHT_loadShedReasonSeatTilt m7 : 8|7@1+ (1,0) [0|0] "" Vector__XXX
 SG_ VCRIGHT_loadShedReasonSeatTrack m8 : 8|7@1+ (1,0) [0|0] "" Vector__XXX
 SG_ VCRIGHT_loadShedReasonUSBPorts m9 : 8|7@1+ (1,0) [0|0] "" Vector__XXX
 SG_ VCRIGHT_loadShedReasonWindowMotorsFront m10 : 8|7@1+ (1,0) [0|0] "" Vector__XXX
 SG_ VCRIGHT_loadShedReasonWindowMotorsRear m11 : 8|7@1+ (1,0) [0|0] "" Vector__XXX
 SG_ VCRIGHT_loadShedDebugStatusIndex M : 0|4@1+ (1,0) [0|0] "" Vector__XXX

BO_ 1834 BMS_serialNumber: 8 Vector__XXX
 SG_ BMS_packSerialNumberByte07 m0 : 56|8@1+ (1,0) [0|0] "" Vector__XXX
 SG_ BMS_packSerialNumberByte14 m1 : 56|8@1+ (1,0) [0|0] "" Vector__XXX
 SG_ BMS_packSerialNumberByte06 m0 : 48|8@1+ (1,0) [0|0] "" Vector__XXX
 SG_ BMS_packSerialNumberByte13 m1 : 48|8@1+ (1,0) [0|0] "" Vector__XXX
 SG_ BMS_packSerialNumberByte05 m0 : 40|8@1+ (1,0) [0|0] "" Vector__XXX
 SG_ BMS_packSerialNumberByte12 m1 : 40|8@1+ (1,0) [0|0] "" Vector__XXX
 SG_ BMS_packSerialNumberByte04 m0 : 32|8@1+ (1,0) [0|0] "" Vector__XXX
 SG_ BMS_packSerialNumberByte11 m1 : 32|8@1+ (1,0) [0|0] "" Vector__XXX
 SG_ BMS_packSerialNumberByte03 m0 : 24|8@1+ (1,0) [0|0] "" Vector__XXX
 SG_ BMS_packSerialNumberByte10 m1 : 24|8@1+ (1,0) [0|0] "" Vector__XXX
 SG_ BMS_packSerialNumberByte02 m0 : 16|8@1+ (1,0) [0|0] "" Vector__XXX
 SG_ BMS_packSerialNumberByte09 m1 : 16|8@1+ (1,0) [0|0] "" Vector__XXX
 SG_ BMS_packSerialBirthDateBinned m2 : 8|32@1+ (1,0) [0|0] "" Vector__XXX
 SG_ BMS_packSerialNumberByte01 m0 : 8|8@1+ (1,0) [0|0] "" Vector__XXX
 SG_ BMS_packSerialNumberByte08 m1 : 8|8@1+ (1,0) [0|0] "" Vector__XXX
 SG_ BMS_serialNumberMultiplexer M : 0|2@1+ (1,0) [0|0] "" Vector__XXX

BO_ 1847 VCFRONT_LVBMS_info: 7 Vector__XXX
 SG_ VCFRONT_LVBMS_mfgYear m4 : 48|7@1+ (1,2011) [0|0] "" Vector__XXX
 SG_ VCFRONT_LVBMS_SubUsageId m0 : 40|16@1+ (1,0) [0|0] "" Vector__XXX
 SG_ VCFRONT_LVBMS_mfgMonth m4 : 40|4@1+ (1,0) [0|0] "" Vector__XXX
 SG_ VCFRONT_LVBMS_mfgDay m4 : 32|5@1+ (1,0) [0|0] "" Vector__XXX
 SG_ VCFRONT_LVBMS_AppCRC m1 : 24|32@1+ (1,0) [0|0] "" Vector__XXX
 SG_ VCFRONT_LVBMS_AssemblyId m0 : 24|16@1+ (1,0) [0|0] "" Vector__XXX
 SG_ VCFRONT_LVBMS_FWBuildType m3 : 8|8@1+ (1,0) [0|0] "" Vector__XXX
 SG_ VCFRONT_LVBMS_GitHash m2 : 8|16@1+ (1,0) [0|0] "" Vector__XXX
 SG_ VCFRONT_LVBMS_PcbaId m0 : 8|16@1+ (1,0) [0|0] "" Vector__XXX
 SG_ VCFRONT_LVBMS_UsageId m1 : 8|16@1+ (1,0) [0|0] "" Vector__XXX
 SG_ VCFRONT_LVBMS_serialNumber m4 : 8|24@1+ (1,0) [0|0] "" Vector__XXX
 SG_ VCFRONT_LVBMS_InfoIndex M : 0|8@1+ (1,0) [0|0] "" Vector__XXX

BO_ 1849 VCSEC_CPULoad: 5 Vector__XXX
 SG_ VCSEC_CPULoad1000msTask : 32|8@1+ (1,0) [0|0] "" Vector__XXX
 SG_ VCSEC_CPULoad100msTask : 24|8@1+ (1,0) [0|0] "" Vector__XXX
 SG_ VCSEC_CPULoad10msTask : 16|8@1+ (1,0) [0|0] "" Vector__XXX
 SG_ VCSEC_CPULoad1msTask : 8|8@1+ (1,0) [0|0] "" Vector__XXX
 SG_ VCSEC_CPULoadTotal : 0|8@1+ (1,0) [0|0] "" Vector__XXX

BO_ 1850 VC_LVBMS_brickMeasurements: 8 Vector__XXX
 SG_ VC_LVBMS_brickBalancingState2 m1 : 57|1@1+ (1,0) [0|0] "" Vector__XXX
 SG_ VC_LVBMS_brickBalancingState4 m2 : 57|1@1+ (1,0) [0|0] "" Vector__XXX
 SG_ VC_LVBMS_brickBalancingState1 m1 : 56|1@1+ (1,0) [0|0] "" Vector__XXX
 SG_ VC_LVBMS_brickBalancingState3 m2 : 56|1@1+ (1,0) [0|0] "" Vector__XXX
 SG_ VC_LVBMS_brickVoltage4 m0 : 50|13@1+ (0.001,0) [0|0] "" Vector__XXX
 SG_ VC_LVBMS_brickVoltage3 m0 : 37|13@1+ (0.001,0) [0|0] "" Vector__XXX
 SG_ VC_LVBMS_brickBalancingAh2 m1 : 32|24@1+ (0.001,0) [0|0] "" Vector__XXX
 SG_ VC_LVBMS_brickBalancingAh4 m2 : 32|24@1+ (0.001,0) [0|0] "" Vector__XXX
 SG_ VC_LVBMS_brickVoltage2 m0 : 24|13@1+ (0.001,0) [0|0] "" Vector__XXX
 SG_ VC_LVBMS_brickBalancingAh1 m1 : 8|24@1+ (0.001,0) [0|0] "" Vector__XXX
 SG_ VC_LVBMS_brickBalancingAh3 m2 : 8|24@1+ (0.001,0) [0|0] "" Vector__XXX
 SG_ VC_LVBMS_brickVoltage1 m0 : 8|13@1+ (0.001,0) [0|0] "" Vector__XXX
 SG_ VC_LVBMS_brickMeasurementsMultiplexer M : 0|6@1+ (1,0) [0|0] "" Vector__XXX

BO_ 1858 VCBATT1_LVBMS_statusHigh: 8 Vector__XXX
 SG_ VCBATT1_LVBMS_minBrickVoltageIndex m4 : 56|8@1+ (1,0) [0|0] "" Vector__XXX
 SG_ VCBATT1_LVBMS_MOSTemperature m0 : 50|12@1+ (0.5,-50) [0|0] "" Vector__XXX
 SG_ VCBATT1_LVBMS_maxAllowedDischargeCurrent m3 : 50|13@1+ (0.1,0) [0|0] "" Vector__XXX
 SG_ VCBATT1_LVBMS_estimatedPackOcv m2 : 48|16@1+ (0.001,0) [0|0] "" Vector__XXX
 SG_ VCBATT1_LVBMS_packTemperature m0 : 41|9@1+ (0.5,-50) [0|0] "" Vector__XXX
 SG_ VCBATT1_LVBMS_maxBrickVoltageIndex m1 : 40|8@1+ (1,0) [0|0] "" Vector__XXX
 SG_ VCBATT1_LVBMS_minBrickVoltage m4 : 40|13@1+ (0.001,0) [0|0] "" Vector__XXX
 SG_ VCBATT1_LVBMS_maxAllowedChargeCurrent m3 : 37|13@1+ (0.1,0) [0|0] "" Vector__XXX
 SG_ VCBATT1_LVPackCurrent m2 : 34|14@1- (0.1,0) [0|0] "" Vector__XXX
 SG_ VCBATT1_LVBMS_packVoltage m0 : 25|16@1+ (0.001,0) [0|0] "" Vector__XXX
 SG_ VCBATT1_LVBMS_avgBrickVoltage m4 : 24|13@1+ (0.001,0) [0|0] "" Vector__XXX
 SG_ VCBATT1_LVBMS_maxBrickVoltage m1 : 24|13@1+ (0.001,0) [0|0] "" Vector__XXX
 SG_ VCBATT1_LVPackChargeCurrentLimit m2 : 22|12@1+ (0.1,0) [0|0] "" Vector__XXX
 SG_ VCBATT1_LVBMS_cellAndArcProtEnabled m4 : 19|1@1+ (1,0) [0|0] "" Vector__XXX
 SG_ VCBATT1_LVBMS_currentTarget m3 : 19|18@1+ (0.001,-122) [0|0] "" Vector__XXX
 SG_ VCBATT1_LVBMS_chargeType m4 : 16|3@1+ (1,0) [0|0] "" Vector__XXX
 SG_ VCBATT1_LVBMS_LINWakeDisabled m4 : 14|1@1+ (1,0) [0|0] "" Vector__XXX
 SG_ VCBATT1_LVBMS_VehicleState m4 : 12|2@1+ (1,0) [0|0] "" Vector__XXX
 SG_ VCBATT1_LVBMS_MOSState m4 : 10|2@1+ (1,0) [0|0] "" Vector__XXX
 SG_ VCBATT1_LVBMS_ECPAState m4 : 8|2@1+ (1,0) [0|0] "" Vector__XXX
 SG_ VCBATT1_LVBMS_sumCellVoltage m1 : 8|16@1+ (0.001,0) [0|0] "" Vector__XXX
 SG_ VCBATT1_totalLVLoadCurrent m2 : 8|14@1- (0.1,0) [0|0] "" Vector__XXX
 SG_ VCBATT1_LVBMS_EnterHibernationCommand m4 : 7|1@1+ (1,0) [0|0] "" Vector__XXX
 SG_ VCBATT1_LVBMS_ResetLVBMSCommand m4 : 6|1@1+ (1,0) [0|0] "" Vector__XXX
 SG_ VCBATT1_LVBMS_ClearHistoricFaultCommand m4 : 5|1@1+ (1,0) [0|0] "" Vector__XXX
 SG_ VCBATT1_LVBMS_ClearErrorCntrCommand m4 : 4|1@1+ (1,0) [0|0] "" Vector__XXX
 SG_ VCBATT1_LVBMS_MOSCommand m4 : 3|1@1+ (1,0) [0|0] "" Vector__XXX
 SG_ VCBATT1_LVBMS_packCurrent m0 : 3|22@1+ (0.001,-2000) [0|0] "" Vector__XXX
 SG_ VCBATT1_LVBMS_voltageTarget m3 : 3|16@1+ (0.001,0) [0|0] "" Vector__XXX
 SG_ VCBATT1_lvbmsStatusHighIndex M : 0|3@1+ (1,0) [0|0] "" Vector__XXX

BO_ 1859 VCRIGHT_recallStatus: 1 Vector__XXX
 SG_ VCRIGHT_mirrorRecallStatus : 4|2@1+ (1,0) [0|0] "" Vector__XXX
 SG_ VCRIGHT_seatRecallStatus : 2|2@1+ (1,0) [0|0] "" Vector__XXX
 SG_ VCRIGHT_systemRecallStatus : 0|2@1+ (1,0) [0|0] "" Vector__XXX

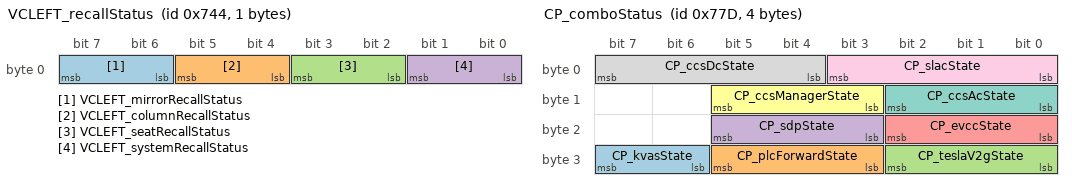
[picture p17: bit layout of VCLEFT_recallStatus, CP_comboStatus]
BO_ 1860 VCLEFT_recallStatus: 1 Vector__XXX
 SG_ VCLEFT_mirrorRecallStatus : 6|2@1+ (1,0) [0|0] "" Vector__XXX
 SG_ VCLEFT_columnRecallStatus : 4|2@1+ (1,0) [0|0] "" Vector__XXX
 SG_ VCLEFT_seatRecallStatus : 2|2@1+ (1,0) [0|0] "" Vector__XXX
 SG_ VCLEFT_systemRecallStatus : 0|2@1+ (1,0) [0|0] "" Vector__XXX

BO_ 1864 EPBR_CPULoad: 5 Vector__XXX
 SG_ EPBR_CPULoad1000msTask : 32|8@1+ (1,0) [0|0] "" Vector__XXX
 SG_ EPBR_CPULoad100msTask : 24|8@1+ (1,0) [0|0] "" Vector__XXX
 SG_ EPBR_CPULoad10msTask : 16|8@1+ (1,0) [0|0] "" Vector__XXX
 SG_ EPBR_CPULoad1msTask : 8|8@1+ (1,0) [0|0] "" Vector__XXX
 SG_ EPBR_CPULoadTotal : 0|8@1+ (1,0) [0|0] "" Vector__XXX

BO_ 1870 XCP_pmRequest: 8 Vector__XXX
 SG_ XCP_pmRequestData : 7|64@0+ (1,0) [0|0] "" Vector__XXX

BO_ 1871 PM_xcpResponse: 8 Vector__XXX
 SG_ PM_xcpResponseData : 7|64@0+ (1,0) [0|0] "" Vector__XXX

BO_ 1885 CP_loggingFast: 8 Vector__XXX
 SG_ CP_proxEn m1 : 63|1@1+ (1,0) [0|0] "" Vector__XXX
 SG_ CP_semiV2LatchNonLinear m3 : 63|1@1+ (1,0) [0|0] "" Vector__XXX
 SG_ CP_latchCheckAvailable m0 : 62|1@1+ (1,0) [0|0] "" Vector__XXX
 SG_ CP_proxConn1Sense m1 : 62|1@1+ (1,0) [0|0] "" Vector__XXX
 SG_ CP_chargeCablePresent m0 : 61|1@1+ (1,0) [0|0] "" Vector__XXX
 SG_ CP_doorIdDetectedBin m3 : 61|2@1+ (1,0) [0|0] "" Vector__XXX
 SG_ CP_chargeCableSecured m0 : 60|1@1+ (1,0) [0|0] "" Vector__XXX
 SG_ CP_doorPositionSource m5 : 60|2@1+ (1,0) [0|0] "" Vector__XXX
 SG_ CP_doorIdDetectionState m3 : 59|2@1+ (1,0) [0|0] "" Vector__XXX
 SG_ CP_doorObserverEstimationIsActive m5 : 59|1@1+ (1,0) [0|0] "" Vector__XXX
 SG_ CP_pilotUnlatchRequestActive m3 : 58|1@1+ (1,0) [0|0] "" Vector__XXX
 SG_ CP_latchEngagingStopReason m3 : 55|3@1+ (1,0) [0|0] "" Vector__XXX
 SG_ CP_latchLastDisengageMaxVelocity m4 : 54|10@1- (8.013698630136986,0) [0|0] "" Vector__XXX
 SG_ CP_doorPot m2 : 52|12@1+ (0.025,0) [0|0] "" Vector__XXX
 SG_ CP_latchDisengagingStopReason m3 : 52|3@1+ (1,0) [0|0] "" Vector__XXX
 SG_ CP_pilotPeriod m1 : 50|12@1+ (1,0) [0|0] "" Vector__XXX
 SG_ CP_doorPotObserverEstimated m5 : 47|12@1+ (0.025,0) [0|0] "" Vector__XXX
 SG_ CP_doorCloseActuationTime m0 : 46|14@1+ (1,0) [0|0] "" Vector__XXX
 SG_ CP_v2xAccessoryUpdateWithoutExternalPower m5 : 46|1@1+ (1,0) [0|0] "" Vector__XXX
 SG_ CP_evsePilotPowerNeeded m5 : 45|1@1+ (1,0) [0|0] "" Vector__XXX
 SG_ CP_latchLastEngageMaxVelocity m4 : 44|10@1- (8.013698630136986,0) [0|0] "" Vector__XXX
 SG_ CP_evseGridFormState m5 : 42|3@1+ (1,0) [0|0] "" Vector__XXX
 SG_ CP_latchEngagingTime m3 : 42|10@1+ (1,0) [0|0] "" Vector__XXX
 SG_ CP_evseGridFormRequestVersion m5 : 40|2@1+ (1,0) [0|0] "" Vector__XXX
 SG_ CP_pilotPulseWidth m1 : 38|12@1+ (1,0) [0|0] "" Vector__XXX
 SG_ CP_proximityV_GBCC2 m2 : 38|14@1+ (0.001,0) [0|0] "" Vector__XXX
 SG_ CP_digitalCommsAttempts m5 : 37|3@1+ (1,0) [0|0] "" Vector__XXX
 SG_ CP_latchLastDisengageRequestMaxI m4 : 34|10@1+ (0.004887585532746823,0) [0|0] "" Vector__XXX
 SG_ CP_doorOpenActuationTime m0 : 32|14@1+ (1,0) [0|0] "" Vector__XXX
 SG_ CP_latchDisengagingTime m3 : 32|10@1+ (1,0) [0|0] "" Vector__XXX
 SG_ CP_doorLastRequestMaxV m1 : 28|10@1+ (0.017595307917888565,0) [0|0] "" Vector__XXX
 SG_ CP_doorCloseRequest m3 : 27|5@1+ (1,0) [0|0] "" Vector__XXX
 SG_ CP_doorCloseEndOfDriveReason m3 : 24|3@1+ (1,0) [0|0] "" Vector__XXX
 SG_ CP_latchLastDisengageRequestMaxV m4 : 24|10@1+ (0.017595307917888565,0) [0|0] "" Vector__XXX
 SG_ CP_proximityV_GBCC1 m2 : 24|14@1+ (0.001,0) [0|0] "" Vector__XXX
 SG_ CP_coverClosed m3 : 23|1@1+ (1,0) [0|0] "" Vector__XXX
 SG_ CP_lastV2xShutdownTrigger m5 : 21|5@1+ (1,0) [0|0] "" Vector__XXX
 SG_ CP_doorOpenEndOfDriveReason m3 : 20|3@1+ (1,0) [0|0] "" Vector__XXX
 SG_ CP_activeV2xBlocker m5 : 16|5@1+ (1,0) [0|0] "" Vector__XXX
 SG_ CP_doorLastRequestMaxI m1 : 16|12@1+ (0.0025,0) [0|0] "" Vector__XXX
 SG_ CP_doorOpenRequest m3 : 16|4@1+ (1,0) [0|0] "" Vector__XXX
 SG_ CP_latchLastEngageRequestMaxI m4 : 14|10@1+ (0.004887585532746823,0) [0|0] "" Vector__XXX
 SG_ CP_v2xRetryAttempts m5 : 11|4@1+ (1,0) [0|0] "" Vector__XXX
 SG_ CP_proximityV m2 : 8|16@1+ (0.0001,0) [0|0] "" Vector__XXX
 SG_ CP_v2xCommsState m5 : 8|3@1+ (1,0) [0|0] "" Vector__XXX
 SG_ CP_UHF_controlState m2 : 4|4@1+ (1,0) [0|0] "" Vector__XXX
 SG_ CP_doorPresenceSensorV m3 : 4|12@1+ (0.001221,0) [0|0] "" Vector__XXX
 SG_ CP_inductiveSensor_raw m0 : 4|28@1+ (1,0) [0|0] "" Vector__XXX
 SG_ CP_latchLastEngageRequestMaxV m4 : 4|10@1+ (0.017595307917888565,0) [0|0] "" Vector__XXX
 SG_ CP_latchPot m1 : 4|12@1+ (0.025,0) [0|0] "" Vector__XXX
 SG_ CP_v2xState m5 : 4|3@1+ (1,0) [0|0] "" Vector__XXX
 SG_ CP_loggingFastSelect M : 0|4@1+ (1,0) [0|0] "" Vector__XXX

BO_ 1897 VCBATT1_xcpResponse: 8 Vector__XXX
 SG_ VCBATT1_xcpResponseData : 0|64@1+ (1,0) [0|0] "" Vector__XXX

BO_ 1914 HVP_log1hz: 8 Vector__XXX
 SG_ HVP_shuntAsicChipYCoordinate m0 : 56|8@1+ (1,0) [0|0] "" Vector__XXX
 SG_ HVP_energyReserveAvg m1 : 48|16@1- (0.001,0) [0|0] "" Vector__XXX
 SG_ HVP_shuntAsicChipXCoordinate m0 : 48|8@1+ (1,0) [0|0] "" Vector__XXX
 SG_ HVP_energyReserveMax m1 : 32|16@1- (0.001,0) [0|0] "" Vector__XXX
 SG_ HVP_pyroSquibResistance m0 : 32|16@1+ (0.001,0) [0|0] "" Vector__XXX
 SG_ HVP_energyReserveMin m1 : 16|16@1- (0.001,0) [0|0] "" Vector__XXX
 SG_ HVP_shuntAsicChipWaferNumber m1 : 8|8@1+ (1,0) [0|0] "" Vector__XXX
 SG_ HVP_shuntCurrentAuxLog m0 : 8|24@1- (0.001,0) [0|0] "" Vector__XXX
 SG_ HVP_gpioPcsEnable m1 : 7|1@1+ (1,0) [0|0] "" Vector__XXX
 SG_ HVP_gpioPcsChargePwmEnable m1 : 6|1@1+ (1,0) [0|0] "" Vector__XXX
 SG_ HVP_gpioPcsDcdcPwmEnable m1 : 5|1@1+ (1,0) [0|0] "" Vector__XXX
 SG_ HVP_bmbAsicType m0 : 3|2@1+ (1,0) [0|0] "" Vector__XXX
 SG_ HVP_hvilCalType m1 : 3|2@1+ (1,0) [0|0] "" Vector__XXX
 SG_ HVP_log1HzIndex M : 0|3@1+ (1,0) [0|0] "" Vector__XXX

BO_ 1917 CP_comboStatus: 4 Vector__XXX
 SG_ CP_kvasState : 30|2@1+ (1,0) [0|0] "" Vector__XXX
 SG_ CP_plcForwardState : 27|3@1+ (1,0) [0|0] "" Vector__XXX
 SG_ CP_teslaV2gState : 24|3@1+ (1,0) [0|0] "" Vector__XXX
 SG_ CP_sdpState : 19|3@1+ (1,0) [0|0] "" Vector__XXX
 SG_ CP_evccState : 16|3@1+ (1,0) [0|0] "" Vector__XXX
 SG_ CP_ccsManagerState : 11|3@1+ (1,0) [0|0] "" Vector__XXX
 SG_ CP_ccsAcState : 8|3@1+ (1,0) [0|0] "" Vector__XXX
 SG_ CP_ccsDcState : 4|4@1+ (1,0) [0|0] "" Vector__XXX
 SG_ CP_slacState : 0|4@1+ (1,0) [0|0] "" Vector__XXX

BO_ 1928 EPBL_debugOutput: 8 Vector__XXX
 SG_ EPBL_uiNotAvailable m0 : 62|1@1+ (1,0) [0|0] "" Vector__XXX
 SG_ EPBL_driverIsLeavingDisabled m0 : 61|1@1+ (1,0) [0|0] "" Vector__XXX
 SG_ EPBL_slopeParkable m0 : 60|1@1+ (1,0) [0|0] "" Vector__XXX
 SG_ EPBL_epbOpenUnableToPark m0 : 59|1@1+ (1,0) [0|0] "" Vector__XXX
 SG_ EPBL_brakePressHeld m0 : 58|1@1+ (1,0) [0|0] "" Vector__XXX
 SG_ EPBL_esmCaliperRequest m0 : 55|3@1+ (1,0) [0|0] "" Vector__XXX
 SG_ EPBL_12VFilt m1 : 52|9@1+ (0.043549408784,0) [0|0] "" Vector__XXX
 SG_ EPBL_lockoutUnlockCount m0 : 49|6@1+ (1,0) [0|0] "" Vector__XXX
 SG_ EPBL_brakeDiscWipeAccumul m2 : 48|8@1+ (1,0) [0|0] "" Vector__XXX
 SG_ EPBL_lockoutCommandDI m2 : 41|1@1+ (1,0) [0|0] "" Vector__XXX
 SG_ EPBL_lockoutOutputDI m2 : 40|1@1+ (1,0) [0|0] "" Vector__XXX
 SG_ EPBL_pid_error m1 : 40|12@1+ (0.016997132,-37.55274262) [0|0] "" Vector__XXX
 SG_ EPBL_currentVariance m0 : 35|14@1- (0.0007629394535064697,0) [0|0] "" Vector__XXX
 SG_ EPBL_atEndStop m0 : 34|1@1+ (1,0) [0|0] "" Vector__XXX
 SG_ EPBL_oocViolation m0 : 33|1@1+ (1,0) [0|0] "" Vector__XXX
 SG_ EPBL_nFault m0 : 32|1@1+ (1,0) [0|0] "" Vector__XXX
 SG_ EPBL_ramp m1 : 32|8@1+ (0.392157,0) [0|0] "" Vector__XXX
 SG_ EPBL_caliperState m0 : 29|3@1+ (1,0) [0|0] "" Vector__XXX
 SG_ EPBL_filteredCurrentPeak m2 : 28|12@1+ (0.01,0) [0|0] "" Vector__XXX
 SG_ EPBL_pid_duty m1 : 22|10@1- (0.2,0) [0|0] "" Vector__XXX
 SG_ EPBL_pvFilt m0 : 20|9@1+ (0.043549408784,0) [0|0] "" Vector__XXX
 SG_ EPBL_currentOffset m2 : 16|12@1+ (0.016997132,-37.55274262) [0|0] "" Vector__XXX
 SG_ EPBL_driverLockedOut m2 : 15|1@1+ (1,0) [0|0] "" Vector__XXX
 SG_ EPBL_dynamicManagerReady m2 : 14|1@1+ (1,0) [0|0] "" Vector__XXX
 SG_ EPBL_emergencyOperationMode m2 : 12|2@1+ (1,0) [0|0] "" Vector__XXX
 SG_ EPBL_pid_uI m1 : 12|10@1- (0.2,0) [0|0] "" Vector__XXX
 SG_ EPBL_nvFilt m0 : 11|9@1+ (0.043549408784,0) [0|0] "" Vector__XXX
 SG_ EPBL_12VFilt_SW m0 : 2|9@1+ (0.043549408784,0) [0|0] "" Vector__XXX
 SG_ EPBL_limpToDecelTimer m2 : 2|10@1+ (1,0) [0|0] "" Vector__XXX
 SG_ EPBL_pid_uP m1 : 2|10@1- (0.2,0) [0|0] "" Vector__XXX
 SG_ EPBL_debugOutputIndex M : 0|2@1+ (1,0) [0|0] "" Vector__XXX

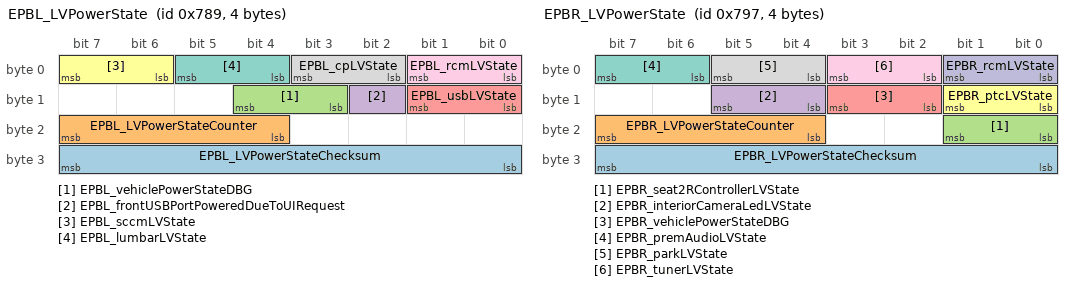
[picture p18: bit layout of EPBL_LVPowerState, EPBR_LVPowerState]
BO_ 1929 EPBL_LVPowerState: 4 Vector__XXX
 SG_ EPBL_LVPowerStateChecksum : 24|8@1+ (1,0) [0|0] "" Vector__XXX
 SG_ EPBL_LVPowerStateCounter : 20|4@1+ (1,0) [0|0] "" Vector__XXX
 SG_ EPBL_vehiclePowerStateDBG : 11|2@1+ (1,0) [0|0] "" Vector__XXX
 SG_ EPBL_frontUSBPortPoweredDueToUIRequest : 10|1@1+ (1,0) [0|0] "" Vector__XXX
 SG_ EPBL_usbLVState : 8|2@1+ (1,0) [0|0] "" Vector__XXX
 SG_ EPBL_sccmLVState : 6|2@1+ (1,0) [0|0] "" Vector__XXX
 SG_ EPBL_lumbarLVState : 4|2@1+ (1,0) [0|0] "" Vector__XXX
 SG_ EPBL_cpLVState : 2|2@1+ (1,0) [0|0] "" Vector__XXX
 SG_ EPBL_rcmLVState : 0|2@1+ (1,0) [0|0] "" Vector__XXX

BO_ 1930 HVP_pyroDeviceDbg: 8 Vector__XXX
 SG_ HVP_pyroAoutEr2 m1 : 48|16@1+ (0.001,0) [0|0] "" Vector__XXX
 SG_ HVP_pyroAoutGnd m5 : 48|16@1+ (0.001,0) [0|0] "" Vector__XXX
 SG_ HVP_pyroAoutLeakIgl1 m2 : 48|16@1+ (0.001,0) [0|0] "" Vector__XXX
 SG_ HVP_pyroAoutRref m3 : 48|16@1+ (0.001,0) [0|0] "" Vector__XXX
 SG_ HVP_pyroAoutSquibResIgl1 m4 : 48|16@1+ (0.001,0) [0|0] "" Vector__XXX
 SG_ HVP_pyroAoutVst2 m0 : 48|16@1+ (0.001,0) [0|0] "" Vector__XXX
 SG_ HVP_pyroAoutEr1 m1 : 32|16@1+ (0.001,0) [0|0] "" Vector__XXX
 SG_ HVP_pyroAoutHighsideSwitchIgh1 m5 : 32|16@1+ (0.001,0) [0|0] "" Vector__XXX
 SG_ HVP_pyroAoutLeakIgh1 m2 : 32|16@1+ (0.001,0) [0|0] "" Vector__XXX
 SG_ HVP_pyroAoutLowsideSwitchIgl1 m6 : 32|16@1+ (0.001,0) [0|0] "" Vector__XXX
 SG_ HVP_pyroAoutRm m3 : 32|16@1+ (0.001,0) [0|0] "" Vector__XXX
 SG_ HVP_pyroAoutSquibResIgh1 m4 : 32|16@1+ (0.001,0) [0|0] "" Vector__XXX
 SG_ HVP_pyroAoutVst1 m0 : 32|16@1+ (0.001,0) [0|0] "" Vector__XXX
 SG_ HVP_pyroAoutMultiplexer M : 16|3@1+ (1,0) [0|0] "" Vector__XXX
 SG_ HVP_pyroFiringHandle : 10|4@1+ (1,0) [0|0] "" Vector__XXX
 SG_ HVP_pyroSquibFired : 9|1@1+ (1,0) [0|0] "" Vector__XXX
 SG_ HVP_pyroTestPyroLeakFailed : 8|1@1+ (1,0) [0|0] "" Vector__XXX
 SG_ HVP_pyroTestLowSideSwitchFailed : 7|1@1+ (1,0) [0|0] "" Vector__XXX
 SG_ HVP_pyroTestHighSideSwitchFailed : 6|1@1+ (1,0) [0|0] "" Vector__XXX
 SG_ HVP_pyroTestVstFailed : 5|1@1+ (1,0) [0|0] "" Vector__XXX
 SG_ HVP_pyroTestErFailed : 4|1@1+ (1,0) [0|0] "" Vector__XXX
 SG_ HVP_pyroTestSquibResFailed : 3|1@1+ (1,0) [0|0] "" Vector__XXX
 SG_ HVP_pyroTestRefCurrentFailed : 2|1@1+ (1,0) [0|0] "" Vector__XXX
 SG_ HVP_pyroStatus : 0|2@1+ (1,0) [0|0] "" Vector__XXX

BO_ 1943 EPBR_LVPowerState: 4 Vector__XXX
 SG_ EPBR_LVPowerStateChecksum : 24|8@1+ (1,0) [0|0] "" Vector__XXX
 SG_ EPBR_LVPowerStateCounter : 20|4@1+ (1,0) [0|0] "" Vector__XXX
 SG_ EPBR_seat2RControllerLVState : 16|2@1+ (1,0) [0|0] "" Vector__XXX
 SG_ EPBR_interiorCameraLedLVState : 12|2@1+ (1,0) [0|0] "" Vector__XXX
 SG_ EPBR_vehiclePowerStateDBG : 10|2@1+ (1,0) [0|0] "" Vector__XXX
 SG_ EPBR_ptcLVState : 8|2@1+ (1,0) [0|0] "" Vector__XXX
 SG_ EPBR_premAudioLVState : 6|2@1+ (1,0) [0|0] "" Vector__XXX
 SG_ EPBR_parkLVState : 4|2@1+ (1,0) [0|0] "" Vector__XXX
 SG_ EPBR_tunerLVState : 2|2@1+ (1,0) [0|0] "" Vector__XXX
 SG_ EPBR_rcmLVState : 0|2@1+ (1,0) [0|0] "" Vector__XXX

BO_ 1944 EPBL_remoteADC: 8 Vector__XXX
 SG_ EPBL_remoteADCChecksum : 56|8@1+ (1,0) [0|0] "" Vector__XXX
 SG_ EPBL_remoteADCCounter : 52|4@1+ (1,0) [0|0] "" Vector__XXX
 SG_ EPBL_2ndRowLeftCushionTemp m3 : 34|10@1+ (0.0009775171065493646,0) [0|0] "" Vector__XXX
 SG_ EPBL_chargePortMonitor m4 : 34|10@1+ (0.017595307917888565,0) [0|0] "" Vector__XXX
 SG_ EPBL_liftGateStrutOpenMonitor m1 : 34|10@1+ (0.017595307917888565,0) [0|0] "" Vector__XXX
 SG_ EPBL_seatFrontTiltUpMonitor m0 : 34|10@1+ (0.017595307917888565,0) [0|0] "" Vector__XXX
 SG_ EPBL_steeringColumnUpMonitor m2 : 34|10@1+ (0.017595307917888565,0) [0|0] "" Vector__XXX
 SG_ EPBL_2ndRowCenterCushionTemp m3 : 24|10@1+ (0.0009775171065493646,0) [0|0] "" Vector__XXX
 SG_ EPBL_accessoryFeedAlwaysOnMonitor m2 : 24|10@1+ (0.017595307917888565,0) [0|0] "" Vector__XXX
 SG_ EPBL_liftGateStrutCloseMonitor m1 : 24|10@1+ (0.017595307917888565,0) [0|0] "" Vector__XXX
 SG_ EPBL_seatFrontLiftUpMonitor m0 : 24|10@1+ (0.017595307917888565,0) [0|0] "" Vector__XXX
 SG_ EPBL_securityControllerMonitor m4 : 24|10@1+ (0.017595307917888565,0) [0|0] "" Vector__XXX
 SG_ EPBL_2ndRowRightCushionTemp m3 : 13|10@1+ (0.0009775171065493646,0) [0|0] "" Vector__XXX
 SG_ EPBL_BLEMonitor m4 : 13|10@1+ (0.017595307917888565,0) [0|0] "" Vector__XXX
 SG_ EPBL_efuseNonContinuousMonitor m1 : 13|10@1+ (0.017595307917888565,0) [0|0] "" Vector__XXX
 SG_ EPBL_mirrorDimMonitor m2 : 13|10@1+ (0.004887585532746823,0) [0|0] "" Vector__XXX
 SG_ EPBL_windowLiftRearDownMonitor m0 : 13|10@1+ (0.017595307917888565,0) [0|0] "" Vector__XXX
 SG_ EPBL_PCBATemp m4 : 3|10@1+ (0.0009775171065493646,0) [0|0] "" Vector__XXX
 SG_ EPBL_efuseContinousMonitor m1 : 3|10@1+ (0.017595307917888565,0) [0|0] "" Vector__XXX
 SG_ EPBL_frontCushionTemp m3 : 3|10@1+ (0.0009775171065493646,0) [0|0] "" Vector__XXX
 SG_ EPBL_seatFrontBackRestUpMonitor m2 : 3|10@1+ (0.017595307917888565,0) [0|0] "" Vector__XXX
 SG_ EPBL_trailerAuxMonitor m6 : 3|10@1+ (0.017595307917888565,0) [0|0] "" Vector__XXX
 SG_ EPBL_windowLiftFrontUpMonitor m0 : 3|10@1+ (0.017595307917888565,0) [0|0] "" Vector__XXX
 SG_ EPBL_remoteADCIndex M : 0|3@1+ (1,0) [0|0] "" Vector__XXX

BO_ 1949 V2G_evseLogData: 8 Vector__XXX
 SG_ V2G_chgParamRes_isoState_val m7 : 62|1@1+ (1,0) [0|0] "" Vector__XXX
 SG_ V2G_currDemRes_isoState m11 : 61|3@1+ (1,0) [0|0] "" Vector__XXX
 SG_ V2G_currDemRes_evseMaxPower_val m11 : 60|1@1+ (1,0) [0|0] "" Vector__XXX
 SG_ V2G_chgParamRes_isoState m7 : 59|3@1+ (1,0) [0|0] "" Vector__XXX
 SG_ V2G_chgParamRes_evseMaxPower_val m7 : 58|1@1+ (1,0) [0|0] "" Vector__XXX
 SG_ V2G_currDemRes_evseMaxPowerLim m11 : 52|8@1+ (5.9766,0) [0|0] "" Vector__XXX
 SG_ V2G_currDemRes_evseMaxVLim_val m11 : 51|1@1+ (1,0) [0|0] "" Vector__XXX
 SG_ V2G_chgParamRes_evseMaxPowerLim m7 : 50|8@1+ (5.9766,0) [0|0] "" Vector__XXX
 SG_ V2G_currDemRes_evseMaxVLim m11 : 43|8@1+ (4.688,0) [0|0] "" Vector__XXX
 SG_ V2G_chgParamRes_evseMinVLim m7 : 42|8@1+ (4.688,0) [0|0] "" Vector__XXX
 SG_ V2G_currDemRes_evseMaxILim_val m11 : 42|1@1+ (1,0) [0|0] "" Vector__XXX
 SG_ V2G_prechargeRes_isoState_val m9 : 35|1@1+ (1,0) [0|0] "" Vector__XXX
 SG_ V2G_chgParamRes_evseMinILim m7 : 34|8@1+ (7.032,0) [0|0] "" Vector__XXX
 SG_ V2G_currDemRes_evseMaxILim m11 : 34|8@1+ (7.032,0) [0|0] "" Vector__XXX
 SG_ V2G_prechargeRes_isoState m9 : 32|3@1+ (1,0) [0|0] "" Vector__XXX
 SG_ V2G_chgParamRes_evseMaxVLim m7 : 26|8@1+ (4.688,0) [0|0] "" Vector__XXX
 SG_ V2G_chargingStatusRes_rcd m12 : 24|1@1+ (1,0) [0|0] "" Vector__XXX
 SG_ V2G_currDemRes_outputI m11 : 24|10@1+ (1.7578125,0) [0|0] "" Vector__XXX
 SG_ V2G_cableCheckRes_isoState_val m8 : 23|1@1+ (1,0) [0|0] "" Vector__XXX
 SG_ V2G_chargingStatusRes_maxI_val m12 : 23|1@1+ (1,0) [0|0] "" Vector__XXX
 SG_ V2G_pwrDelEndRes_isoState_val m13 : 23|1@1+ (1,0) [0|0] "" Vector__XXX
 SG_ V2G_pwrDelStartRes_isoState_val m10 : 23|1@1+ (1,0) [0|0] "" Vector__XXX
 SG_ V2G_cableCheckRes_isoState m8 : 20|3@1+ (1,0) [0|0] "" Vector__XXX
 SG_ V2G_prechargeRes_outputV m9 : 20|10@1+ (1.171875,0) [0|0] "" Vector__XXX
 SG_ V2G_pwrDelEndRes_isoState m13 : 20|3@1+ (1,0) [0|0] "" Vector__XXX
 SG_ V2G_pwrDelStartRes_isoState m10 : 20|3@1+ (1,0) [0|0] "" Vector__XXX
 SG_ V2G_chgParamRes_evseMaxILim m7 : 18|8@1+ (7.032,0) [0|0] "" Vector__XXX
 SG_ V2G_cableCheckRes_evseStatus m8 : 16|4@1+ (1,0) [0|0] "" Vector__XXX
 SG_ V2G_chargingStatusRes_maxI m12 : 16|7@1+ (1,0) [0|0] "" Vector__XXX
 SG_ V2G_powerDelEndRes_evseStatus m13 : 16|4@1+ (1,0) [0|0] "" Vector__XXX
 SG_ V2G_powerDelStartRes_evseStatus m10 : 16|4@1+ (1,0) [0|0] "" Vector__XXX
 SG_ V2G_prechargeRes_evseStatus m9 : 16|4@1+ (1,0) [0|0] "" Vector__XXX
 SG_ V2G_serviceDiscRes_dcExtended m2 : 16|1@1+ (1,0) [0|0] "" Vector__XXX
 SG_ V2G_serviceDiscRes_evChgAvail m2 : 15|1@1+ (1,0) [0|0] "" Vector__XXX
 SG_ V2G_chgParamRes_evseStatus m7 : 14|4@1+ (1,0) [0|0] "" Vector__XXX
 SG_ V2G_currDemRes_outputV m11 : 14|10@1+ (1.171875,0) [0|0] "" Vector__XXX
 SG_ V2G_serviceDiscRes_pncAvail m2 : 14|1@1+ (1,0) [0|0] "" Vector__XXX
 SG_ V2G_cableCheckRes_finished m8 : 13|1@1+ (1,0) [0|0] "" Vector__XXX
 SG_ V2G_chgParamRes_finished m7 : 13|1@1+ (1,0) [0|0] "" Vector__XXX
 SG_ V2G_contractAuthRes_finished m6 : 13|1@1+ (1,0) [0|0] "" Vector__XXX
 SG_ V2G_serviceDiscRes_extPayAvail m2 : 13|1@1+ (1,0) [0|0] "" Vector__XXX
 SG_ V2G_currDemRes_evseStatus m11 : 10|4@1+ (1,0) [0|0] "" Vector__XXX
 SG_ V2G_cableCheckRes_respCode m8 : 8|5@1+ (1,0) [0|0] "" Vector__XXX
 SG_ V2G_chargingStatusRes_respCode m12 : 8|5@1+ (1,0) [0|0] "" Vector__XXX
 SG_ V2G_chgParamRes_respCode m7 : 8|5@1+ (1,0) [0|0] "" Vector__XXX
 SG_ V2G_contractAuthRes_respCode m6 : 8|5@1+ (1,0) [0|0] "" Vector__XXX
 SG_ V2G_paymentDetailsRes_respCode m5 : 8|5@1+ (1,0) [0|0] "" Vector__XXX
 SG_ V2G_powerDelEndRes_respCode m13 : 8|5@1+ (1,0) [0|0] "" Vector__XXX
 SG_ V2G_powerDelStartRes_respCode m10 : 8|5@1+ (1,0) [0|0] "" Vector__XXX
 SG_ V2G_prechargeRes_respCode m9 : 8|5@1+ (1,0) [0|0] "" Vector__XXX
 SG_ V2G_serviceDetailRes_respCode m3 : 8|5@1+ (1,0) [0|0] "" Vector__XXX
 SG_ V2G_serviceDiscoveryRes_respCode m2 : 8|5@1+ (1,0) [0|0] "" Vector__XXX
 SG_ V2G_servicePaymntSelRes_respCode m4 : 8|5@1+ (1,0) [0|0] "" Vector__XXX
 SG_ V2G_sessionSetupRes_respCode m1 : 8|5@1+ (1,0) [0|0] "" Vector__XXX
 SG_ V2G_sessionStopRes_respCode m14 : 8|5@1+ (1,0) [0|0] "" Vector__XXX
 SG_ V2G_suppAppProtocolRes_schemaId m0 : 8|8@1+ (1,0) [0|0] "" Vector__XXX
 SG_ V2G_currDemRes_isoState_val m13 : 5|1@1+ (1,0) [0|0] "" Vector__XXX
 SG_ V2G_currDemRes_respCode m11 : 5|5@1+ (1,0) [0|0] "" Vector__XXX
 SG_ V2G_suppAppProtocolRes_respCode m0 : 5|2@1+ (1,0) [0|0] "" Vector__XXX
 SG_ V2G_evseLogDataSelect M : 0|5@1+ (1,0) [0|0] "" Vector__XXX

BO_ 1960 EPBR_debugOutput: 8 Vector__XXX
 SG_ EPBR_uiNotAvailable m0 : 62|1@1+ (1,0) [0|0] "" Vector__XXX
 SG_ EPBR_driverIsLeavingDisabled m0 : 61|1@1+ (1,0) [0|0] "" Vector__XXX
 SG_ EPBR_slopeParkable m0 : 60|1@1+ (1,0) [0|0] "" Vector__XXX
 SG_ EPBR_epbOpenUnableToPark m0 : 59|1@1+ (1,0) [0|0] "" Vector__XXX
 SG_ EPBR_brakePressHeld m0 : 58|1@1+ (1,0) [0|0] "" Vector__XXX
 SG_ EPBR_esmCaliperRequest m0 : 55|3@1+ (1,0) [0|0] "" Vector__XXX
 SG_ EPBR_12VFilt m1 : 52|9@1+ (0.043549408784,0) [0|0] "" Vector__XXX
 SG_ EPBR_lockoutUnlockCount m0 : 49|6@1+ (1,0) [0|0] "" Vector__XXX
 SG_ EPBR_brakeDiscWipeAccumul m2 : 48|8@1+ (1,0) [0|0] "" Vector__XXX
 SG_ EPBR_lockoutCommandHVC m2 : 43|1@1+ (1,0) [0|0] "" Vector__XXX
 SG_ EPBR_lockoutOutputHVC m2 : 42|1@1+ (1,0) [0|0] "" Vector__XXX
 SG_ EPBR_lockoutCmdContactor m2 : 41|1@1+ (1,0) [0|0] "" Vector__XXX
 SG_ EPBR_lockoutOutContactor m2 : 40|1@1+ (1,0) [0|0] "" Vector__XXX
 SG_ EPBR_pid_error m1 : 40|12@1+ (0.016997132,-37.55274262) [0|0] "" Vector__XXX
 SG_ EPBR_currentVariance m0 : 35|14@1- (0.0007629394535064697,0) [0|0] "" Vector__XXX
 SG_ EPBR_atEndStop m0 : 34|1@1+ (1,0) [0|0] "" Vector__XXX
 SG_ EPBR_oocViolation m0 : 33|1@1+ (1,0) [0|0] "" Vector__XXX
 SG_ EPBR_nFault m0 : 32|1@1+ (1,0) [0|0] "" Vector__XXX
 SG_ EPBR_ramp m1 : 32|8@1+ (0.392157,0) [0|0] "" Vector__XXX
 SG_ EPBR_caliperState m0 : 29|3@1+ (1,0) [0|0] "" Vector__XXX
 SG_ EPBR_filteredCurrentPeak m2 : 28|12@1+ (0.01,0) [0|0] "" Vector__XXX
 SG_ EPBR_pid_duty m1 : 22|10@1- (0.2,0) [0|0] "" Vector__XXX
 SG_ EPBR_pvFilt m0 : 20|9@1+ (0.043549408784,0) [0|0] "" Vector__XXX
 SG_ EPBR_currentOffset m2 : 16|12@1+ (0.016997132,-37.55274262) [0|0] "" Vector__XXX
 SG_ EPBR_driverLockedOut m2 : 15|1@1+ (1,0) [0|0] "" Vector__XXX
 SG_ EPBR_dynamicManagerReady m2 : 14|1@1+ (1,0) [0|0] "" Vector__XXX
 SG_ EPBR_emergencyOperationMode m2 : 12|2@1+ (1,0) [0|0] "" Vector__XXX
 SG_ EPBR_pid_uI m1 : 12|10@1- (0.2,0) [0|0] "" Vector__XXX
 SG_ EPBR_nvFilt m0 : 11|9@1+ (0.043549408784,0) [0|0] "" Vector__XXX
 SG_ EPBR_12VFilt_SW m0 : 2|9@1+ (0.043549408784,0) [0|0] "" Vector__XXX
 SG_ EPBR_limpToDecelTimer m2 : 2|10@1+ (1,0) [0|0] "" Vector__XXX
 SG_ EPBR_pid_uP m1 : 2|10@1- (0.2,0) [0|0] "" Vector__XXX
 SG_ EPBR_debugOutputIndex M : 0|2@1+ (1,0) [0|0] "" Vector__XXX

BO_ 1973 PM_itpmsDisplay: 3 Vector__XXX
 SG_ PM_indirectTPMSDisplayWarningIndicatorRR m0 : 20|2@1+ (1,0) [0|0] "" Vector__XXX
 SG_ PM_indirectTPMSDisplayWarningIndicatorRL m0 : 18|2@1+ (1,0) [0|0] "" Vector__XXX
 SG_ PM_indirectTPMSDisplayWarningIndicatorFR m0 : 16|2@1+ (1,0) [0|0] "" Vector__XXX
 SG_ PM_indirectTPMSRecommendedColdPressureRear m1 : 16|8@1+ (0.025,0) [0|0] "" Vector__XXX
 SG_ PM_indirectTPMSDisplayWarningIndicatorFL m0 : 13|2@1+ (1,0) [0|0] "" Vector__XXX
 SG_ PM_fusedPressureEstimateFrR m2 : 11|9@1+ (0.008,0) [0|0] "" Vector__XXX
 SG_ PM_fusedPressureEstimateReR m3 : 11|9@1+ (0.008,0) [0|0] "" Vector__XXX
 SG_ PM_indirectTPMSDisplayProgress m0 : 8|5@1+ (0.05,0) [0|0] "" Vector__XXX
 SG_ PM_indirectTPMSRecommendedColdPressureFront m1 : 8|8@1+ (0.025,0) [0|0] "" Vector__XXX
 SG_ PM_indirectTPMSDisplayState m0 : 4|2@1+ (1,0) [0|0] "" Vector__XXX
 SG_ PM_fusedPressureEstimateFrL m2 : 2|9@1+ (0.008,0) [0|0] "" Vector__XXX
 SG_ PM_fusedPressureEstimateReL m3 : 2|9@1+ (0.008,0) [0|0] "" Vector__XXX
 SG_ PM_indirectTPMSTellTale m0 : 2|2@1+ (1,0) [0|0] "" Vector__XXX
 SG_ PM_itpmsDisplaySelector M : 0|2@1+ (1,0) [0|0] "" Vector__XXX

BO_ 1976 EPBR_remoteADC: 8 Vector__XXX
 SG_ EPBR_remoteADCChecksum : 56|8@1+ (1,0) [0|0] "" Vector__XXX
 SG_ EPBR_remoteADCCounter : 52|4@1+ (1,0) [0|0] "" Vector__XXX
 SG_ EPBR_2rSeatInboardFloorSensor m5 : 34|10@1+ (0.004887585532746823,0) [0|0] "" Vector__XXX
 SG_ EPBR_PCBATemp m2 : 34|10@1+ (0.0009775171065493646,0) [0|0] "" Vector__XXX
 SG_ EPBR_gloveBoxReleaseMonitor m1 : 34|10@1+ (0.017595307917888565,0) [0|0] "" Vector__XXX
 SG_ EPBR_hvacLeftLowerVentDuctTemp m3 : 34|10@1+ (0.0009775171065493646,0) [0|0] "" Vector__XXX
 SG_ EPBR_premiumAmpCurrent m4 : 34|10@1+ (0.029296875,0) [0|0] "" Vector__XXX
 SG_ EPBR_seatFrontTiltUpMonitor m0 : 34|10@1+ (0.017595307917888565,0) [0|0] "" Vector__XXX
 SG_ EPBR_2rSeatOutboardFloorSensor m5 : 24|10@1+ (0.004887585532746823,0) [0|0] "" Vector__XXX
 SG_ EPBR_ecallStandbyPowerMonitor m2 : 24|10@1+ (0.02932551319648094,0) [0|0] "" Vector__XXX
 SG_ EPBR_gloveBoxLatchUpstreamI m4 : 24|10@1+ (0.019550342130987292,0) [0|0] "" Vector__XXX
 SG_ EPBR_hvacRightLowerVentDuctTemp m3 : 24|10@1+ (0.0009775171065493646,0) [0|0] "" Vector__XXX
 SG_ EPBR_seatFrontLiftUpMonitor m0 : 24|10@1+ (0.017595307917888565,0) [0|0] "" Vector__XXX
 SG_ EPBR_seatFrontTrackForwardMonitor m1 : 24|10@1+ (0.017595307917888565,0) [0|0] "" Vector__XXX
 SG_ EPBR_efuseNonContinuousMonitor m1 : 13|10@1+ (0.017595307917888565,0) [0|0] "" Vector__XXX
 SG_ EPBR_frontCushionTemp m5 : 13|10@1+ (0.0009775171065493646,0) [0|0] "" Vector__XXX
 SG_ EPBR_hvContactorsMonitor m4 : 13|10@1+ (0.017595307917888565,0) [0|0] "" Vector__XXX
 SG_ EPBR_hvacLeftVentDuctTemp m3 : 13|10@1+ (0.0009775171065493646,0) [0|0] "" Vector__XXX
 SG_ EPBR_seatFrontBackRestUpMonitor m2 : 13|10@1+ (0.017595307917888565,0) [0|0] "" Vector__XXX
 SG_ EPBR_windowLiftRearUpMonitor m0 : 13|10@1+ (0.017595307917888565,0) [0|0] "" Vector__XXX
 SG_ EPBR_BLEBPillarMonitor m4 : 3|10@1+ (0.017595307917888565,0) [0|0] "" Vector__XXX
 SG_ EPBR_efuseContinousMonitor m1 : 3|10@1+ (0.017595307917888565,0) [0|0] "" Vector__XXX
 SG_ EPBR_hvacRightVentDuctTemp m3 : 3|10@1+ (0.0009775171065493646,0) [0|0] "" Vector__XXX
 SG_ EPBR_mirrorDimMonitor m2 : 3|10@1+ (0.004887585532746823,0) [0|0] "" Vector__XXX
 SG_ EPBR_rearGlassHeaterCurrent m5 : 3|10@1+ (0.068359375,0) [0|0] "" Vector__XXX
 SG_ EPBR_windowLiftFrontDownMonitor m0 : 3|10@1+ (0.017595307917888565,0) [0|0] "" Vector__XXX
 SG_ EPBR_remoteADCIndex M : 0|3@1+ (1,0) [0|0] "" Vector__XXX

BO_ 1981 V2G_vehLogData: 8 Vector__XXX
 SG_ V2G_chgParamReq_evReady m7 : 60|1@1+ (1,0) [0|0] "" Vector__XXX
 SG_ V2G_chgParamReq_evStatusCode m7 : 56|4@1+ (1,0) [0|0] "" Vector__XXX
 SG_ V2G_currentDemReq_maxPowerLim m11 : 50|10@1+ (1.494138,0) [0|0] "" Vector__XXX
 SG_ V2G_chgParamReq_maxPowerLim m7 : 40|13@1+ (0.1867675781,0) [0|0] "" Vector__XXX
 SG_ V2G_currentDemReq_maxVoltageLim m11 : 40|10@1+ (1.171875,0) [0|0] "" Vector__XXX
 SG_ V2G_currentDemReq_maxCurrentLim m11 : 29|10@1+ (1.7578125,0) [0|0] "" Vector__XXX
 SG_ V2G_chgParamReq_maxVoltageLim m7 : 24|13@1+ (0.146484375,0) [0|0] "" Vector__XXX
 SG_ V2G_currentDemReq_targetV m11 : 16|13@1+ (0.146484375,0) [0|0] "" Vector__XXX
 SG_ V2G_chgParamReq_maxCurrentLim m7 : 8|13@1+ (0.2197265625,0) [0|0] "" Vector__XXX
 SG_ V2G_prechargeReq_targetV m9 : 8|13@1+ (0.146484375,0) [0|0] "" Vector__XXX
 SG_ V2G_powerDelEndReq_evStatusCode m13 : 6|1@1+ (1,0) [0|0] "" Vector__XXX
 SG_ V2G_cableCheckReq_sent m8 : 5|1@1+ (1,0) [0|0] "" Vector__XXX
 SG_ V2G_chargingStatusReq_sent m12 : 5|1@1+ (1,0) [0|0] "" Vector__XXX
 SG_ V2G_contractAuthReq_sent m6 : 5|1@1+ (1,0) [0|0] "" Vector__XXX
 SG_ V2G_currentDemReq_targetI m11 : 5|10@1+ (1.7578125,0) [0|0] "" Vector__XXX
 SG_ V2G_paymentDetailsReq_sent m5 : 5|1@1+ (1,0) [0|0] "" Vector__XXX
 SG_ V2G_powerDeliveryEndReq_sent m13 : 5|1@1+ (1,0) [0|0] "" Vector__XXX
 SG_ V2G_powerDeliveryStartReq_sent m10 : 5|1@1+ (1,0) [0|0] "" Vector__XXX
 SG_ V2G_serviceDetailReq_sent m3 : 5|1@1+ (1,0) [0|0] "" Vector__XXX
 SG_ V2G_serviceDiscoveryReq_sent m2 : 5|1@1+ (1,0) [0|0] "" Vector__XXX
 SG_ V2G_servicePaymentSelReq_sent m4 : 5|1@1+ (1,0) [0|0] "" Vector__XXX
 SG_ V2G_sessionSetupReq_sent m1 : 5|1@1+ (1,0) [0|0] "" Vector__XXX
 SG_ V2G_sessionStopReq_sent m14 : 5|1@1+ (1,0) [0|0] "" Vector__XXX
 SG_ V2G_suppAppProtocolReq_sent m0 : 5|1@1+ (1,0) [0|0] "" Vector__XXX
 SG_ V2G_vehLogDataSelect M : 0|5@1+ (1,0) [0|0] "" Vector__XXX

BO_ 1983 PLC_teslaV2gLog: 1 Vector__XXX
 SG_ TeslaV2G_protoMsgReceived : 4|1@1+ (1,0) [0|0] "" Vector__XXX
 SG_ TeslaV2G_evseChargeStatus : 1|3@1+ (1,0) [0|0] "" Vector__XXX
 SG_ TeslaV2G_cableButtonPressed : 0|1@1+ (1,0) [0|0] "" Vector__XXX

BO_ 1992 EPBL_info: 8 Vector__XXX
 SG_ EPBL_infoComponentId m10 : 48|16@1+ (1,0) [0|0] "" Vector__XXX
 SG_ EPBL_infoSubUsageId m11 : 40|16@1+ (1,0) [0|0] "" Vector__XXX
 SG_ EPBL_infoHardwareId m10 : 32|16@1+ (1,0) [0|0] "" Vector__XXX
 SG_ EPBL_infoBootCrc m20 : 24|32@1+ (1,0) [0|0] "" Vector__XXX
 SG_ EPBL_infoUsageId m11 : 24|16@1+ (1,0) [0|0] "" Vector__XXX
 SG_ EPBL_infoAssemblyId m11 : 16|8@1+ (1,0) [0|0] "" Vector__XXX
 SG_ EPBL_infoBuildConfigId m10 : 16|16@1+ (1,0) [0|0] "" Vector__XXX
 SG_ EPBL_infoAppCrc m13 : 8|32@1+ (1,0) [0|0] "" Vector__XXX
 SG_ EPBL_infoAppGitHash m17 : 8|56@1+ (1,0) [0|0] "" Vector__XXX
 SG_ EPBL_infoBootGitHash m18 : 8|56@1+ (1,0) [0|0] "" Vector__XXX
 SG_ EPBL_infoBootUdsProtoVersion m20 : 8|16@1+ (1,0) [0|0] "" Vector__XXX
 SG_ EPBL_infoBuildType m10 : 8|3@1+ (1,0) [0|0] "" Vector__XXX
 SG_ EPBL_infoPcbaId m11 : 8|8@1+ (1,0) [0|0] "" Vector__XXX
 SG_ EPBL_infoPlatformType m19 : 8|8@1+ (1,0) [0|0] "" Vector__XXX
 SG_ EPBL_infoIndex M : 0|8@1+ (1,0) [0|0] "" Vector__XXX

BO_ 2004 PMR_debug: 8 Vector__XXX
 SG_ PMR_resolverDiMIA m17 : 57|1@1+ (1,0) [0|0] "" Vector__XXX
 SG_ PMR_cpu100HzMin m64 : 56|8@1+ (0.4,0) [0|0] "" Vector__XXX
 SG_ PMR_cpu10kHzMax m65 : 56|8@1+ (0.4,0) [0|0] "" Vector__XXX
 SG_ PMR_lmSatCoeff m3 : 56|8@1+ (0.00391,0) [0|0] "" Vector__XXX
 SG_ PMR_resolverClaMIA m17 : 56|1@1+ (1,0) [0|0] "" Vector__XXX
 SG_ PMR_statorT m4 : 56|8@1+ (1,-40) [0|0] "" Vector__XXX
 SG_ PMR_resolverPhaseOutOfSpec m17 : 55|1@1+ (1,0) [0|0] "" Vector__XXX
 SG_ PMR_resolverNoCarrier m17 : 54|1@1+ (1,0) [0|0] "" Vector__XXX
 SG_ PMR_cpu1kHzAvg m64 : 48|8@1+ (0.4,0) [0|0] "" Vector__XXX
 SG_ PMR_cpu20kHzMin m65 : 48|8@1+ (0.4,0) [0|0] "" Vector__XXX
 SG_ PMR_resolverOffsetExt m17 : 48|6@1+ (0.053,0) [0|0] "" Vector__XXX
 SG_ PMR_torqueOutOfMap m5 : 47|1@1+ (1,0) [0|0] "" Vector__XXX
 SG_ PMR_switchingActive m5 : 46|1@1+ (1,0) [0|0] "" Vector__XXX
 SG_ PMR_cpu100HzMax m64 : 40|8@1+ (0.4,0) [0|0] "" Vector__XXX
 SG_ PMR_cpu20kHzMax m65 : 40|8@1+ (0.4,0) [0|0] "" Vector__XXX
 SG_ PMR_iDQmagnitude m3 : 40|16@1- (0.0939,0) [0|0] "" Vector__XXX
 SG_ PMR_motorRPM m4 : 40|16@1- (1,0) [0|0] "" Vector__XXX
 SG_ PMR_resolverOffsetSin m17 : 40|6@1+ (0.053,0) [0|0] "" Vector__XXX
 SG_ PMR_torqueAccelAvg m1 : 40|13@1- (2,0) [0|0] "" Vector__XXX
 SG_ PMR_torqueReversalWindow m2 : 40|13@1- (2,0) [0|0] "" Vector__XXX
 SG_ PMR_cpu10HzMin m65 : 32|8@1+ (0.4,0) [0|0] "" Vector__XXX
 SG_ PMR_cpu10kHzAvg m64 : 32|8@1+ (0.4,0) [0|0] "" Vector__XXX
 SG_ PMR_resolverOffsetCos m17 : 32|6@1+ (0.053,0) [0|0] "" Vector__XXX
 SG_ PMR_Ib m3 : 24|16@1- (0.0939,0) [0|0] "" Vector__XXX
 SG_ PMR_cpu10HzAvg m65 : 24|8@1+ (0.4,0) [0|0] "" Vector__XXX
 SG_ PMR_cpu1kHzMin m64 : 24|8@1+ (0.4,0) [0|0] "" Vector__XXX
 SG_ PMR_idleStackMax m67 : 24|16@1+ (1,0) [0|0] "" Vector__XXX
 SG_ PMR_resolverExcitationGain m17 : 24|7@1+ (0.063,0) [0|0] "" Vector__XXX
 SG_ PMR_sysStackMax m70 : 24|16@1+ (1,0) [0|0] "" Vector__XXX
 SG_ PMR_torqueAccelWindow m1 : 24|13@1- (2,0) [0|0] "" Vector__XXX
 SG_ PMR_torqueDecelAvg m2 : 24|13@1- (2,0) [0|0] "" Vector__XXX
 SG_ PMR_udsStackMax m68 : 24|16@1+ (1,0) [0|0] "" Vector__XXX
 SG_ PMR_xcpStackMax m69 : 24|16@1+ (1,0) [0|0] "" Vector__XXX
 SG_ PMR_offsetIb m5 : 20|12@1- (0.1,0) [0|0] "" Vector__XXX
 SG_ PMR_resolverCommonGain m17 : 17|7@1+ (0.063,0) [0|0] "" Vector__XXX
 SG_ PMR_cpu10HzMax m65 : 16|8@1+ (0.4,0) [0|0] "" Vector__XXX
 SG_ PMR_cpu20kHzAvg m64 : 16|8@1+ (0.4,0) [0|0] "" Vector__XXX
 SG_ PMR_Ia m3 : 8|16@1- (0.0939,0) [0|0] "" Vector__XXX
 SG_ PMR_cpu100HzAvg m65 : 8|8@1+ (0.4,0) [0|0] "" Vector__XXX
 SG_ PMR_cpu10kHzMin m66 : 8|8@1+ (0.4,0) [0|0] "" Vector__XXX
 SG_ PMR_cpu1kHzMax m64 : 8|8@1+ (0.4,0) [0|0] "" Vector__XXX
 SG_ PMR_idleStackSize m67 : 8|16@1+ (1,0) [0|0] "" Vector__XXX
 SG_ PMR_offsetIa m5 : 8|12@1- (0.1,0) [0|0] "" Vector__XXX
 SG_ PMR_resolverPhaseAngle m17 : 8|9@1+ (0.001537,0) [0|0] "" Vector__XXX
 SG_ PMR_resolverSpeedError m16 : 8|16@1- (0.75,0) [0|0] "" Vector__XXX
 SG_ PMR_slipFrequency m4 : 8|16@1- (0.005,0) [0|0] "" Vector__XXX
 SG_ PMR_sysStackSize m70 : 8|16@1+ (1,0) [0|0] "" Vector__XXX
 SG_ PMR_torqueDecelWindow m2 : 8|13@1- (2,0) [0|0] "" Vector__XXX
 SG_ PMR_torqueSignError m1 : 8|13@1- (2,0) [0|0] "" Vector__XXX
 SG_ PMR_udsStackSize m68 : 8|16@1+ (1,0) [0|0] "" Vector__XXX
 SG_ PMR_xcpStackSize m69 : 8|16@1+ (1,0) [0|0] "" Vector__XXX
 SG_ PMR_debugSelector M : 0|8@1+ (1,0) [0|0] "" Vector__XXX

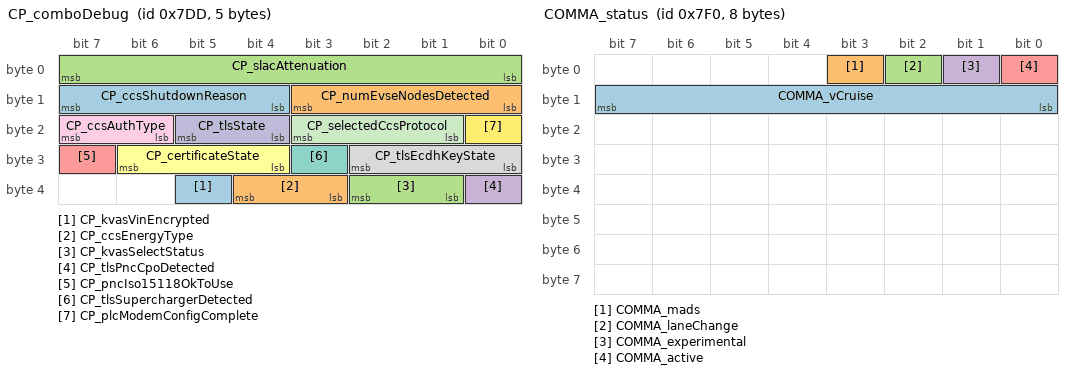
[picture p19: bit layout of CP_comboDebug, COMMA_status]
BO_ 2013 CP_comboDebug: 5 Vector__XXX
 SG_ CP_kvasVinEncrypted : 37|1@1+ (1,0) [0|0] "" Vector__XXX
 SG_ CP_ccsEnergyType : 35|2@1+ (1,0) [0|0] "" Vector__XXX
 SG_ CP_kvasSelectStatus : 33|2@1+ (1,0) [0|0] "" Vector__XXX
 SG_ CP_tlsPncCpoDetected : 32|1@1+ (1,0) [0|0] "" Vector__XXX
 SG_ CP_pncIso15118OkToUse : 31|1@1+ (1,0) [0|0] "" Vector__XXX
 SG_ CP_certificateState : 28|3@1+ (1,0) [0|0] "" Vector__XXX
 SG_ CP_tlsSuperchargerDetected : 27|1@1+ (1,0) [0|0] "" Vector__XXX
 SG_ CP_tlsEcdhKeyState : 24|3@1+ (1,0) [0|0] "" Vector__XXX
 SG_ CP_ccsAuthType : 22|2@1+ (1,0) [0|0] "" Vector__XXX
 SG_ CP_tlsState : 20|2@1+ (1,0) [0|0] "" Vector__XXX
 SG_ CP_selectedCcsProtocol : 17|3@1+ (1,0) [0|0] "" Vector__XXX
 SG_ CP_plcModemConfigComplete : 16|1@1+ (1,0) [0|0] "" Vector__XXX
 SG_ CP_ccsShutdownReason : 12|4@1+ (1,0) [0|0] "" Vector__XXX
 SG_ CP_numEvseNodesDetected : 8|4@1+ (1,0) [0|0] "" Vector__XXX
 SG_ CP_slacAttenuation : 0|8@1+ (1,0) [0|0] "" Vector__XXX

BO_ 2024 EPBR_info: 8 Vector__XXX
 SG_ EPBR_infoComponentId m10 : 48|16@1+ (1,0) [0|0] "" Vector__XXX
 SG_ EPBR_infoSubUsageId m11 : 40|16@1+ (1,0) [0|0] "" Vector__XXX
 SG_ EPBR_infoHardwareId m10 : 32|16@1+ (1,0) [0|0] "" Vector__XXX
 SG_ EPBR_infoBootCrc m20 : 24|32@1+ (1,0) [0|0] "" Vector__XXX
 SG_ EPBR_infoUsageId m11 : 24|16@1+ (1,0) [0|0] "" Vector__XXX
 SG_ EPBR_infoAssemblyId m11 : 16|8@1+ (1,0) [0|0] "" Vector__XXX
 SG_ EPBR_infoBuildConfigId m10 : 16|16@1+ (1,0) [0|0] "" Vector__XXX
 SG_ EPBR_infoAppCrc m13 : 8|32@1+ (1,0) [0|0] "" Vector__XXX
 SG_ EPBR_infoAppGitHash m17 : 8|56@1+ (1,0) [0|0] "" Vector__XXX
 SG_ EPBR_infoBootGitHash m18 : 8|56@1+ (1,0) [0|0] "" Vector__XXX
 SG_ EPBR_infoBootUdsProtoVersion m20 : 8|16@1+ (1,0) [0|0] "" Vector__XXX
 SG_ EPBR_infoBuildType m10 : 8|3@1+ (1,0) [0|0] "" Vector__XXX
 SG_ EPBR_infoPcbaId m11 : 8|8@1+ (1,0) [0|0] "" Vector__XXX
 SG_ EPBR_infoPlatformType m19 : 8|8@1+ (1,0) [0|0] "" Vector__XXX
 SG_ EPBR_infoIndex M : 0|8@1+ (1,0) [0|0] "" Vector__XXX

BO_ 2032 COMMA_status: 8 X
 SG_ COMMA_vCruise : 8|8@1+ (1,0) [0|255] "kph"  X
 SG_ COMMA_mads : 3|1@1+ (1,0) [0|1] ""  X
 SG_ COMMA_laneChange : 2|1@1+ (1,0) [0|1] ""  X
 SG_ COMMA_experimental : 1|1@1+ (1,0) [0|1] ""  X
 SG_ COMMA_active : 0|1@1+ (1,0) [0|1] ""  X

BO_ 2036 GTW_canLogAvailability: 1 Vector__XXX
 SG_ GTW_canLogServiceAvailability : 0|2@1+ (1,0) [0|0] "" Vector__XXX

CM_ BO_ 989 "ESP32-DualCAN Model3_VEH. Seen on this car: 8-byte frames; fit good (bits covered 100%, mux 91%, ranges 100%).";
CM_ BO_ 991 "ESP32-DualCAN Model3_VEH. Seen on this car: 8-byte frames; fit good (bits covered 100%, mux 100%, ranges 100%). read by the app or firmware.";
CM_ BO_ 994 "ESP32-DualCAN Model3_VEH. Seen on this car: 8-byte frames; fit good (bits covered 86%, mux 100%, ranges 100%). read by the app or firmware.";
CM_ BO_ 995 "ESP32-DualCAN Model3_VEH. Seen on this car: 5-byte frames; fit ok (bits covered 100%, mux 100%, ranges 100%). read by the app or firmware.";
CM_ BO_ 1001 "ESP32-DualCAN Model3_VEH. Seen on this car: 8-byte frames; fit good (bits covered 100%, mux 100%, ranges 100%, checksum 100%). read by the app or firmware.";
CM_ BO_ 1005 "ESP32-DualCAN Model3_VEH. Seen on this car: 1-byte frames; fit poor (bits covered 0%, mux 100%, ranges 100%).";
CM_ BO_ 1010 "ESP32-DualCAN Model3_VEH. Seen on this car: 8-byte frames; fit good (bits covered 100%, mux 100%, ranges 100%).";
CM_ BO_ 1013 "ESP32-DualCAN Model3_VEH. Seen on this car: 8-byte frames; fit good (bits covered 100%, mux 100%, ranges 100%).";
CM_ BO_ 1014 "ESP32-DualCAN Model3_VEH. Seen on this car: 8-byte frames; fit good (bits covered 100%, mux 100%, ranges 100%).";
CM_ BO_ 1018 "DashKit DBC. Seen on this car: 8-byte frames; fit good (bits covered 100%, mux 100%, ranges 100%).";
CM_ BO_ 1022 "ESP32-DualCAN Model3_VEH. Seen on this car: 8-byte frames; fit good (bits covered 100%, mux 100%, ranges 100%, checksum 100%).";
CM_ BO_ 1024 "ESP32-DualCAN Model3_VEH. Seen on this car: 7-byte frames; fit ok (bits covered 100%, mux 100%, ranges 100%).";
CM_ BO_ 1029 "ESP32-DualCAN Model3_VEH. Seen on this car: 8-byte frames; fit ok (bits covered 100%, mux 100%, ranges 100%).";
CM_ BO_ 1031 "ESP32-DualCAN Model3_VEH. Seen on this car: 8-byte frames; fit good (bits covered 100%, mux 100%, ranges 100%, checksum 100%).";
CM_ BO_ 1033 "ESP32-DualCAN Model3_VEH. Seen on this car: 1-byte frames; fit ok (bits covered 100%, mux 100%, ranges 100%).";
CM_ BO_ 1034 "ESP32-DualCAN Model3_VEH. Seen on this car: 8-byte frames; fit good (bits covered 100%, mux 100%, ranges 100%, checksum 100%).";
CM_ BO_ 1044 "ESP32-DualCAN Model3_VEH. Seen on this car: 8-byte frames; fit ok (bits covered 100%, mux 100%, ranges 100%).";
CM_ BO_ 1049 "ESP32-DualCAN Model3_VEH. Seen on this car: 1-byte frames; fit ok (bits covered 100%, mux 100%, ranges 100%).";
CM_ BO_ 1053 "ESP32-DualCAN Model3_VEH. Seen on this car: 2-byte frames; fit ok (bits covered 100%, mux 100%, ranges 100%).";
CM_ BO_ 1056 "ESP32-DualCAN Model3_VEH. Seen on this car: 8-byte frames; fit good (bits covered 100%, mux 100%, ranges 100%).";
CM_ BO_ 1057 "ESP32-DualCAN Model3_VEH. Seen on this car: 7-byte frames; fit ok (bits covered 100%, mux 100%, ranges 100%).";
CM_ BO_ 1058 "ESP32-DualCAN Model3_VEH. Seen on this car: 6-byte frames; fit ok (bits covered 100%, mux 100%, ranges 100%).";
CM_ BO_ 1059 "ESP32-DualCAN Model3_VEH. Seen on this car: 7-byte frames; fit ok (bits covered 100%, mux 100%, ranges 100%).";
CM_ BO_ 1064 "ESP32-DualCAN Model3_VEH. Seen on this car: 7-byte frames; fit ok (bits covered 100%, mux 100%, ranges 100%).";
CM_ BO_ 1066 "ESP32-DualCAN Model3_VEH. Seen on this car: 8-byte frames; fit good (bits covered 100%, mux 100%, ranges 100%).";
CM_ BO_ 1070 "ESP32-DualCAN Model3_VEH. Seen on this car: 8-byte frames; fit weak (bits covered 0%, mux 100%, ranges 100%).";
CM_ BO_ 1071 "ESP32-DualCAN Model3_VEH. Seen on this car: 7-byte frames; fit ok (bits covered 96%, mux 100%, ranges 100%).";
CM_ BO_ 1081 "ESP32-DualCAN Model3_VEH. Seen on this car: 8-byte frames; fit good (bits covered 100%, mux 100%, ranges 100%).";
CM_ BO_ 1082 "ESP32-DualCAN Model3_VEH. Seen on this car: 6-byte frames; fit ok (bits covered 100%, mux 100%, ranges 100%).";
CM_ BO_ 1083 "ESP32-DualCAN Model3_VEH. Seen on this car: 8-byte frames; fit good (bits covered 100%, mux 100%, ranges 100%).";
CM_ BO_ 1089 "ESP32-DualCAN Model3_VEH. Seen on this car: 8-byte frames; fit ok (bits covered 100%, mux 100%, ranges 100%, checksum 0%).";
CM_ BO_ 1091 "ESP32-DualCAN Model3_VEH. Seen on this car: 6-byte frames; fit weak (bits covered 100%, mux 100%, ranges 100%, checksum 0%).";
CM_ BO_ 1096 "ESP32-DualCAN Model3_VEH. Seen on this car: 7-byte frames; fit ok (bits covered 100%, mux 100%, ranges 100%).";
CM_ BO_ 1106 "ESP32-DualCAN Model3_VEH. Seen on this car: 3-byte frames; fit ok (bits covered 100%, mux 100%, ranges 100%).";
CM_ BO_ 1107 "ESP32-DualCAN Model3_VEH. Seen on this car: 4-byte frames; fit ok (bits covered 100%, mux 100%, ranges 100%).";
CM_ BO_ 1112 "DashKit DBC. Seen on this car: 7-byte frames; fit weak (bits covered 0%, mux 100%, ranges 100%).";
CM_ BO_ 1114 "ESP32-DualCAN Model3_VEH. Seen on this car: 8-byte frames; fit good (bits covered 100%, mux 100%, ranges 100%).";
CM_ BO_ 1115 "ESP32-DualCAN Model3_VEH. Seen on this car: 2-byte frames; fit poor (bits covered 0%, mux 100%, ranges 100%).";
CM_ BO_ 1138 "ESP32-DualCAN Model3_VEH. Seen on this car: 8-byte frames; fit good (bits covered 100%, mux 100%, ranges 100%).";
CM_ BO_ 1139 "ESP32-DualCAN Model3_VEH. Seen on this car: 8-byte frames; fit good (bits covered 100%, mux 100%, ranges 100%).";
CM_ BO_ 1153 "ESP32-DualCAN Model3_VEH. Seen on this car: 8-byte frames; fit ok (bits covered 100%, mux 100%, ranges 100%).";
CM_ BO_ 1154 "ESP32-DualCAN Model3_VEH. Seen on this car: 8-byte frames; fit ok (bits covered 100%, mux 100%, ranges 100%).";
CM_ BO_ 1170 "ESP32-DualCAN Model3_VEH. Seen on this car: 7-byte frames; fit ok (bits covered 100%, mux 100%, ranges 100%).";
CM_ BO_ 1181 "ESP32-DualCAN Model3_VEH. Seen on this car: 7-byte frames; fit ok (bits covered 100%, mux 100%, ranges 100%).";
CM_ BO_ 1250 "ESP32-DualCAN Model3_VEH. Seen on this car: 8-byte frames; fit good (bits covered 100%, mux 100%, ranges 100%).";
CM_ BO_ 1251 "ESP32-DualCAN Model3_VEH. Seen on this car: 8-byte frames; fit good (bits covered 100%, mux 100%, ranges 100%).";
CM_ BO_ 1267 "ESP32-DualCAN Model3_VEH. Seen on this car: 4-byte frames; fit poor (bits covered 0%, mux 100%, ranges 100%).";
CM_ BO_ 1279 "ESP32-DualCAN Model3_VEH. Seen on this car: 8-byte frames; fit weak (bits covered 0%, mux 100%, ranges 100%).";
CM_ BO_ 1289 "ESP32-DualCAN Model3_VEH. Seen on this car: 5-byte frames; fit poor (bits covered 0%, mux 100%, ranges 100%).";
CM_ BO_ 1303 "ESP32-DualCAN Model3_VEH. Seen on this car: 8-byte frames; fit good (bits covered 100%, mux 100%, ranges 100%).";
CM_ BO_ 1304 "ESP32-DualCAN Model3_VEH. Seen on this car: 2-byte frames; fit weak (bits covered 60%, mux 100%, ranges 100%).";
CM_ BO_ 1310 "ESP32-DualCAN Model3_VEH. Seen on this car: 8-byte frames; fit good (bits covered 100%, mux 100%, ranges 100%).";
CM_ BO_ 1314 "ESP32-DualCAN Model3_VEH. Seen on this car: 2-byte frames; fit weak (bits covered 67%, mux 100%, ranges 100%).";
CM_ BO_ 1320 "ESP32-DualCAN Model3_VEH. Seen on this car: 4-byte frames; fit ok (bits covered 100%, mux 100%, ranges 100%).";
CM_ BO_ 1321 "ESP32-DualCAN Model3_VEH. Seen on this car: 8-byte frames; fit weak (bits covered 0%, mux 100%, ranges 100%).";
CM_ BO_ 1327 "ESP32-DualCAN Model3_VEH. Seen on this car: 8-byte frames; fit ok (bits covered 100%, mux 100%, ranges 100%).";
CM_ BO_ 1342 "ESP32-DualCAN Model3_VEH. Seen on this car: 8-byte frames; fit good (bits covered 100%, mux 100%, ranges 100%).";
CM_ BO_ 1345 "ESP32-DualCAN Model3_VEH. Seen on this car: 8-byte frames; fit good (bits covered 100%, mux 100%, ranges 100%).";
CM_ BO_ 1349 "ESP32-DualCAN Model3_VEH. Seen on this car: 8-byte frames; fit good (bits covered 100%, mux 100%, ranges 100%, checksum 100%).";
CM_ BO_ 1353 "ESP32-DualCAN Model3_VEH. Seen on this car: 6-byte frames; fit poor (bits covered 0%, mux 100%, ranges 100%).";
CM_ BO_ 1359 "ESP32-DualCAN Model3_VEH. Seen on this car: 8-byte frames; fit weak (bits covered 0%, mux 100%, ranges 100%).";
CM_ BO_ 1362 "ESP32-DualCAN Model3_VEH. Seen on this car: 8-byte frames; fit good (bits covered 100%, mux 100%, ranges 100%, checksum 100%).";
CM_ BO_ 1363 "ESP32-DualCAN Model3_VEH. Seen on this car: 8-byte frames; fit good (bits covered 100%, mux 100%, ranges 100%, checksum 100%).";
CM_ BO_ 1364 "ESP32-DualCAN Model3_VEH. Seen on this car: 7-byte frames; fit poor (bits covered 0%, mux 100%, ranges 100%).";
CM_ BO_ 1495 "ESP32-DualCAN Model3_VEH. Seen on this car: 5-byte frames; fit ok (bits covered 100%, mux 100%, ranges 100%).";
CM_ BO_ 1523 "ESP32-DualCAN Model3_VEH. Seen on this car: 3-byte frames; fit ok (bits covered 100%, mux 100%, ranges 100%).";
CM_ BO_ 1524 "ESP32-DualCAN Model3_VEH. Seen on this car: 8-byte frames; fit poor (bits covered 0%, mux 100%, ranges 100%).";
CM_ BO_ 1536 "ESP32-DualCAN Model3_VEH. Seen on this car: 8-byte frames; fit ok (bits covered 100%, mux 100%, ranges 100%).";
CM_ BO_ 1537 "ESP32-DualCAN Model3_VEH. Seen on this car: 8-byte frames; fit ok (bits covered 100%, mux 100%, ranges 100%).";
CM_ BO_ 1541 "ESP32-DualCAN Model3_VEH. Seen on this car: 8-byte frames; fit poor (bits covered 0%, mux 100%, ranges 100%).";
CM_ BO_ 1542 "ESP32-DualCAN Model3_VEH. Seen on this car: 8-byte frames; fit ok (bits covered 100%, mux 100%, ranges 100%).";
CM_ BO_ 1544 "ESP32-DualCAN Model3_VEH. Seen on this car: 8-byte frames; fit ok (bits covered 100%, mux 100%, ranges 100%).";
CM_ BO_ 1545 "ESP32-DualCAN Model3_VEH. Seen on this car: 8-byte frames; fit ok (bits covered 100%, mux 100%, ranges 100%).";
CM_ BO_ 1546 "ESP32-DualCAN Model3_VEH. Seen on this car: 8-byte frames; fit ok (bits covered 100%, mux 100%, ranges 100%).";
CM_ BO_ 1547 "ESP32-DualCAN Model3_VEH. Seen on this car: 8-byte frames; fit ok (bits covered 100%, mux 100%, ranges 100%).";
CM_ BO_ 1550 "ESP32-DualCAN Model3_VEH. Seen on this car: 8-byte frames; fit ok (bits covered 100%, mux 100%, ranges 100%).";
CM_ BO_ 1558 "ESP32-DualCAN Model3_VEH. Seen on this car: 8-byte frames; fit ok (bits covered 100%, mux 100%, ranges 100%).";
CM_ BO_ 1565 "ESP32-DualCAN Model3_VEH. Seen on this car: 8-byte frames; fit ok (bits covered 82%, mux 100%, ranges 100%).";
CM_ BO_ 1566 "ESP32-DualCAN Model3_VEH. Seen on this car: 8-byte frames; fit ok (bits covered 100%, mux 100%, ranges 100%).";
CM_ BO_ 1570 "ESP32-DualCAN Model3_VEH. Seen on this car: 8-byte frames; fit ok (bits covered 100%, mux 100%, ranges 100%).";
CM_ BO_ 1571 "ESP32-DualCAN Model3_VEH. Seen on this car: 8-byte frames; fit ok (bits covered 100%, mux 100%, ranges 100%).";
CM_ BO_ 1572 "ESP32-DualCAN Model3_VEH. Seen on this car: 8-byte frames; fit ok (bits covered 100%, mux 100%, ranges 100%).";
CM_ BO_ 1573 "ESP32-DualCAN Model3_VEH. Seen on this car: 8-byte frames; fit ok (bits covered 100%, mux 100%, ranges 100%).";
CM_ BO_ 1574 "ESP32-DualCAN Model3_VEH. Seen on this car: 8-byte frames; fit ok (bits covered 100%, mux 100%, ranges 100%).";
CM_ BO_ 1575 "ESP32-DualCAN Model3_VEH. Seen on this car: 8-byte frames; fit ok (bits covered 100%, mux 100%, ranges 100%).";
CM_ BO_ 1576 "ESP32-DualCAN Model3_VEH. Seen on this car: 8-byte frames; fit poor (bits covered 0%, mux 100%, ranges 100%).";
CM_ BO_ 1577 "ESP32-DualCAN Model3_VEH. Seen on this car: 8-byte frames; fit poor (bits covered 0%, mux 100%, ranges 100%).";
CM_ BO_ 1588 "ESP32-DualCAN Model3_VEH. Seen on this car: 8-byte frames; fit poor (bits covered 0%, mux 100%, ranges 100%).";
CM_ BO_ 1617 "ESP32-DualCAN Model3_VEH. Seen on this car: 8-byte frames; fit ok (bits covered 100%, mux 100%, ranges 100%).";
CM_ BO_ 1638 "ESP32-DualCAN Model3_VEH. Seen on this car: 4-byte frames; fit ok (bits covered 100%, mux 100%, ranges 100%).";
CM_ BO_ 1651 "ESP32-DualCAN Model3_VEH. Seen on this car: 8-byte frames; fit good (bits covered 100%, mux 100%, ranges 100%).";
CM_ BO_ 1655 "ESP32-DualCAN Model3_VEH. Seen on this car: 8-byte frames; fit good (bits covered 100%, mux 100%, ranges 100%).";
CM_ BO_ 1662 "ESP32-DualCAN Model3_VEH. Seen on this car: 8-byte frames; fit good (bits covered 100%, mux 100%, ranges 100%).";
CM_ BO_ 1666 "ESP32-DualCAN Model3_VEH. Seen on this car: 8-byte frames; fit ok (bits covered 100%, mux 100%, ranges 100%, checksum 0%).";
CM_ BO_ 1698 "ESP32-DualCAN Model3_VEH. Seen on this car: 4-byte frames; fit poor (bits covered 0%, mux 100%, ranges 100%).; 1 signals past the 4 bytes this car sends were left out";
CM_ BO_ 1723 "ESP32-DualCAN Model3_VEH. Seen on this car: 8-byte frames; fit poor (bits covered 0%, mux 100%, ranges 100%).";
CM_ BO_ 1736 "ESP32-DualCAN Model3_VEH. Seen on this car: 8-byte frames; fit good (bits covered 100%, mux 100%, ranges 100%).";
CM_ BO_ 1748 "ESP32-DualCAN Model3_VEH. Seen on this car: 8-byte frames; fit good (bits covered 100%, mux 100%, ranges 100%).";
CM_ BO_ 1768 "ESP32-DualCAN Model3_VEH. Seen on this car: 8-byte frames; fit good (bits covered 100%, mux 100%, ranges 100%).";
CM_ BO_ 1799 "ESP32-DualCAN Model3_VEH. Seen on this car: 8-byte frames; fit weak (bits covered 0%, mux 100%, ranges 100%).";
CM_ BO_ 1800 "ESP32-DualCAN Model3_VEH. Seen on this car: 5-byte frames; fit ok (bits covered 100%, mux 100%, ranges 100%).";
CM_ BO_ 1802 "ESP32-DualCAN Model3_VEH. Seen on this car: 5-byte frames; fit ok (bits covered 100%, mux 100%, ranges 100%).";
CM_ BO_ 1803 "ESP32-DualCAN Model3_VEH. Seen on this car: 8-byte frames; fit good (bits covered 100%, mux 90%, ranges 100%).";
CM_ BO_ 1810 "ESP32-DualCAN Model3_VEH. Seen on this car: 8-byte frames; fit good (bits covered 100%, mux 100%, ranges 100%).";
CM_ BO_ 1815 "ESP32-DualCAN Model3_VEH. Seen on this car: 7-byte frames; fit ok (bits covered 100%, mux 100%, ranges 100%).";
CM_ BO_ 1816 "ESP32-DualCAN Model3_VEH. Seen on this car: 8-byte frames; fit good (bits covered 90%, mux 100%, ranges 100%).";
CM_ BO_ 1824 "ESP32-DualCAN Model3_VEH. Seen on this car: 5-byte frames; fit poor (bits covered 0%, mux 100%, ranges 100%).";
CM_ BO_ 1828 "ESP32-DualCAN Model3_VEH. Seen on this car: 3-byte frames; fit ok (bits covered 100%, mux 100%, ranges 100%).";
CM_ BO_ 1830 "ESP32-DualCAN Model3_VEH. Seen on this car: 3-byte frames; fit ok (bits covered 100%, mux 100%, ranges 100%).";
CM_ BO_ 1831 "ESP32-DualCAN Model3_VEH. Seen on this car: 2-byte frames; fit ok (bits covered 100%, mux 100%, ranges 100%).";
CM_ BO_ 1834 "ESP32-DualCAN Model3_VEH. Seen on this car: 8-byte frames; fit good (bits covered 100%, mux 100%, ranges 100%).";
CM_ BO_ 1847 "ESP32-DualCAN Model3_VEH. Seen on this car: 7-byte frames; fit ok (bits covered 100%, mux 100%, ranges 100%).";
CM_ BO_ 1849 "ESP32-DualCAN Model3_VEH. Seen on this car: 5-byte frames; fit ok (bits covered 100%, mux 100%, ranges 100%).";
CM_ BO_ 1850 "ESP32-DualCAN Model3_VEH. Seen on this car: 8-byte frames; fit good (bits covered 100%, mux 100%, ranges 100%).";
CM_ BO_ 1858 "ESP32-DualCAN Model3_VEH. Seen on this car: 8-byte frames; fit weak (bits covered 0%, mux 100%, ranges 100%).";
CM_ BO_ 1859 "ESP32-DualCAN Model3_VEH. Seen on this car: 1-byte frames; fit ok (bits covered 100%, mux 100%, ranges 100%).";
CM_ BO_ 1860 "ESP32-DualCAN Model3_VEH. Seen on this car: 1-byte frames; fit ok (bits covered 100%, mux 100%, ranges 100%).";
CM_ BO_ 1864 "ESP32-DualCAN Model3_VEH. Seen on this car: 5-byte frames; fit ok (bits covered 100%, mux 100%, ranges 100%).";
CM_ BO_ 1870 "ESP32-DualCAN Model3_VEH. Seen on this car: 8-byte frames; fit poor (bits covered 0%, mux 100%, ranges 100%).";
CM_ BO_ 1871 "ESP32-DualCAN Model3_VEH. Seen on this car: 8-byte frames; fit poor (bits covered 0%, mux 100%, ranges 100%).";
CM_ BO_ 1885 "ESP32-DualCAN Model3_VEH. Seen on this car: 8-byte frames; fit ok (bits covered 100%, mux 53%, ranges 100%).";
CM_ BO_ 1897 "ESP32-DualCAN Model3_VEH. Seen on this car: 8-byte frames; fit weak (bits covered 0%, mux 100%, ranges 100%).";
CM_ BO_ 1914 "ESP32-DualCAN Model3_VEH. Seen on this car: 8-byte frames; fit good (bits covered 100%, mux 100%, ranges 100%).";
CM_ BO_ 1917 "ESP32-DualCAN Model3_VEH. Seen on this car: 4-byte frames; fit ok (bits covered 100%, mux 100%, ranges 100%).";
CM_ BO_ 1928 "ESP32-DualCAN Model3_VEH. Seen on this car: 8-byte frames; fit good (bits covered 100%, mux 100%, ranges 100%).";
CM_ BO_ 1929 "ESP32-DualCAN Model3_VEH. Seen on this car: 4-byte frames; fit weak (bits covered 100%, mux 100%, ranges 100%, checksum 0%).";
CM_ BO_ 1930 "ESP32-DualCAN Model3_VEH. Seen on this car: 8-byte frames; fit good (bits covered 100%, mux 100%, ranges 100%).";
CM_ BO_ 1943 "ESP32-DualCAN Model3_VEH. Seen on this car: 4-byte frames; fit weak (bits covered 100%, mux 100%, ranges 100%, checksum 0%).";
CM_ BO_ 1944 "ESP32-DualCAN Model3_VEH. Seen on this car: 8-byte frames; fit ok (bits covered 100%, mux 86%, ranges 100%, checksum 0%).";
CM_ BO_ 1949 "ESP32-DualCAN Model3_VEH. Seen on this car: 8-byte frames; fit good (bits covered 100%, mux 100%, ranges 100%).";
CM_ BO_ 1960 "ESP32-DualCAN Model3_VEH. Seen on this car: 8-byte frames; fit good (bits covered 100%, mux 100%, ranges 100%).";
CM_ BO_ 1973 "ESP32-DualCAN Model3_VEH. Seen on this car: 3-byte frames; fit ok (bits covered 100%, mux 100%, ranges 100%).";
CM_ BO_ 1976 "ESP32-DualCAN Model3_VEH. Seen on this car: 8-byte frames; fit ok (bits covered 100%, mux 86%, ranges 100%, checksum 0%).";
CM_ BO_ 1981 "ESP32-DualCAN Model3_VEH. Seen on this car: 8-byte frames; fit good (bits covered 100%, mux 100%, ranges 100%).";
CM_ BO_ 1983 "ESP32-DualCAN Model3_VEH. Seen on this car: 1-byte frames; fit poor (bits covered 0%, mux 100%, ranges 100%).";
CM_ BO_ 1992 "ESP32-DualCAN Model3_VEH. Seen on this car: 8-byte frames; fit good (bits covered 100%, mux 100%, ranges 100%).";
CM_ BO_ 2004 "ESP32-DualCAN Model3_VEH. Seen on this car: 8-byte frames; fit weak (bits covered 0%, mux 100%, ranges 100%).";
CM_ BO_ 2013 "ESP32-DualCAN Model3_VEH. Seen on this car: 5-byte frames; fit ok (bits covered 100%, mux 100%, ranges 100%).";
CM_ BO_ 2024 "ESP32-DualCAN Model3_VEH. Seen on this car: 8-byte frames; fit good (bits covered 100%, mux 100%, ranges 100%).";
CM_ BO_ 2036 "ESP32-DualCAN Model3_VEH. Seen on this car: 1-byte frames; fit poor (bits covered 0%, mux 100%, ranges 100%).";
BA_DEF_ BO_  "GenMsgCycleTime" INT 0 65535;
BA_DEF_DEF_  "GenMsgCycleTime" 0;
BA_ "GenMsgCycleTime" BO_ 1018 500;
BA_ "GenMsgCycleTime" BO_ 1112 100;
VAL_ 989 CP_inletHeaterState 0 "DISABLED" 1 "ENABLED_HIGHTEMP" 2 "ENABLED_LOWTEMP" 3 "FAULTED" ;
VAL_ 989 CP_inlet2HarnessIdState 0 "UNKNOWN_SNA" 1 "INVALID" 2 "VALID" ;
VAL_ 989 CP_inlet1HarnessIdState 0 "UNKNOWN_SNA" 1 "INVALID" 2 "VALID" ;
VAL_ 989 CP_loggingSlowSelect 0 "0" 1 "1" 2 "2" 3 "3" 4 "4" 5 "5" ;
VAL_ 991 UI_sentryModeState 0 "OFF" 1 "IDLE" 2 "ARMED" 3 "AWARE" 4 "PANIC" 5 "QUIET" 6 "SNA" ;
VAL_ 991 UI_linkState 0 "NONE" 1 "CELL" 2 "WIFI" ;
VAL_ 994 VCLEFT_reverseTrailerLightStatus 0 "OFF" 1 "ON" 2 "FAULT" 3 "SNA" ;
VAL_ 994 VCLEFT_trailerDetected 0 "SNA" 1 "FAULT" 2 "DETECTED" 3 "NOT_DETECTED" ;
VAL_ 994 VCLEFT_rearRideHeight 4294967168 "SNA" ;
VAL_ 994 VCLEFT_frontRideHeight 4294967168 "SNA" ;
VAL_ 994 VCLEFT_fogTrailerLightStatus 0 "OFF" 1 "ON" 2 "FAULT" 3 "SNA" ;
VAL_ 994 VCLEFT_tailTrailerLightStatus 0 "OFF" 1 "ON" 2 "FAULT" 3 "SNA" ;
VAL_ 994 VCLEFT_brakeTrailerLightStatus 0 "OFF" 1 "ON" 2 "FAULT" 3 "SNA" ;
VAL_ 994 VCLEFT_rightTrnTrailerLightStatus 0 "OFF" 1 "ON" 2 "FAULT" 3 "SNA" ;
VAL_ 994 VCLEFT_leftTurnTrailerLightStatus 0 "OFF" 1 "ON" 2 "FAULT" 3 "SNA" ;
VAL_ 994 VCLEFT_RRMapLightStatus 0 "OFF" 1 "ON" 2 "FAULT" 3 "SNA" ;
VAL_ 994 VCLEFT_RLMapLightStatus 0 "OFF" 1 "ON" 2 "FAULT" 3 "SNA" ;
VAL_ 994 VCLEFT_FRMapLightStatus 0 "OFF" 1 "ON" 2 "FAULT" 3 "SNA" ;
VAL_ 994 VCLEFT_FLMapLightStatus 0 "OFF" 1 "ON" 2 "FAULT" 3 "SNA" ;
VAL_ 994 VCLEFT_turnSignalStatus 0 "OFF" 1 "ON" 2 "FAULT" 3 "SNA" ;
VAL_ 994 VCLEFT_tailLightStatus 0 "OFF" 1 "ON" 2 "FAULT" 3 "SNA" ;
VAL_ 994 VCLEFT_brakeLightStatus 0 "OFF" 1 "ON" 2 "FAULT" 3 "SNA" ;
VAL_ 995 VCRIGHT_rearFogLightStatus 0 "OFF" 1 "ON" 2 "FAULT" 3 "SNA" ;
VAL_ 995 VCRIGHT_reverseLightStatus 0 "OFF" 1 "ON" 2 "FAULT" 3 "SNA" ;
VAL_ 995 VCRIGHT_turnSignalStatus 0 "OFF" 1 "ON" 2 "FAULT" 3 "SNA" ;
VAL_ 995 VCRIGHT_tailLightStatus 0 "OFF" 1 "ON" 2 "FAULT" 3 "SNA" ;
VAL_ 995 VCRIGHT_brakeLightStatus 0 "OFF" 1 "ON" 2 "FAULT" 3 "SNA" ;
VAL_ 1001 DAS_turnIndicatorRequestReason 0 "NONE" 1 "ACTIVE_NAV_LANE_CHANGE" 2 "ACTIVE_SPEED_LANE_CHANGE" 3 "ACTIVE_FORK" 4 "CANCEL_LANE_CHANGE" 5 "CANCEL_FORK" 6 "ACTIVE_MERGE" 7 "CANCEL_MERGE" 8 "ACTIVE_COMMANDED_LANE_CHANGE" 9 "ACTIVE_INTERSECTION" 10 "CANCEL_INTERSECTION" 11 "ACTIVE_SUMMMON" 12 "CANCEL_SUMMMON" 13 "ACTIVE_AUTO_PARK" 14 "CANCEL_AUTO_PARK" 15 "CANCEL_MANUAL_BLINKER" 17 "ACTIVE_STATIC_OBJECT_LANE_CHANGE" 18 "ACTIVE_INCORRECT_ROAD_SIDE_LANE_CHANGE" 19 "ACTIVE_EXIT_PASSING_LANE_LANE_CHANGE" 20 "ACTIVE_EXIT_RIGHT_LANE_LANE_CHANGE" 21 "ACTIVE_AWAY_FROM_MERGE_LANE_CHANGE" 22 "ACTIVE_STAY_OUT_OF_RIGHTMOST_LANE_LANE_CHANGE" 23 "ACTIVE_INFEASIBLE_KINEMATICS_LANE_CHANGE" ;
VAL_ 1001 DAS_autoWiperState 0 "OFF" 1 "SLOW_INTERMITTENT" 2 "FAST_INTERMITTENT" 3 "SLOW_CONTINUOUS" 4 "FAST_CONTINUOUS" 5 "SNA" ;
VAL_ 1001 DAS_mirrorFoldRequest 0 "NONE" 1 "FOLD" 2 "UNFOLD" 3 "SNA" ;
VAL_ 1001 DAS_highLowBeamOffReason 0 "ON" 1 "OFF_REASON_MOVING_VISION_TARGET" 2 "OFF_REASON_MOVING_RADAR_TARGET" 3 "OFF_REASON_AMBIENT_LIGHT" 4 "OFF_REASON_HEAD_LIGHT" 5 "OFF_REASON_SNA" ;
VAL_ 1001 DAS_heaterRequest 0 "SNA" 1 "OFF" 2 "ON" ;
VAL_ 1001 DAS_highLowBeamDecision 0 "UNDECIDED" 1 "OFF" 2 "ON" 3 "SNA" ;
VAL_ 1001 DAS_turnIndicatorRequest 0 "NONE" 1 "LEFT" 2 "RIGHT" 3 "CANCEL" 4 "DEFER" ;
VAL_ 1001 DAS_wiperSpeed 0 "OFF" 1 "1" 2 "2" 3 "3" 4 "4" 5 "5" 6 "6" 7 "7" 8 "8" 9 "9" 10 "10" 11 "11" 12 "12" 13 "13" 14 "14" 15 "INVALID" ;
VAL_ 1001 DAS_hazardLightRequest 0 "OFF" 1 "ON" 2 "UNUSED" 3 "SNA" ;
VAL_ 1001 DAS_headlightRequest 0 "OFF" 1 "ON" 3 "INVALID" ;
VAL_ 1010 BMS_kwhCounter_Id 0 "MUX0" 1 "MUX1" 2 "MUX2" 3 "MUX3" 4 "MUX4" 5 "MUX5" 6 "MUX6" 7 "MUX7" 8 "MUX8" 9 "MUX9" 10 "MUX10" 11 "MUX11" 12 "MUX12" 13 "MUX13" 14 "END" ;
VAL_ 1013 VCFRONT_highBeamLatchingState 0 "SNA" 1 "UNLATCHED" 2 "LATCHING" 3 "LATCHED" ;
VAL_ 1013 VCFRONT_lightingCoreState 0 "OFF" 1 "POS_PARK" 2 "DRL" 3 "DRL_PLUS_REAR_POS_PARK" 4 "LOW_BEAMS" 15 "SNA" ;
VAL_ 1013 VCFRONT_switchLightingBrightness 255 "SNA" ;
VAL_ 1013 VCFRONT_ambientLightingBrightnes 255 "SNA" ;
VAL_ 1013 VCFRONT_hazardLightRequest 0 "NONE" 1 "BUTTON" 2 "LOCK" 3 "UNLOCK" 4 "MISLOCK" 5 "CRASH" 6 "CAR_ALARM" 7 "DAS" 8 "UDS" ;
VAL_ 1013 VCFRONT_indicatorRightRequest 0 "OFF" 1 "ACTIVE_LOW" 2 "ACTIVE_HIGH" ;
VAL_ 1013 VCFRONT_indicatorLeftRequest 0 "OFF" 1 "ACTIVE_LOW" 2 "ACTIVE_HIGH" ;
VAL_ 1014 VCFRONT_parkRightStatus 0 "OFF" 1 "ON" 2 "FAULT" 3 "SNA" ;
VAL_ 1014 VCFRONT_parkLeftStatus 0 "OFF" 1 "ON" 2 "FAULT" 3 "SNA" ;
VAL_ 1014 VCFRONT_turnSignalRightStatus 0 "OFF" 1 "ON" 2 "FAULT" 3 "SNA" ;
VAL_ 1014 VCFRONT_turnSignalLeftStatus 0 "OFF" 1 "ON" 2 "FAULT" 3 "SNA" ;
VAL_ 1014 VCFRONT_sideRepeaterRightStatus 0 "OFF" 1 "ON" 2 "FAULT" 3 "SNA" ;
VAL_ 1014 VCFRONT_sideRepeaterLeftStatus 0 "OFF" 1 "ON" 2 "FAULT" 3 "SNA" ;
VAL_ 1014 VCFRONT_sideMarkersStatus 0 "OFF" 1 "ON" 2 "FAULT" 3 "SNA" ;
VAL_ 1014 VCFRONT_fogRightStatus 0 "OFF" 1 "ON" 2 "FAULT" 3 "SNA" ;
VAL_ 1014 VCFRONT_fogLeftStatus 0 "OFF" 1 "ON" 2 "FAULT" 3 "SNA" ;
VAL_ 1014 VCFRONT_DRLRightStatus 0 "OFF" 1 "ON" 2 "FAULT" 3 "SNA" ;
VAL_ 1014 VCFRONT_DRLLeftStatus 0 "OFF" 1 "ON" 2 "FAULT" 3 "SNA" ;
VAL_ 1014 VCFRONT_highBeamRightStatus 0 "OFF" 1 "ON" 2 "FAULT" 3 "SNA" ;
VAL_ 1014 VCFRONT_highBeamLeftStatus 0 "OFF" 1 "ON" 2 "FAULT" 3 "SNA" ;
VAL_ 1014 VCFRONT_lowBeamRightStatus 0 "OFF" 1 "ON" 2 "FAULT" 3 "SNA" ;
VAL_ 1014 VCFRONT_lowBeamLeftStatus 0 "OFF" 1 "ON" 2 "FAULT" 3 "SNA" ;
VAL_ 1018 APP_backupCameraLUX 254 "SATURATED" 255 "SNA" ;
VAL_ 1018 APP_rPillarCameraLUX 254 "SATURATED" 255 "SNA" ;
VAL_ 1018 APP_lPillarCameraLUX 254 "SATURATED" 255 "SNA" ;
VAL_ 1018 APP_rRepeatCameraLUX 254 "SATURATED" 255 "SNA" ;
VAL_ 1018 APP_lRepeatCameraLUX 254 "SATURATED" 255 "SNA" ;
VAL_ 1018 APP_fisheyeCameraLUX 254 "SATURATED" 255 "SNA" ;
VAL_ 1018 APP_narrowCameraLUX 254 "SATURATED" 255 "SNA" ;
VAL_ 1018 APP_mainCameraLUX 254 "SATURATED" 255 "SNA" ;
VAL_ 1022 DI_brakeRRTemp 1023 "SNA" ;
VAL_ 1022 DI_brakeRLTemp 1023 "SNA" ;
VAL_ 1022 DI_brakeFRTemp 1023 "SNA" ;
VAL_ 1022 DI_brakeFLTemp 1023 "SNA" ;
VAL_ 1031 DAS_frunkRequest 0 "NONE" 1 "MOVE" 2 "STOP" 3 "SNA" ;
VAL_ 1031 DAS_windowRequest 0 "IDLE" 1 "GOTO_PERCENT" 2 "GOTO_VENT" 3 "GOTO_CLOSED" 4 "GOTO_OPEN" ;
VAL_ 1031 DAS_trunkRequest 0 "NONE" 1 "MOVE" 2 "STOP" 3 "SNA" ;
VAL_ 1033 DAS_nmKeepAwakeReason 0 "NONE_SNA" 1 "CTRS_CLOSED" 2 "CRITICAL_ALERT" 3 "FC_CTR_CLEANING" 4 "HVP_ACTIVE" 5 "BMS_ACTIVE" 6 "CP_ACTIVE" ;
VAL_ 1033 DAS_nmWakeUpReason 0 "NONE" 1 "CAN_VEH" 2 "CAN_HVS" 3 "WANTTOCHARGE" 4 "CRITICALALERT" 5 "WANTTOWARM" ;
VAL_ 1034 VCLEFT_seatTrackPosition 0 "FORWARD" 1 "REARWARD" 2 "NOT_CONFIGURED" 3 "FAULTED" 7 "SNA" ;
VAL_ 1034 VCLEFT_rearCenterBuckleStatus 0 "UNLATCHED" 1 "LATCHED" 2 "FAULTED" 3 "SNA" ;
VAL_ 1034 VCLEFT_rearLeftBuckleStatus 0 "UNLATCHED" 1 "LATCHED" 2 "FAULTED" 3 "SNA" ;
VAL_ 1034 VCLEFT_rearRightOccupancyStatus 0 "UNOCCUPIED" 1 "OCCUPIED" 2 "OCCUPANCY_FAULTED" 3 "OCCUPANCY_SNA" ;
VAL_ 1034 VCLEFT_rearCenterOccupancyStatus 0 "UNOCCUPIED" 1 "OCCUPIED" 2 "OCCUPANCY_FAULTED" 3 "OCCUPANCY_SNA" ;
VAL_ 1034 VCLEFT_rearLeftOccupancyStatus 0 "UNOCCUPIED" 1 "OCCUPIED" 2 "OCCUPANCY_FAULTED" 3 "OCCUPANCY_SNA" ;
VAL_ 1034 VCLEFT_frontBuckleStatus 0 "UNLATCHED" 1 "LATCHED" 2 "FAULTED" 3 "SNA" ;
VAL_ 1034 VCLEFT_frontOccupancyStatus 0 "UNOCCUPIED" 1 "OCCUPIED" 2 "OCCUPANCY_FAULTED" 3 "NOT_CONFIGURED" 7 "OCCUPANCY_SNA" ;
VAL_ 1049 APS_nmKeepAwakeReason 0 "NONE_SNA" 1 "CTRS_CLOSED" 2 "CRITICAL_ALERT" 3 "FC_CTR_CLEANING" 4 "HVP_ACTIVE" 5 "BMS_ACTIVE" 6 "CP_ACTIVE" ;
VAL_ 1049 APS_nmWakeUpReason 0 "NONE" 1 "CAN_VEH" 2 "CAN_HVS" 3 "WANTTOCHARGE" 4 "CRITICALALERT" 5 "WANTTOWARM" ;
VAL_ 1053 CP_nmKeepAwakeReason 0 "NONE_SNA" 1 "CTRS_CLOSED" 2 "CRITICAL_ALERT" 3 "FC_CTR_CLEANING" 4 "HVP_ACTIVE" 5 "BMS_ACTIVE" 6 "CP_ACTIVE" ;
VAL_ 1053 CP_nmWakeUpReason 0 "NONE" 1 "CAN_VEH" 2 "CAN_HVS" 3 "WANTTOCHARGE" 4 "CRITICALALERT" 5 "WANTTOWARM" ;
VAL_ 1056 APS_B_faultState 0 "NONE" 1 "GIC" 2 "MIF_ECC_CORRECTED" 3 "MIF_ECC_UNCORRECTED" 4 "MIF0_DFI_ALERT" 5 "MIF1_DFI_ALERT" 6 "MIF2_DFI_ALERT" 7 "MIF3_DFI_ALERT" 8 "MIF4_DFI_ALERT" 9 "MIF5_DFI_ALERT" 10 "MIF6_DFI_ALERT" 11 "MIF7_DFI_ALERT" 12 "MIF_ECC_AP" 13 "DROOP_CPUCL0" 14 "DROOP_CPUCL1" 15 "DROOP_CPUCL2" 16 "DROOP_GPU" 17 "DROOP_TRIP" 18 "CPU_FAULT" 19 "WDT" 20 "TRIP0_FAULT" 21 "TRIP1_FAULT" 22 "SOFTWARE_FAULT" 23 "SCS" 24 "UNEXPECTED" 25 "MIA" 26 "UNKNOWN" 27 "COUNT" ;
VAL_ 1056 APS_B_resetState 0 "NOT_RESETTING" 1 "RESETTING" 2 "FAULT" 3 "MIA" 4 "UNKNOWN" 5 "COUNT" ;
VAL_ 1056 APS_B_sleepState 0 "IDLE" 1 "WAIT_FOR_BUS_SILENCE" 2 "READY" 3 "GOING_TO_SLEEP" 4 "SLEEPING" 5 "ABORT" 6 "FAULT" 7 "MIA" 8 "UNKNOWN" 9 "COUNT" ;
VAL_ 1056 APS_B_powerState 0 "IDLE" 1 "AP_ON_PREPARE" 2 "AP_ON_PREPARE_WAIT_FOR_ACK" 3 "AP_ON_PREPARE_WAIT_FOR_RESPONSE" 4 "AP_ON_READY" 5 "AP_ON_READY_WAIT_FOR_ACK" 6 "AP_ON_READY_WAIT_FOR_RESPONSE" 7 "AP_BOOTING" 8 "AP_IN_COREBOOT" 9 "AP_ON" 10 "AP_WAIT_FOR_SHUTDOWN" 11 "AP_OFF_PREPARE" 12 "AP_OFF_READY" 13 "AP_OFF_READY_WAIT_FOR_ACK" 14 "AP_OFF_READY_WAIT_FOR_RESPONSE" 15 "AP_OFF_ABORT" 16 "AP_OFF_ABORT_WAIT_FOR_ACK" 17 "AP_SUSPENDED" 18 "SOC_OFF_READY" 19 "SOC_OFF" 20 "SOC_OFF_ABORT" 21 "FAULT" 22 "MIA" 23 "UNKNOWN" 24 "COUNT" ;
VAL_ 1056 APS_B_arbState 0 "INIT" 1 "IDLE" 2 "PRIMARY" 3 "SECONDARY" 4 "FAULT" 5 "MIA" 6 "UNKNOWN" 7 "COUNT" ;
VAL_ 1056 APS_secondaryTurbo 0 "A" 1 "B" 2 "UNKNOWN" ;
VAL_ 1056 APS_A_faultState 0 "NONE" 1 "GIC" 2 "MIF_ECC_CORRECTED" 3 "MIF_ECC_UNCORRECTED" 4 "MIF0_DFI_ALERT" 5 "MIF1_DFI_ALERT" 6 "MIF2_DFI_ALERT" 7 "MIF3_DFI_ALERT" 8 "MIF4_DFI_ALERT" 9 "MIF5_DFI_ALERT" 10 "MIF6_DFI_ALERT" 11 "MIF7_DFI_ALERT" 12 "MIF_ECC_AP" 13 "DROOP_CPUCL0" 14 "DROOP_CPUCL1" 15 "DROOP_CPUCL2" 16 "DROOP_GPU" 17 "DROOP_TRIP" 18 "CPU_FAULT" 19 "WDT" 20 "TRIP0_FAULT" 21 "TRIP1_FAULT" 22 "SOFTWARE_FAULT" 23 "SCS" 24 "UNEXPECTED" 25 "MIA" 26 "UNKNOWN" 27 "COUNT" ;
VAL_ 1056 APS_A_resetState 0 "NOT_RESETTING" 1 "RESETTING" 2 "FAULT" 3 "MIA" 4 "UNKNOWN" 5 "COUNT" ;
VAL_ 1056 APS_A_sleepState 0 "IDLE" 1 "WAIT_FOR_BUS_SILENCE" 2 "READY" 3 "GOING_TO_SLEEP" 4 "SLEEPING" 5 "ABORT" 6 "FAULT" 7 "MIA" 8 "UNKNOWN" 9 "COUNT" ;
VAL_ 1056 APS_A_powerState 0 "IDLE" 1 "AP_ON_PREPARE" 2 "AP_ON_PREPARE_WAIT_FOR_ACK" 3 "AP_ON_PREPARE_WAIT_FOR_RESPONSE" 4 "AP_ON_READY" 5 "AP_ON_READY_WAIT_FOR_ACK" 6 "AP_ON_READY_WAIT_FOR_RESPONSE" 7 "AP_BOOTING" 8 "AP_IN_COREBOOT" 9 "AP_ON" 10 "AP_WAIT_FOR_SHUTDOWN" 11 "AP_OFF_PREPARE" 12 "AP_OFF_READY" 13 "AP_OFF_READY_WAIT_FOR_ACK" 14 "AP_OFF_READY_WAIT_FOR_RESPONSE" 15 "AP_OFF_ABORT" 16 "AP_OFF_ABORT_WAIT_FOR_ACK" 17 "AP_SUSPENDED" 18 "SOC_OFF_READY" 19 "SOC_OFF" 20 "SOC_OFF_ABORT" 21 "FAULT" 22 "MIA" 23 "UNKNOWN" 24 "COUNT" ;
VAL_ 1056 APS_A_arbState 0 "INIT" 1 "IDLE" 2 "PRIMARY" 3 "SECONDARY" 4 "FAULT" 5 "MIA" 6 "UNKNOWN" 7 "COUNT" ;
VAL_ 1056 APS_primaryTurbo 0 "A" 1 "B" 2 "UNKNOWN" ;
VAL_ 1057 VCFRONT_nmWakeUpReason 0 "NONE" 1 "CAN_VEH" 2 "CAN_HVS" 3 "WANTTOCHARGE" 4 "CRITICALALERT" 5 "WANTTOWARM" ;
VAL_ 1057 VCFRONT_nmKeepAwakeReason 0 "NONE_SNA" 1 "CTRS_CLOSED" 2 "CRITICAL_ALERT" 3 "FC_CTR_CLEANING" 4 "HVP_ACTIVE" 5 "BMS_ACTIVE" 6 "CP_ACTIVE" ;
VAL_ 1058 VCLEFT_nmDebugWakeUp 2147483648 "31" 1073741824 "30" 536870912 "29" 268435456 "28" 134217728 "27" 67108864 "26" 33554432 "25" 16777216 "24" 0 "NONE" 256 "8" 512 "9" 1024 "10" 2048 "11" 4096 "12" 8192 "13" 16384 "14" 32768 "15" 1 "0" 65536 "16" 2 "1" 131072 "17" 4 "2" 262144 "18" 8 "3" 524288 "19" 16 "4" 1048576 "20" 32 "5" 2097152 "21" 64 "6" 4194304 "22" 128 "7" 8388608 "23" ;
VAL_ 1058 VCLEFT_nmWakeUpReason 0 "NONE" 1 "CAN_VEH" 2 "CAN_HVS" 3 "WANTTOCHARGE" 4 "CRITICALALERT" 5 "WANTTOWARM" ;
VAL_ 1058 VCLEFT_nmKeepAwakeReason 0 "NONE_SNA" 1 "CTRS_CLOSED" 2 "CRITICAL_ALERT" 3 "FC_CTR_CLEANING" 4 "HVP_ACTIVE" 5 "BMS_ACTIVE" 6 "CP_ACTIVE" ;
VAL_ 1059 VCRIGHT_nmDebugWakeUp 0 "NONE" 1 "0" 2 "1" 4 "2" 8 "3" 16 "4" 32 "5" 64 "6" 128 "7" 256 "8" 512 "9" 1024 "10" 2048 "11" 4096 "12" 8192 "13" 16384 "14" 32768 "15" 65536 "16" 131072 "17" 262144 "18" 524288 "19" 1048576 "20" 2097152 "21" 4194304 "22" 8388608 "23" 16777216 "24" 33554432 "25" 67108864 "26" 134217728 "27" 268435456 "28" 536870912 "29" 1073741824 "30" 2147483648 "31" ;
VAL_ 1059 VCRIGHT_nmWakeUpReason 0 "NONE" 1 "ECU_SPECIFIC" 2 "SWITCH_INPUT" 3 "RESET" 4 "DOOR_LATCH" 5 "INTERIOR_HANDLE" 6 "EXTERIOR_HANDLE" 7 "LIN_RX" 8 "TRUNK_SWITCH" 9 "TRUNK_LATCH" 10 "CABIN_HOT" 11 "POWER_ON_RESET" 15 "UNKNOWN" ;
VAL_ 1059 VCRIGHT_nmKeepAwakeReason 0 "NONE_SNA" 1 "EPB_STATE_NOT_SAVED" 2 "EPB_NOT_SECURE" 3 "HVAC_CABIN_PURGE" 4 "HVAC_PRECONDITIONING" 5 "CLOSURE_LATCH" 6 "EPB_SUMMON_ACTIVE" 7 "HANDLE" 8 "SEAT" 9 "TRUNK_LIGHT" 10 "UDS_ACTIVE" 11 "HVAC_EVAP_DRYING" 12 "TRUNK_SWITCH" 14 "OTHER" 15 "MULTIPLE" ;
VAL_ 1064 EPBL_nmDebugWakeUp 2147483648 "31" 1073741824 "30" 536870912 "29" 268435456 "28" 134217728 "27" 67108864 "26" 33554432 "25" 16777216 "24" 0 "NONE" 256 "8" 512 "9" 1024 "10" 2048 "11" 4096 "12" 8192 "13" 16384 "14" 32768 "15" 1 "0" 65536 "16" 2 "1" 131072 "17" 4 "2" 262144 "18" 8 "3" 524288 "19" 16 "4" 1048576 "20" 32 "5" 2097152 "21" 64 "6" 4194304 "22" 128 "7" 8388608 "23" ;
VAL_ 1064 EPBL_nmWakeUpReason 0 "NONE" 1 "CAN_VEH" 2 "CAN_HVS" 3 "WANTTOCHARGE" 4 "CRITICALALERT" 5 "WANTTOWARM" ;
VAL_ 1064 EPBL_nmKeepAwakeReason 0 "NONE_SNA" 1 "CTRS_CLOSED" 2 "CRITICAL_ALERT" 3 "FC_CTR_CLEANING" 4 "HVP_ACTIVE" 5 "BMS_ACTIVE" 6 "CP_ACTIVE" ;
VAL_ 1066 VCSEC_TPMSConnectionTypeDesired3 0 "FAST" 1 "SLOW" 2 "UNKNOWN" ;
VAL_ 1066 VCSEC_TPMSConnectionTypeCurrent3 0 "FAST" 1 "SLOW" 2 "UNKNOWN" ;
VAL_ 1066 VCSEC_TPMSSensorState3 0 "NOT_PAIRED" 1 "WAIT_FOR_ADV" 2 "WAIT_FOR_CONN" 3 "CONNECTED" 4 "DISCONNECTING" ;
VAL_ 1066 VCSEC_TPMSConnectionTypeDesired2 0 "FAST" 1 "SLOW" 2 "UNKNOWN" ;
VAL_ 1066 VCSEC_TPMSConnectionTypeCurrent2 0 "FAST" 1 "SLOW" 2 "UNKNOWN" ;
VAL_ 1066 VCSEC_TPMSSensorState2 0 "NOT_PAIRED" 1 "WAIT_FOR_ADV" 2 "WAIT_FOR_CONN" 3 "CONNECTED" 4 "DISCONNECTING" ;
VAL_ 1066 VCSEC_TPMSConnectionTypeDesired1 0 "FAST" 1 "SLOW" 2 "UNKNOWN" ;
VAL_ 1066 VCSEC_TPMSConnectionTypeCurrent1 0 "FAST" 1 "SLOW" 2 "UNKNOWN" ;
VAL_ 1066 VCSEC_TPMSSensorState1 0 "NOT_PAIRED" 1 "WAIT_FOR_ADV" 2 "WAIT_FOR_CONN" 3 "CONNECTED" 4 "DISCONNECTING" ;
VAL_ 1066 VCSEC_TPMSConnectionTypeDesired0 0 "FAST" 1 "SLOW" 2 "UNKNOWN" ;
VAL_ 1066 VCSEC_TPMSConnectionTypeCurrent0 0 "FAST" 1 "SLOW" 2 "UNKNOWN" ;
VAL_ 1066 VCSEC_TPMSSensorState0 0 "NOT_PAIRED" 1 "WAIT_FOR_ADV" 2 "WAIT_FOR_CONN" 3 "CONNECTED" 4 "DISCONNECTING" ;
VAL_ 1081 VCSEC_nmDebugWakeUp 2147483648 "31" 1073741824 "30" 536870912 "29" 268435456 "28" 134217728 "27" 67108864 "26" 33554432 "25" 16777216 "24" 0 "NONE" 256 "8" 512 "9" 1024 "10" 2048 "11" 4096 "12" 8192 "13" 16384 "14" 32768 "15" 1 "0" 65536 "16" 2 "1" 131072 "17" 4 "2" 262144 "18" 8 "3" 524288 "19" 16 "4" 1048576 "20" 32 "5" 2097152 "21" 64 "6" 4194304 "22" 128 "7" 8388608 "23" ;
VAL_ 1081 VCSEC_nmWakeUpReason 0 "NONE" 1 "CAN_VEH" 2 "CAN_HVS" 3 "WANTTOCHARGE" 4 "CRITICALALERT" 5 "WANTTOWARM" ;
VAL_ 1081 VCSEC_nmKeepAwakeReason 0 "NONE_SNA" 1 "CTRS_CLOSED" 2 "CRITICAL_ALERT" 3 "FC_CTR_CLEANING" 4 "HVP_ACTIVE" 5 "BMS_ACTIVE" 6 "CP_ACTIVE" ;
VAL_ 1089 VC_pcsInterfaceMuxIndex 0 "0" 1 "1" ;
VAL_ 1096 EPBR_nmDebugWakeUp 2147483648 "31" 1073741824 "30" 536870912 "29" 268435456 "28" 134217728 "27" 67108864 "26" 33554432 "25" 16777216 "24" 0 "NONE" 256 "8" 512 "9" 1024 "10" 2048 "11" 4096 "12" 8192 "13" 16384 "14" 32768 "15" 1 "0" 65536 "16" 2 "1" 131072 "17" 4 "2" 262144 "18" 8 "3" 524288 "19" 16 "4" 1048576 "20" 32 "5" 2097152 "21" 64 "6" 4194304 "22" 128 "7" 8388608 "23" ;
VAL_ 1096 EPBR_nmWakeUpReason 0 "NONE" 1 "CAN_VEH" 2 "CAN_HVS" 3 "WANTTOCHARGE" 4 "CRITICALALERT" 5 "WANTTOWARM" ;
VAL_ 1096 EPBR_nmKeepAwakeReason 0 "NONE_SNA" 1 "CTRS_CLOSED" 2 "CRITICAL_ALERT" 3 "FC_CTR_CLEANING" 4 "HVP_ACTIVE" 5 "BMS_ACTIVE" 6 "CP_ACTIVE" ;
VAL_ 1112 GTW_nmWakeUpReason 0 "NONE" 1 "RESET" 2 "GSM_RI" 3 "CH_CAN" 4 "VEH_CAN" 5 "VEH_CAN" 6 "VCFRONT" 7 "RTC_ALARM" 8 "UI_SCHEDULED" ;
VAL_ 1112 GTW_nmKeepAwakeReason 0 "NONE_SNA" 15 "TBD" ;
VAL_ 1114 VCRIGHT_AP_tempDuctDefrost 255 "SNA" ;
VAL_ 1114 VCRIGHT_AP_hvacAirDistributionMode 0 "NONE" 1 "FLOOR" 2 "PANEL" 3 "PANEL_FLOOR" 4 "DEFROST" 5 "DEFROST_FLOOR" 6 "DEFROST_PANEL" 7 "DEFROST_PANEL_FLOOR" ;
VAL_ 1114 VCRIGHT_AP_cabinTempSideGlassLeft 255 "SNA" ;
VAL_ 1114 VCRIGHT_AP_cabinTempSideGlassRight 255 "SNA" ;
VAL_ 1114 VCRIGHT_AP_cabinTempWindshield 255 "SNA" ;
VAL_ 1114 VCRIGHT_AP_hvacModelInitStatus 0 "NOT_INIT_WAIT_FOR_SENSORS" 1 "NOT_INIT_WAIT_FOR_GTW" 2 "INIT_FROM_SENSORS" 3 "INIT_FROM_SENSORS_PREDICTION_ERROR" 4 "INIT_FORWARD_CALC" 5 "INIT_WAITING_FOR_SENSORS" ;
VAL_ 1139 UI_nmKeepAwakeReason 0 "NONE_SNA" 1 "KEEPALIVEACTIVE" 2 "GUI_NEVER_SLEEP_SET" 3 "PM_CHECKING" 4 "UNKNOWN_REMOTE_REQUEST" 5 "MODEM_RESET" 6 "UPDATER" 7 "HERMES" 8 "AUTOFUSER" 9 "UPDATE_COUNTDOWN" 10 "ECALL_ACTIVE" 11 "SELFTEST" 12 "SENTRY_MODE" 13 "MEDIA_DOWNLOAD" 14 "ODIN" 15 "MULTIPLE" ;
VAL_ 1250 VCLEFT_frontSeatBackState 0 "STOPPED" 1 "MOVING_UP" 2 "MOVING_DOWN" 3 "RECALLING" 4 "CALIBRATING" 5 "UNDEFINED" ;
VAL_ 1250 VCLEFT_frontSeatLiftState 0 "STOPPED" 1 "MOVING_UP" 2 "MOVING_DOWN" 3 "RECALLING" 4 "CALIBRATING" 5 "UNDEFINED" ;
VAL_ 1250 VCLEFT_frontSeatTiltState 0 "STOPPED" 1 "MOVING_UP" 2 "MOVING_DOWN" 3 "RECALLING" 4 "CALIBRATING" 5 "UNDEFINED" ;
VAL_ 1250 VCLEFT_frontSeatTrackState 0 "STOPPED" 1 "MOVING_UP" 2 "MOVING_DOWN" 3 "RECALLING" 4 "CALIBRATING" 5 "UNDEFINED" ;
VAL_ 1250 VCLEFT_lumbarBState 0 "STOPPED" 1 "MOVING_UP" 2 "MOVING_DOWN" 3 "RECALLING" 4 "CALIBRATING" 5 "UNDEFINED" ;
VAL_ 1250 VCLEFT_lumbarAState 0 "STOPPED" 1 "MOVING_UP" 2 "MOVING_DOWN" 3 "RECALLING" 4 "CALIBRATING" 5 "UNDEFINED" ;
VAL_ 1250 VCLEFT_seatStatusIndex 0 "TRACK" 1 "BACK" 2 "LIFT" 3 "TILT" 4 "LUMBAR" 5 "POSITION" ;
VAL_ 1251 VCRIGHT_frontSeatBackState 0 "STOPPED" 1 "MOVING_UP" 2 "MOVING_DOWN" 3 "RECALLING" 4 "CALIBRATING" 5 "UNDEFINED" ;
VAL_ 1251 VCRIGHT_frontSeatLiftState 0 "STOPPED" 1 "MOVING_UP" 2 "MOVING_DOWN" 3 "RECALLING" 4 "CALIBRATING" 5 "UNDEFINED" ;
VAL_ 1251 VCRIGHT_frontSeatTiltState 0 "STOPPED" 1 "MOVING_UP" 2 "MOVING_DOWN" 3 "RECALLING" 4 "CALIBRATING" 5 "UNDEFINED" ;
VAL_ 1251 VCRIGHT_frontSeatTrackState 0 "STOPPED" 1 "MOVING_UP" 2 "MOVING_DOWN" 3 "RECALLING" 4 "CALIBRATING" 5 "UNDEFINED" ;
VAL_ 1251 VCRIGHT_lumbarBState 0 "STOPPED" 1 "MOVING_UP" 2 "MOVING_DOWN" 3 "RECALLING" 4 "CALIBRATING" 5 "UNDEFINED" ;
VAL_ 1251 VCRIGHT_lumbarAState 0 "STOPPED" 1 "MOVING_UP" 2 "MOVING_DOWN" 3 "RECALLING" 4 "CALIBRATING" 5 "UNDEFINED" ;
VAL_ 1251 VCRIGHT_seatStatusIndex 0 "TRACK" 1 "BACK" 2 "LIFT" 3 "TILT" 4 "LUMBAR" 5 "POSITION" ;
VAL_ 1310 FC_infoHardwareRevision 252 "CONFIGURABLE_HWID_PLACEHOLDER" ;
VAL_ 1310 FC_infoMaturity 254 "LOCAL_BUILD" 255 "SNA" ;
VAL_ 1310 FC_infoBranchOrigin 254 "LOCAL_BUILD" 255 "SNA" ;
VAL_ 1310 FC_infoMajorVersion 254 "LOCAL_BUILD" 255 "SNA" ;
VAL_ 1310 FC_infoBuildType 0 "UNKNOWN_BUILD_FC" 1 "PLATFORM_BUILD_FC" 2 "LOCAL_BUILD_FC" 3 "TRACEABLE_CI_BUILD_FC" 4 "MFG_BUILD_FC" ;
VAL_ 1310 FC_infoIndex 0 "DEPRECATED_0_FC" 1 "DEPRECATED_1_FC" 2 "DEPRECATED_2_FC" 3 "DEPRECATED_3_FC" 4 "DEPRECATED_4_FC" 5 "DEPRECATED_5_FC" 6 "DEPRECATED_6_FC" 7 "DEPRECATED_7_FC" 8 "DEPRECATED_8_FC" 9 "DEPRECATED_9_FC" 10 "BUILD_HWID_COMPONENTID_FC" 11 "PCBAID_ASSYID_USAGEID_FC" 13 "APP_CRC_FC" 14 "BOOTLOADER_SVN_FC" 15 "BOOTLOADER_CRC_FC" 16 "SUBCOMPONENT_FC" 17 "APP_GITHASH_FC" 18 "BOOTLOADER_GITHASH_FC" 19 "VERSION_DEPRECATED_FC" 20 "UDS_PROTOCOL_BOOTCRC_FC" 22 "VARIANT_CRC_FC" 25 "PART_NUM_1" 26 "PART_NUM_2" 27 "PART_NUM_3" 255 "END_FC" ;
VAL_ 1342 CP_hardwareId 252 "CONFIGURABLE_HWID_PLACEHOLDER" ;
VAL_ 1342 CP_buildType 0 "UNKNOWN_BUILD" 1 "PLATFORM_BUILD" 2 "LOCAL_BUILD" 3 "TRACEABLE_CI_BUILD" 4 "MFG_BUILD" ;
VAL_ 1342 CP_platformType 0 "UNKNOWN" 3 "MODEL3" 255 "END" ;
VAL_ 1342 CP_infoIndex 0 "DEPRECATED_0" 1 "DEPRECATED_1" 2 "DEPRECATED_2" 3 "DEPRECATED_3" 4 "DEPRECATED_4" 5 "DEPRECATED_5" 6 "DEPRECATED_6" 7 "DEPRECATED_7" 8 "DEPRECATED_8" 9 "DEPRECATED_9" 10 "BUILD_HWID_COMPONENTID" 11 "PCBAID_ASSYID_USAGEID" 13 "APP_CRC" 14 "BOOTLOADER_SVN" 15 "BOOTLOADER_CRC" 16 "SUBCOMPONENT" 17 "APP_GITHASH" 18 "BOOTLOADER_GITHASH" 19 "VERSION_DEPRECATED" 20 "UDS_PROTOCOL_BOOTCRC" 22 "VARIANTCRC" 25 "PACKAGE_PN_1_7" 26 "PACKAGE_PN_8_14" 27 "PACKAGE_PN_15_20" 29 "PACKAGE_SN_1_7" 30 "PACKAGE_SN_8_14" 31 "SUBCOMPONENT_GITHASH" 255 "END" ;
VAL_ 1345 FC_maxCurrentLimit 8191 "SNA" ;
VAL_ 1345 FC_maxPowerLimit 8191 "SNA" ;
VAL_ 1349 VCFRONT_vehicleLoadShedStage 0 "IDLE_OR_UNDEFINED" 1 "1" 2 "2" 3 "3" ;
VAL_ 1349 VCFRONT_DCDCSaturationLoadShedStage 0 "IDLE" 255 "MAX" ;
VAL_ 1349 VCFRONT_VCRightEFuseLoadShedStage 0 "IDLE" 255 "MAX" ;
VAL_ 1349 VCFRONT_loadShedReason 0 "NONE" 1 "DCDC_EFUSE_PROTECTION" 2 "LVBRIDGE_EFUSE_PROTECTION" 4 "DCDC_SATURATION" 8 "POST_CRASH" 16 "HV_FAULT" ;
VAL_ 1349 VCFRONT_systemStatusMuxIndex 0 "SYSTEM_DATA" 1 "ACTIVE_LOAD_SHED_REASONS" 2 "LOAD_SHED_STATUSES_AND_COMMANDS" ;
VAL_ 1353 VCFRONT_homelinkCommStatus 0 "SNA" 1 "OFF" 2 "ON" 3 "FAULT" ;
VAL_ 1359 SCCM_matrixIndex 0 "SCCM_AlertMatrix0" ;
VAL_ 1362 VCLEFT_loadShedReason 0 "NONE" 1 "DCDC_EFUSE_PROTECTION" 2 "LVBRIDGE_EFUSE_PROTECTION" 4 "DCDC_SATURATION" 8 "POST_CRASH" 16 "HV_FAULT" ;
VAL_ 1363 VCRIGHT_loadShedReason 0 "NONE" 1 "DCDC_EFUSE_PROTECTION" 2 "LVBRIDGE_EFUSE_PROTECTION" 4 "DCDC_SATURATION" 8 "POST_CRASH" 16 "HV_FAULT" ;
VAL_ 1523 UI_odometer 16777215 "SNA" ;
VAL_ 1638 GTW_diagLevel 0 "FACTORY" 10 "DIAG_LINK_ACTIVE" 25 "SERVICE" 50 "SERVICE_DRIVE" 80 "PARK" 100 "NORMAL_OPERATION" ;
VAL_ 1655 VC_LVBMS_MOSTemperature 4095 "SNA" ;
VAL_ 1655 VC_LVBMS_maxAllowedDischargeCurrent 8191 "SNA" ;
VAL_ 1655 VC_LVBMS_packTemperature 511 "SNA" ;
VAL_ 1655 VC_LVBMS_maxAllowedChargeCurrent 8191 "SNA" ;
VAL_ 1655 VC_LVBMS_packVoltage 65535 "SNA" ;
VAL_ 1655 VC_LVBMS_currentTarget 32767 "SNA" ;
VAL_ 1655 VC_LVBMS_chargeType 0 "UNDEFINED" 1 "CONSTANT_CURRENT" 2 "CONSTANT_VOLTAGE" 3 "COMPLETE" 4 "SNA" ;
VAL_ 1655 VC_LVBMS_LINWakeDisabled 0 "ENABLED" 1 "DISABLED" ;
VAL_ 1655 VC_LVBMS_VehicleState 0 "DRIVE" 1 "ACCESSORY" 2 "CONDITIONING" 3 "OFF" ;
VAL_ 1655 VC_LVBMS_MOSState 0 "OPEN" 1 "CLOSED" 2 "INVALID" 3 "SNA" ;
VAL_ 1655 VC_LVBMS_ECPAState 0 "OPEN" 1 "CLOSED" 2 "INVALID" 3 "SNA" ;
VAL_ 1655 VC_LVBMS_sumCellVoltage 65534 "INVALID" 65535 "SNA" ;
VAL_ 1655 VC_LVBMS_packCurrent 4194303 "SNA" ;
VAL_ 1655 VC_LVBMS_voltageTarget 32767 "SNA" ;
VAL_ 1655 VC_lvbmsStatusHighIndex 0 "PACK_VITALS_1" 1 "CELL_VITALS_1" 2 "CELL_VITALS_2" 3 "TARGETS" 4 "STATE_AND_COMMANDS" 5 "PCS_INTERFACE" 6 "INVALID" ;
VAL_ 1666 HVP_hvilStatus 0 "UNKNOWN" 1 "OK" 2 "FAULT" ;
VAL_ 1748 PMR_hardwareId 252 "CONFIGURABLE_HWID_PLACEHOLDER" ;
VAL_ 1748 PMR_buildType 0 "UNKNOWN_BUILD" 1 "PLATFORM_BUILD" 2 "LOCAL_BUILD" 3 "TRACEABLE_CI_BUILD" 4 "MFG_BUILD" ;
VAL_ 1748 PMR_infoIndex 0 "DEPRECATED_0" 1 "DEPRECATED_1" 2 "DEPRECATED_2" 3 "DEPRECATED_3" 4 "DEPRECATED_4" 5 "DEPRECATED_5" 6 "DEPRECATED_6" 7 "DEPRECATED_7" 8 "DEPRECATED_8" 9 "DEPRECATED_9" 10 "BUILD_HWID_COMPONENTID" 11 "PCBAID_ASSYID_USAGEID" 13 "APP_CRC" 14 "BOOTLOADER_SVN" 15 "BOOTLOADER_CRC" 16 "SUBCOMPONENT" 17 "APP_GITHASH" 18 "BOOTLOADER_GITHASH" 19 "VERSION_DEPRECATED" 20 "UDS_PROTOCOL_BOOTCRC" 21 "DI_BUILD_DATA" 255 "END" ;
VAL_ 1803 VCRIGHT_tempIncarCabinDeep 255 "SNA" ;
VAL_ 1816 VC_LVBMS_SOP 16777215 "SNA" ;
VAL_ 1816 VC_LVBMS_MaxSleepCurrent 65535 "SNA" ;
VAL_ 1816 VC_LVBMS_MinSleepCurrent 65535 "SNA" ;
VAL_ 1816 VC_LVBMS_dynamicSOCCorrection 0 "INACTIVE" 1 "ACTIVE" ;
VAL_ 1816 VC_LVBMS_staticSOCCorrection 0 "INACTIVE" 1 "ACTIVE" ;
VAL_ 1816 VC_LVBMS_minCellSOC 127 "SNA" ;
VAL_ 1816 VC_LVBMS_SOH 127 "SNA" ;
VAL_ 1816 VC_LVBMS_TimeSlept 16777215 "SNA" ;
VAL_ 1816 VC_LVBMS_maxCellSOC 127 "SNA" ;
VAL_ 1816 VC_LVBMS_SOE 127 "SNA" ;
VAL_ 1816 VC_LVBMS_AvgSleepCurrent 65535 "SNA" ;
VAL_ 1816 VC_LVBMS_SOC 127 "SNA" ;
VAL_ 1816 VC_LVBMS_sumCellVoltageFiltered 65534 "INVALID" 65535 "SNA" ;
VAL_ 1816 VC_lvbmsStatusLowIndex 0 "STATE" 1 "THROUGHPUT_1" 2 "THROUGHPUT_2" 3 "THROUGHPUT_3" 4 "PACK_VITALS_2" 5 "FAULT_STATS" 6 "CELL_VITALS_3" 7 "CELL_VITALS_4" 8 "INVALID" ;
VAL_ 1828 VCFRONT_loadShedStsBatteryPump_duty 127 "SNA" ;
VAL_ 1828 VCFRONT_loadShedStsCondenserFan_duty 127 "SNA" ;
VAL_ 1828 VCFRONT_loadShedStsPTPump_duty 127 "SNA" ;
VAL_ 1830 VCLEFT_loadShedStsHVACBlower_duty 127 "SNA" ;
VAL_ 1847 VCFRONT_LVBMS_FWBuildType 0 "UNKNOWN_BUILD" 1 "PLATFORM_BUILD" 2 "LOCAL_BUILD" 3 "TRACEABLE_CI_BUILD" 4 "MFG_BUILD" ;
VAL_ 1847 VCFRONT_LVBMS_InfoIndex 0 "PCBAID_ASSYID" 1 "APP_USAGEID_CRC" 2 "GITHASH" 3 "BUILDTYPE" 4 "SERIAL_NUMBER" 5 "INVALID" ;
VAL_ 1858 VCBATT1_LVBMS_MOSTemperature 4095 "SNA" ;
VAL_ 1858 VCBATT1_LVBMS_maxAllowedDischargeCurrent 8191 "SNA" ;
VAL_ 1858 VCBATT1_LVBMS_packTemperature 511 "SNA" ;
VAL_ 1858 VCBATT1_LVBMS_maxAllowedChargeCurrent 8191 "SNA" ;
VAL_ 1858 VCBATT1_LVBMS_packVoltage 65535 "SNA" ;
VAL_ 1858 VCBATT1_LVBMS_currentTarget 32767 "SNA" ;
VAL_ 1858 VCBATT1_LVBMS_chargeType 0 "UNDEFINED" 1 "CONSTANT_CURRENT" 2 "CONSTANT_VOLTAGE" 3 "COMPLETE" 4 "SNA" ;
VAL_ 1858 VCBATT1_LVBMS_LINWakeDisabled 0 "ENABLED" 1 "DISABLED" ;
VAL_ 1858 VCBATT1_LVBMS_VehicleState 0 "DRIVE" 1 "ACCESSORY" 2 "CONDITIONING" 3 "OFF" ;
VAL_ 1858 VCBATT1_LVBMS_MOSState 0 "OPEN" 1 "CLOSED" 2 "INVALID" 3 "SNA" ;
VAL_ 1858 VCBATT1_LVBMS_ECPAState 0 "OPEN" 1 "CLOSED" 2 "INVALID" 3 "SNA" ;
VAL_ 1858 VCBATT1_LVBMS_sumCellVoltage 65534 "INVALID" 65535 "SNA" ;
VAL_ 1858 VCBATT1_LVBMS_packCurrent 4294934528 "SNA" ;
VAL_ 1858 VCBATT1_LVBMS_voltageTarget 32767 "SNA" ;
VAL_ 1858 VCBATT1_lvbmsStatusHighIndex 0 "PACK_VITALS_1" 1 "CELL_VITALS_1" 2 "CELL_VITALS_2" 3 "TARGETS" 4 "STATE_AND_COMMANDS" 5 "PCS_INTERFACE" 6 "INVALID" ;
VAL_ 1859 VCRIGHT_mirrorRecallStatus 0 "SNA" 1 "IN_PROGRESS" 2 "COMPLETE" 3 "INTERRUPTED" ;
VAL_ 1859 VCRIGHT_seatRecallStatus 0 "SNA" 1 "IN_PROGRESS" 2 "COMPLETE" 3 "INTERRUPTED" ;
VAL_ 1859 VCRIGHT_systemRecallStatus 0 "SNA" 1 "IN_PROGRESS" 2 "COMPLETE" 3 "INTERRUPTED" ;
VAL_ 1860 VCLEFT_mirrorRecallStatus 0 "SNA" 1 "IN_PROGRESS" 2 "COMPLETE" 3 "INTERRUPTED" ;
VAL_ 1860 VCLEFT_columnRecallStatus 0 "SNA" 1 "IN_PROGRESS" 2 "COMPLETE" 3 "INTERRUPTED" ;
VAL_ 1860 VCLEFT_seatRecallStatus 0 "SNA" 1 "IN_PROGRESS" 2 "COMPLETE" 3 "INTERRUPTED" ;
VAL_ 1860 VCLEFT_systemRecallStatus 0 "SNA" 1 "IN_PROGRESS" 2 "COMPLETE" 3 "INTERRUPTED" ;
VAL_ 1885 CP_chargeCablePresent 0 "NOT_PRESENT" 1 "PRESENT" ;
VAL_ 1885 CP_doorCloseRequest 0 "NONE" 1 "CABLE_UNPLUGGED" 2 "DOOR_OPEN_TIMEOUT" 3 "UI" 4 "SEC" 5 "PUSH_TO_CLOSE" 6 "VEH_LOCK" 7 "CAR_WASH" 8 "FAULT_LINE" 9 "ENTER_DRIVE" 10 "OPENED_IN_DRIVE_STATE" 11 "INITIAL_CINCH" 12 "SENSOR_MISMATCH" 13 "SENSOR_COMMS_RECOVERED" 14 "OPEN_ON_WAKE" 15 "VCFRONT" 16 "NUM" ;
VAL_ 1885 CP_doorCloseEndOfDriveReason 0 "NONE" 1 "LOW_SPEED" 2 "STOPPED_MOVING_TIMEOUT" 3 "REACHED_STOP" 4 "MAX_TARGET_V" 5 "ABSOLUTE_TIMEOUT" 6 "CLOSE_REQ_OVERRIDE" ;
VAL_ 1885 CP_doorOpenEndOfDriveReason 0 "NONE" 1 "LOW_SPEED" 2 "STOPPED_MOVING_TIMEOUT" 3 "REACHED_STOP" 4 "MAX_TARGET_V" 5 "ABSOLUTE_TIMEOUT" 6 "CLOSE_REQ_OVERRIDE" ;
VAL_ 1885 CP_doorOpenRequest 0 "NONE" 1 "UI" 2 "SEC" 3 "UHF" 4 "PUSH_TO_OPEN" 5 "CLOSING_FAILED" 6 "VCFRONT" 7 "CABLE_RECONNECTED" 8 "NUM" ;
VAL_ 1885 CP_UHF_controlState 0 "INIT" 1 "CONFIG" 2 "IDLE" 3 "CALIBRATE" 4 "PREPARE_RX" 5 "RX" 6 "CHECK_RX" 7 "READ_RXFIFO" 8 "HANDLE_FOUND" 9 "SLEEP" 10 "FAULT" ;
VAL_ 1885 CP_loggingFastSelect 0 "0" 1 "1" 2 "2" 3 "3" ;
VAL_ 1928 EPBL_esmCaliperRequest 0 "INVALID" 1 "NONE" 2 "APPLY" 3 "RELEASE" 4 "ENDSTOP" ;
VAL_ 1928 EPBL_pid_duty 127 "SNA" ;
VAL_ 1929 EPBL_vehiclePowerStateDBG 0 "INIT" 1 "LOW_POWER_AWAKE" 2 "CONDITIONING" 3 "ACCESSORY" 4 "ACCESSORY_PLUS" 5 "DRIVE" 6 "OTA" 7 "WAIT_FOR_HIGH_POWER" 8 "TURN_ON_LV" 9 "SYSTEM_CHECKS" 10 "LV_ON" 11 "JUMP_START" 12 "LV_SHUTDOWN" 13 "GO_QUIET" 14 "SLEEP_SHUTDOWN" 15 "LOW_POWER_STANDBY" 16 "RESET" ;
VAL_ 1929 EPBL_lumbarLVState 0 "OFF" 1 "ON" 2 "GOING_DOWN" 3 "FAULT" ;
VAL_ 1929 EPBL_rcmLVState 0 "OFF" 1 "ON" 2 "GOING_DOWN" 3 "FAULT" ;
VAL_ 1943 EPBR_vehiclePowerStateDBG 0 "INIT" 1 "LOW_POWER_AWAKE" 2 "CONDITIONING" 3 "ACCESSORY" 4 "ACCESSORY_PLUS" 5 "DRIVE" 6 "OTA" 7 "WAIT_FOR_HIGH_POWER" 8 "TURN_ON_LV" 9 "SYSTEM_CHECKS" 10 "LV_ON" 11 "JUMP_START" 12 "LV_SHUTDOWN" 13 "GO_QUIET" 14 "SLEEP_SHUTDOWN" 15 "LOW_POWER_STANDBY" 16 "RESET" ;
VAL_ 1943 EPBR_ptcLVState 0 "OFF" 1 "ON" 2 "GOING_DOWN" 3 "FAULT" ;
VAL_ 1943 EPBR_premAudioLVState 0 "OFF" 1 "ON" 2 "GOING_DOWN" 3 "FAULT" ;
VAL_ 1943 EPBR_parkLVState 0 "OFF" 1 "ON" 2 "GOING_DOWN" 3 "FAULT" ;
VAL_ 1943 EPBR_tunerLVState 0 "OFF" 1 "ON" 2 "GOING_DOWN" 3 "FAULT" ;
VAL_ 1943 EPBR_rcmLVState 0 "OFF" 1 "ON" 2 "GOING_DOWN" 3 "FAULT" ;
VAL_ 1944 EPBL_remoteADCIndex 0 "0" 1 "1" 2 "2" 3 "3" 4 "4" 5 "5" ;
VAL_ 1960 EPBR_esmCaliperRequest 0 "INVALID" 1 "NONE" 2 "APPLY" 3 "RELEASE" 4 "ENDSTOP" ;
VAL_ 1960 EPBR_pid_duty 127 "SNA" ;
VAL_ 1976 EPBR_remoteADCIndex 0 "0" 1 "1" 2 "2" 3 "3" 4 "4" 5 "5" ;
VAL_ 1992 EPBL_infoAssemblyId 1 "ASSEMBLY1" 255 "ASSEMBLY_SNA" ;
VAL_ 1992 EPBL_infoBuildType 0 "UNKNOWN_BUILD" 1 "PLATFORM_BUILD" 2 "LOCAL_BUILD" 3 "TRACEABLE_CI_BUILD" 4 "MFG_BUILD" ;
VAL_ 1992 EPBL_infoIndex 0 "DEPRECATED_0" 1 "DEPRECATED_1" 2 "DEPRECATED_2" 3 "DEPRECATED_3" 4 "DEPRECATED_4" 5 "DEPRECATED_5" 6 "DEPRECATED_6" 7 "DEPRECATED_7" 8 "DEPRECATED_8" 9 "DEPRECATED_9" 10 "BUILD_HWID_COMPONENTID" 11 "PCBAID_ASSYID_USAGEID" 13 "APP_CRC" 14 "BOOTLOADER_SVN" 15 "BOOTLOADER_CRC" 16 "SUBCOMPONENT1" 17 "APP_GITHASH" 18 "BOOTLOADER_GITHASH" 19 "VERSION_DEPRECATED" 20 "UDS_PROTOCOL_BOOTCRC" 23 "SUBCOMPONENT2" 24 "SUBCOMPONENT3" 31 "SUBCOMPONENT4" 32 "SUBCOMPONENT5" 33 "SUBCOMPONENT6" 34 "SUBCOMPONENT7" 35 "SUBCOMPONENT8" 36 "SUBCOMPONENT9" 37 "SUBCOMPONENT10" 38 "SUBCOMPONENT11" 39 "SUBCOMPONENT12" 40 "SUBCOMPONENT13" 41 "SUBCOMPONENT14" 255 "END" ;
VAL_ 2004 PMR_debugSelector 64 "Mux64" 128 "Mux128" 66 "Mux66" 67 "Mux67" 131 "Mux131" 68 "Mux68" 132 "Mux132" 69 "Mux69" 70 "Mux70" 72 "Mux72" 32 "Mux32" 33 "Mux33" 34 "Mux34" 35 "Mux35" 36 "Mux36" 37 "Mux37" 38 "Mux38" 39 "Mux39" 40 "Mux40" 41 "Mux41" 42 "Mux42" 43 "Mux43" 46 "Mux46" 47 "Mux47" 48 "Mux48" 49 "Mux49" 50 "Mux50" 52 "Mux52" 63 "Mux63" ;
VAL_ 2024 EPBR_infoAssemblyId 1 "ASSEMBLY1" 255 "ASSEMBLY_SNA" ;
VAL_ 2024 EPBR_infoBuildType 0 "UNKNOWN_BUILD" 1 "PLATFORM_BUILD" 2 "LOCAL_BUILD" 3 "TRACEABLE_CI_BUILD" 4 "MFG_BUILD" ;
VAL_ 2024 EPBR_infoIndex 0 "DEPRECATED_0" 1 "DEPRECATED_1" 2 "DEPRECATED_2" 3 "DEPRECATED_3" 4 "DEPRECATED_4" 5 "DEPRECATED_5" 6 "DEPRECATED_6" 7 "DEPRECATED_7" 8 "DEPRECATED_8" 9 "DEPRECATED_9" 10 "BUILD_HWID_COMPONENTID" 11 "PCBAID_ASSYID_USAGEID" 13 "APP_CRC" 14 "BOOTLOADER_SVN" 15 "BOOTLOADER_CRC" 16 "SUBCOMPONENT1" 17 "APP_GITHASH" 18 "BOOTLOADER_GITHASH" 19 "VERSION_DEPRECATED" 20 "UDS_PROTOCOL_BOOTCRC" 23 "SUBCOMPONENT2" 24 "SUBCOMPONENT3" 31 "SUBCOMPONENT4" 32 "SUBCOMPONENT5" 33 "SUBCOMPONENT6" 34 "SUBCOMPONENT7" 35 "SUBCOMPONENT8" 36 "SUBCOMPONENT9" 37 "SUBCOMPONENT10" 38 "SUBCOMPONENT11" 39 "SUBCOMPONENT12" 40 "SUBCOMPONENT13" 41 "SUBCOMPONENT14" 255 "END" ;
